VERSION "FL_PT_CANFD"

NS_ :

BS_:

BU_: EMS_ICE EMS_PHEV FLZCU FMCU PDCS1 PDCS2 RMCU RXCU TCU_PHEV TCUR TESTER

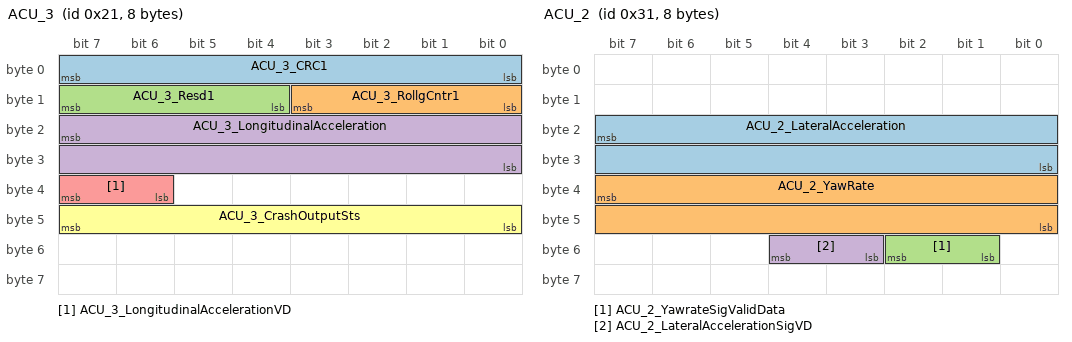
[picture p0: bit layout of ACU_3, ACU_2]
BO_ 33 ACU_3: 8 FLZCU
 SG_ ACU_3_CRC1 : 7|8@0+ (1,0) [0|255] "" RXCU
 SG_ ACU_3_RollgCntr1 : 11|4@0+ (1,0) [0|14] "" RXCU
 SG_ ACU_3_Resd1 : 15|4@0+ (1,0) [0|15] "" RXCU
 SG_ ACU_3_LongitudinalAcceleration : 23|16@0+ (0.001,-2) [-2|2] "g" RXCU
 SG_ ACU_3_LongitudinalAccelerationVD : 39|2@0+ (1,0) [0|3] "" RXCU
 SG_ ACU_3_CrashOutputSts : 47|8@0+ (1,0) [0|255] "" RXCU

BO_ 49 ACU_2: 8 FLZCU
 SG_ ACU_2_LateralAcceleration : 23|16@0+ (0.001,-2) [-2|2] "g" RXCU
 SG_ ACU_2_YawRate : 39|16@0+ (0.01,-180) [-180|180] "deg/sec" RXCU
 SG_ ACU_2_YawrateSigValidData : 50|2@0+ (1,0) [0|3] "" RXCU
 SG_ ACU_2_LateralAccelerationSigVD : 52|2@0+ (1,0) [0|3] "" RXCU

BO_ 152 ONEBOX_1: 24 FLZCU
 SG_ ABS_ESP_1_ABSFailSts : 24|1@0+ (1,0) [0|1] "" RXCU
 SG_ ABS_ESP_1_ABSActive : 41|1@0+ (1,0) [0|1] "" RXCU
 SG_ ABS_ESP_1_VDCFailSts : 42|1@0+ (1,0) [0|1] "" RXCU
 SG_ ABS_ESP_1_VDCActive : 43|1@0+ (1,0) [0|1] "" RXCU
 SG_ ABS_ESP_1_TCSFailSts : 44|1@0+ (1,0) [0|1] "" RXCU
 SG_ ABS_ESP_1_TCSActive : 45|1@0+ (1,0) [0|1] "" RXCU
 SG_ ABS_ESP_1_ESPSwitchStatus : 55|1@0+ (1,0) [0|1] "" RXCU

BO_ 168 ONEBOX_2: 24 FLZCU
 SG_ ONEBOX_2_CRC2 : 71|8@0+ (1,0) [0|255] "" RXCU
 SG_ ONEBOX_2_RollgCntr2 : 75|4@0+ (1,0) [0|14] "" RXCU
 SG_ ONEBOX_2_Resd2 : 79|4@0+ (1,0) [0|15] "" RXCU
 SG_ LHFWheelSpeedRPM : 103|16@0+ (0.0625,0) [0|4095.875] "rpm" RXCU
 SG_ RHFWheelSpeedRPM : 119|16@0+ (0.0625,0) [0|4095.875] "rpm" RXCU
 SG_ ONEBOX_2_CRC3 : 135|8@0+ (1,0) [0|255] "" RXCU
 SG_ ONEBOX_2_RollgCntr3 : 139|4@0+ (1,0) [0|14] "" RXCU
 SG_ ONEBOX_2_Resd3 : 143|4@0+ (1,0) [0|15] "" RXCU
 SG_ LHRWheelSpeedRPM_0A8h : 151|16@0+ (0.0625,0) [0|4095.875] "rpm" RXCU
 SG_ RHRWheelSpeedRPM_0A8h : 167|16@0+ (0.0625,0) [0|4095.875] "rpm" RXCU
 SG_ RHFWheelSpeedRPMValidData : 176|1@0+ (1,0) [0|1] "" RXCU
 SG_ LHFWheelSpeedRPMValidData : 177|1@0+ (1,0) [0|1] "" RXCU
 SG_ RHFWheelDriveDirection_0A8h : 180|3@0+ (1,0) [0|7] "" RXCU
 SG_ LHFWheelDriveDirection_0A8h : 183|3@0+ (1,0) [0|7] "" RXCU
 SG_ RHRWheelSpeedRPMValidData : 184|1@0+ (1,0) [0|1] "" RXCU
 SG_ LHRWheelSpeedRPMValidData : 185|1@0+ (1,0) [0|1] "" RXCU
 SG_ RHRWheelDriveDirection_0A8h : 188|3@0+ (1,0) [0|7] "" RXCU
 SG_ LHRWheelDriveDirection_0A8h : 191|3@0+ (1,0) [0|7] "" RXCU

BO_ 277 HCU_28: 48 RXCU
 SG_ HCU_28_CRC1 : 7|8@0+ (1,0) [0|255] "" FMCU
 SG_ HCU_28_RollgCntr1 : 11|4@0+ (1,0) [0|14] "" FMCU
 SG_ HCU_28_Resd1 : 15|4@0+ (1,0) [0|15] "" FMCU
 SG_ HCU_28_FMCUDesiredTorque : 23|12@0+ (0.25,-500) [-500|500] "Nm" FMCU,TCU_PHEV
 SG_ HCU_28_FMCUMaxTorqueLimit : 27|12@0+ (0.25,-500) [-500|500] "Nm" FMCU,TCU_PHEV
 SG_ HCU_28_FMCUMaxTorqueGradient : 47|14@0+ (32,0) [0|524192] "Nm/s" FMCU,TCU_PHEV
 SG_ HCU_28_EngineTorqAct : 49|10@0+ (0.5,-150) [-150|350] "Nm" FMCU
 SG_ HCU_28_CRC2 : 71|8@0+ (1,0) [0|255] "" FMCU
 SG_ HCU_28_RollgCntr2 : 75|4@0+ (1,0) [0|14] "" FMCU
 SG_ HCU_28_Resd2 : 79|4@0+ (1,0) [0|15] "" FMCU
 SG_ HCU_28_FMCUMinTorqueLimit : 87|12@0+ (0.25,-500) [-500|500] "Nm" FMCU,TCU_PHEV
 SG_ HCU_28_FMCUMaxPwrLimit : 91|12@0+ (0.1,0) [0|400] "kw" FMCU
 SG_ HCU_28_FMCUSpdSet : 111|16@0+ (1,-32767) [-32767|32766] "rpm" FMCU,TCU_PHEV
 SG_ HCU_28_FMCUMaxTorqDampgCtl : 127|8@0+ (1,0) [0|253] "Nm" FMCU,TCU_PHEV
 SG_ HCU_28_CRC3 : 135|8@0+ (1,0) [0|255] "" FMCU
 SG_ HCU_28_RollgCntr3 : 139|4@0+ (1,0) [0|14] "" FMCU
 SG_ HCU_28_Resd3 : 143|4@0+ (1,0) [0|15] "" FMCU
 SG_ HCU_28_FMCUMinPwrLimit : 151|12@0+ (0.1,-400) [-400|0] "kw" FMCU
 SG_ HCU_28_FMCURequestedState : 155|4@0+ (1,0) [0|15] "" FMCU,TCU_PHEV
 SG_ HCU_28_FMCUVehMotstRoadSurf : 167|8@0+ (1,0) [0|15] "" FMCU
 SG_ HCU_28_ISGF_ModeReq : 171|4@0+ (1,0) [0|15] "" FMCU,TCU_PHEV
 SG_ HCU_28_PowertrainModeAct : 175|4@0+ (1,0) [0|15] "" FLZCU,FMCU
 SG_ HCU_28_ISGF_TorqSet : 178|11@0+ (0.25,-255) [-255|255] "Nm" FMCU,TCU_PHEV
 SG_ HCU_28_FMCUDampReq : 179|1@0+ (1,0) [0|1] "" FMCU,TCU_PHEV
 SG_ HCU_28_Mode : 183|4@0+ (1,0) [0|15] "" Vector__XXX
 SG_ HCU_28_CRC4 : 199|8@0+ (1,0) [0|255] "" FMCU
 SG_ HCU_28_RollgCntr4 : 203|4@0+ (1,0) [0|14] "" FMCU
 SG_ HCU_28_Resd4 : 207|4@0+ (1,0) [0|15] "" FMCU
 SG_ HCU_28_ISGF_TorqMax : 215|10@0+ (0.25,0) [0|255] "Nm" FMCU,TCU_PHEV
 SG_ HCU_28_ISGF_TorqMin : 217|10@0+ (0.25,-255) [-255|0] "Nm" FMCU,TCU_PHEV
 SG_ HCU_28_EngineSts : 218|1@0+ (1,0) [0|1] "" FMCU
 SG_ HCU_28_SleepAllow : 219|1@0+ (1,0) [0|1] "" FMCU
 SG_ HCU_28_ISGF_DampReq : 220|1@0+ (1,0) [0|1] "" FMCU,TCU_PHEV
 SG_ HCU_28_bEnaEmReq : 221|1@0+ (1,0) [0|1] "" FMCU
 SG_ HCU_28_ISGF_SpdSet : 239|16@0+ (1,-32767) [-32767|32766] "rpm" FMCU,TCU_PHEV
 SG_ HCU_28_ISGF_MaxTorqDampgCtl : 255|8@0+ (1,0) [0|253] "Nm" FMCU,TCU_PHEV
 SG_ HCU_28_CRC5 : 263|8@0+ (1,0) [0|255] "" FMCU
 SG_ HCU_28_RollgCntr5 : 267|4@0+ (1,0) [0|14] "" FMCU
 SG_ HCU_28_Resd5 : 271|4@0+ (1,0) [0|15] "" FMCU
 SG_ HCU_28_NGenrMaxInTqMode : 279|16@0+ (1,-32767) [-32767|32766] "rpm" FMCU
 SG_ HCU_28_ISGF_MaxTorqGradient : 295|14@0+ (32,0) [0|524192] "" FMCU,TCU_PHEV
 SG_ HCU_28_ISGF_Uset : 297|10@0+ (1,0) [0|1021] "V" FMCU
 SG_ HCU_28_ISGF_LimpPwrReq : 319|8@0+ (0.1,0) [0|20] "KW" FMCU
 SG_ HCU_28_CRC6 : 327|8@0+ (1,0) [0|255] "" FMCU
 SG_ HCU_28_RollgCntr6 : 331|4@0+ (1,0) [0|14] "" FMCU
 SG_ HCU_28_Resd6 : 335|4@0+ (1,0) [0|15] "" FMCU
 SG_ HCU_28_ISGF_Iset : 343|11@0+ (1,-1023) [-1023|1021] "A" FMCU
 SG_ HCU_28_MaxDisCurrent_ISGF : 348|15@0+ (0.05,0) [0|1023] "A" FMCU
 SG_ HCU_28_MaxCharCurrent_ISGF : 365|15@0+ (0.05,-1023) [-1023|0] "A" FMCU
 SG_ HCU_FMCUBoostReq : 378|2@0+ (1,0) [0|3] "" FMCU
 SG_ HCU_P3_TorqueAllowed : 379|1@0+ (1,0) [0|1] "" FMCU
 SG_ HCU_P1_TorqueAllowed : 380|1@0+ (1,0) [0|1] "" FMCU
 SG_ HCU_28_NeutralGearSlide : 381|1@0+ (1,0) [0|1] "" FMCU
 SG_ HCU_28_FMCU_LimpReq : 382|1@0+ (1,0) [0|1] "" FMCU

BO_ 279 HCU_29: 64 RXCU
 SG_ HCU_29_CRC1 : 7|8@0+ (1,0) [0|255] "" RMCU,TCUR
 SG_ HCU_29_RollgCntr1 : 11|4@0+ (1,0) [0|14] "" RMCU,TCUR
 SG_ HCU_29_Resd1 : 15|4@0+ (1,0) [0|15] "" RMCU,TCUR
 SG_ HCU_29_RMCUDesiredTorque : 23|12@0+ (0.25,-500) [-500|500] "Nm" RMCU,TCUR
 SG_ HCU_29_RMCUMaxTorqueLimit : 27|12@0+ (0.25,-500) [-500|500] "Nm" RMCU
 SG_ HCU_29_RMCUMaxTorqueGradient : 47|14@0+ (32,0) [0|524192] "Nm/s" Vector__XXX
 SG_ HCU_29_LowPwrReq : 48|1@0+ (1,0) [0|1] "" RMCU
 SG_ HCU_29_RMCUDrvHeatReq : 49|1@0+ (1,0) [0|1] "" RMCU
 SG_ HCU_29_RMCUVehMotstRoadSurf : 63|8@0+ (1,0) [0|15] "" Vector__XXX
 SG_ HCU_29_CRC2 : 71|8@0+ (1,0) [0|255] "" RMCU,TCUR
 SG_ HCU_29_RollgCntr2 : 75|4@0+ (1,0) [0|14] "" RMCU,TCUR
 SG_ HCU_29_Resd2 : 79|4@0+ (1,0) [0|15] "" RMCU,TCUR
 SG_ HCU_29_RMCUMinTorqueLimit : 87|12@0+ (0.25,-500) [-500|500] "Nm" RMCU
 SG_ HCU_29_RMCUMaxPwrLimit : 91|12@0+ (0.1,0) [0|400] "kw" Vector__XXX
 SG_ HCU_RMCU_ActiveHeatHvDcFreqReq : 111|11@0+ (1,0) [0|1500] "Hz" RMCU
 SG_ HCU_29_RearEDLReq : 115|3@0+ (1,0) [0|7] "" RMCU
 SG_ HCU_P4_TorqueAllowed : 116|1@0+ (1,0) [0|1] "" RMCU
 SG_ HCU_29_RMCUMaxTorqueDampgCtl_Res : 127|8@0+ (1,0) [0|253] "Nm" RMCU
 SG_ HCU_29_CRC3 : 135|8@0+ (1,0) [0|255] "" RMCU,TCUR
 SG_ HCU_29_RollgCntr3 : 139|4@0+ (1,0) [0|14] "" RMCU,TCUR
 SG_ HCU_29_Resd3 : 143|4@0+ (1,0) [0|15] "" RMCU,TCUR
 SG_ HCU_29_RMCUSpdSet : 151|16@0+ (1,-32767) [-32767|32766] "rpm" RMCU
 SG_ HCU_29_RMCUMinPwrLimit : 167|12@0+ (0.1,-400) [-400|0] "kw" Vector__XXX
 SG_ HCU_29_RMCURequestedState : 171|4@0+ (1,0) [0|15] "" RMCU
 SG_ HCU_29_RMCUBoostPwrReq : 183|11@0+ (0.1,0) [0|200] "kw" RMCU
 SG_ HCU_RMCU_LimpReq : 184|1@0+ (1,0) [0|1] "" RMCU
 SG_ HCU_29_RMCUDampReq : 185|1@0+ (1,0) [0|1] "" RMCU
 SG_ HCU_29_RMCUBoostStateReq : 188|3@0+ (1,0) [0|7] "" RMCU
 SG_ HCU_29_CRC4 : 199|8@0+ (1,0) [0|255] "" RMCU,TCUR
 SG_ HCU_29_RollgCntr4 : 203|4@0+ (1,0) [0|14] "" RMCU,TCUR
 SG_ HCU_29_Resd4 : 207|4@0+ (1,0) [0|15] "" RMCU,TCUR
 SG_ HCU_29_RMCU_RequestGear : 209|2@0+ (1,0) [0|3] "" RMCU,TCUR
 SG_ HCU_29_RMCUHeatPwrLimit : 215|6@0+ (0.1,0) [0|5] "Kw" RMCU
 SG_ HCU_RMCU_ActiveHeatHvDcAmpReq : 222|11@0+ (0.25,0) [0|300] "A" RMCU
 SG_ HCU_29_RMCU_ShiftingRequest : 223|1@0+ (1,0) [0|1] "" RMCU,TCUR
 SG_ HCU_RMCU_ActiveHeatHvDcAmpHiLim : 227|11@0+ (0.25,0) [0|300] "A" RMCU
 SG_ HCU_RMCU_ActiveHeatHvDcAmpLoLim : 232|11@0+ (0.25,0) [0|300] "A" RMCU
 SG_ HCU_29_CRC5 : 263|8@0+ (1,0) [0|255] "" Vector__XXX
 SG_ HCU_29_RollgCntr5 : 267|4@0+ (1,0) [0|14] "" Vector__XXX
 SG_ HCU_29_Resd5 : 271|4@0+ (1,0) [0|15] "" Vector__XXX
 SG_ HCU_RMCU_ActiveHeatHvDFreqHiLim : 276|11@0+ (1,0) [0|1500] "Hz" RMCU
 SG_ HCU_29_ADSRMCUTqUnloadEna : 278|2@0+ (1,0) [0|3] "" RMCU,TCUR
 SG_ HCU_RMCU_ActiveHeatHvDcFreqLoLim : 281|11@0+ (1,0) [0|1500] "Hz" RMCU
 SG_ HCU_BMSVehDcChrgnIDmd : 302|14@0+ (0.1,-1024) [-1024|0] "ampere (A)" RMCU
 SG_ HCU_29_NeutralGearSlide : 304|1@0+ (1,0) [0|1] "" RMCU
 SG_ HCU_29_CRC6 : 327|8@0+ (1,0) [0|255] "" Vector__XXX
 SG_ HCU_29_RollgCntr6 : 331|4@0+ (1,0) [0|14] "" Vector__XXX
 SG_ HCU_29_Resd6 : 335|4@0+ (1,0) [0|15] "" Vector__XXX
 SG_ HCU_BMSVehDcChrgnUDmd : 343|14@0+ (0.1,0) [0|1024] "volt (V)" RMCU
 SG_ HCU_DCB_InputVolt : 345|16@0+ (0.05,0) [0|1000] "V" RMCU
 SG_ HCU_DCB_BoostNegRelaySts : 361|3@0+ (1,0) [0|7] "" RMCU
 SG_ HCU_DCB_BoostPosRelaySts : 371|3@0+ (1,0) [0|7] "" RMCU
 SG_ HCU_DCB_C2RelaySts : 374|3@0+ (1,0) [0|7] "" RMCU
 SG_ HCU_29_CRC7 : 391|8@0+ (1,0) [0|255] "" FMCU,RMCU
 SG_ HCU_29_RollgCntr7 : 395|4@0+ (1,0) [0|14] "" FMCU,RMCU
 SG_ HCU_29_Resd7 : 399|4@0+ (1,0) [0|15] "" FMCU,RMCU
 SG_ HCU_29_RMCUDesiredFFTorque : 421|12@0+ (0.25,-500) [-500|500] "Nm" RMCU
 SG_ HCU_29_FMCUDesiredFFTorque : 425|12@0+ (0.25,-500) [-500|500] "Nm" FMCU

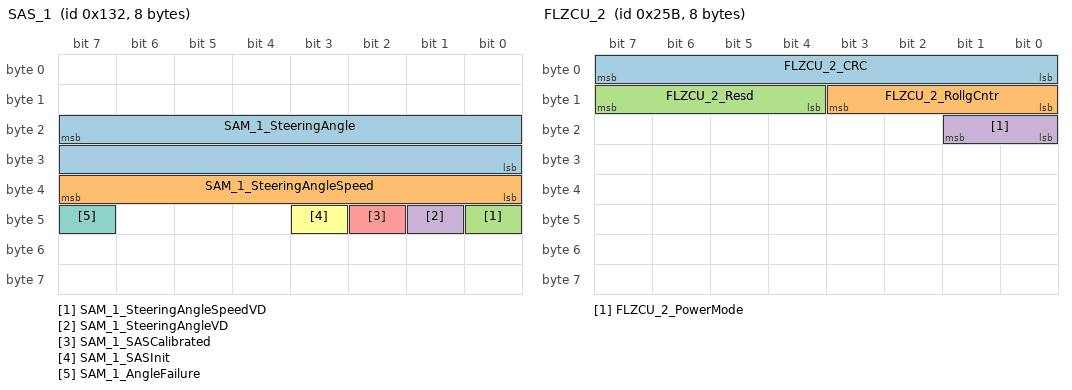
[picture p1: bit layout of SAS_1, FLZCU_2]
BO_ 306 SAS_1: 8 FLZCU
 SG_ SAM_1_SteeringAngle : 23|16@0+ (0.0625,-2048) [-2048|2047.875] "deg" RXCU
 SG_ SAM_1_SteeringAngleSpeed : 39|8@0+ (4,0) [0|1016] "deg/Sec" RXCU
 SG_ SAM_1_SteeringAngleSpeedVD : 40|1@0+ (1,0) [0|1] "" RXCU
 SG_ SAM_1_SteeringAngleVD : 41|1@0+ (1,0) [0|1] "" RXCU
 SG_ SAM_1_SASCalibrated : 42|1@0+ (1,0) [0|1] "" RXCU
 SG_ SAM_1_SASInit : 43|1@0+ (1,0) [0|1] "" RXCU
 SG_ SAM_1_AngleFailure : 47|1@0+ (1,0) [0|1] "" RXCU

BO_ 322 RMCU_7: 16 RXCU
 SG_ RMCU_TCUR_ShiftGearOperSt : 3|4@0+ (1,0) [0|15] "" Vector__XXX
 SG_ TCUR_GearSt : 7|4@0+ (1,0) [0|15] "" Vector__XXX
 SG_ RMCU_TCUR_ShiftGearReq : 10|3@0+ (1,0) [0|7] "" Vector__XXX
 SG_ RMCU_TCUR_RdToSleep : 11|1@0+ (1,0) [0|1] "" Vector__XXX
 SG_ RMCU_GbxStMac : 15|4@0+ (1,0) [0|15] "" Vector__XXX
 SG_ TCUR_GearPosnMeasRaw : 23|8@0+ (1,0) [0|100] "" Vector__XXX
 SG_ TCUR_SleepComfirm : 25|1@0+ (1,0) [0|1] "" Vector__XXX
 SG_ RMCU_MCUGearShiftAllwFlg : 26|1@0+ (1,0) [0|1] "" Vector__XXX
 SG_ TCUR_ActrOperSt : 31|5@0+ (1,0) [0|31] "" Vector__XXX

BO_ 419 HCU_26: 48 RXCU
 SG_ HCU_26_CRC1 : 7|8@0+ (1,0) [0|255] "" EMS_PHEV,TCU_PHEV
 SG_ HCU_26_RollgCntr1 : 11|4@0+ (1,0) [0|14] "" EMS_PHEV,TCU_PHEV
 SG_ HCU_ENG_TorqueAllowed : 12|1@0+ (1,0) [0|1] "" EMS_PHEV
 SG_ HCU_26_TargetGearTransInp : 18|3@0+ (1,0) [0|7] "" TCU_PHEV
 SG_ HCU_26_OptMode : 21|3@0+ (1,0) [0|7] "" TCU_PHEV
 SG_ HCU_26_TargetGearEM2 : 23|2@0+ (1,0) [0|3] "" TCU_PHEV
 SG_ PowertrainModeDes : 27|4@0+ (1,0) [0|15] "" EMS_PHEV,TCU_PHEV
 SG_ HCU_26_FrntEDLReq : 30|3@0+ (1,0) [0|7] "" FMCU,TCU_PHEV
 SG_ HCU_26_InputClutchIntervention : 31|1@0+ (1,0) [0|1] "" TCU_PHEV
 SG_ GasPedalPosition : 39|8@0+ (0.392,0) [0|99.568] "" EMS_PHEV,FMCU,RMCU,TCU_PHEV,TCUR
 SG_ BrakePedalStsValidDataForTCU : 40|1@0+ (1,0) [0|1] "" EMS_PHEV,FMCU,RMCU,TCU_PHEV,TCUR
 SG_ BrakePedalStsForTCU : 41|1@0+ (1,0) [0|1] "" EMS_PHEV,FMCU,RMCU,TCU_PHEV,TCUR
 SG_ GasPedalPositionInvalidData : 42|1@0+ (1,0) [0|1] "" EMS_PHEV,FMCU,RMCU,TCU_PHEV,TCUR
 SG_ TargetGearTransInp : 45|3@0+ (1,0) [0|7] "" TCU_PHEV
 SG_ HCU_26_ADSFMCUTqUnloadEna : 47|2@0+ (1,0) [0|3] "" FMCU
 SG_ HCU_TMCU_EmsTqReqSlow : 55|11@0+ (0.5,-510) [-510|513] "Nm" TCU_PHEV
 SG_ HCU_26_EMS_FuelcutReq : 56|1@0+ (1,0) [0|1] "" TCU_PHEV
 SG_ HCU_TMCU_CntrAllowMode : 60|4@0+ (1,0) [0|15] "" TCU_PHEV
 SG_ HCU_26_CRC2 : 71|8@0+ (1,0) [0|255] "" Vector__XXX
 SG_ HCU_26_RollgCntr2 : 75|4@0+ (1,0) [0|14] "" Vector__XXX
 SG_ HCU_26_Resd2 : 79|4@0+ (1,0) [0|15] "" Vector__XXX
 SG_ HCU_26_IndicatedDriverReqWhlTqFA : 87|16@0+ (1,-32768) [-32768|32767] "Nm" TCU_PHEV
 SG_ HCU_26_ActWheelTorqueFA : 103|16@0+ (1,-32768) [-32768|32767] "Nm" TCU_PHEV
 SG_ HCU_26_ActWheelTorqueRA : 119|16@0+ (1,-32768) [-32768|32767] "NM" TCU_PHEV
 SG_ HCU_26_CRC3 : 135|8@0+ (1,0) [0|255] "" Vector__XXX
 SG_ HCU_26_RollgCntr3 : 139|4@0+ (1,0) [0|14] "" Vector__XXX
 SG_ HCU_26_Resd3 : 143|4@0+ (1,0) [0|15] "" Vector__XXX
 SG_ HCU_AccessoriesCosumePower : 151|14@0+ (0.01,0) [0|100] "KW" Vector__XXX
 SG_ HCU_26_PRNDGearTargetValidData : 152|1@0+ (1,0) [0|1] "" FMCU,TCU_PHEV
 SG_ HCU_26_PRNDGearActValidData : 153|1@0+ (1,0) [0|1] "" FMCU
 SG_ HCU_26_TransInpTarSpd : 167|16@0+ (1,-32767) [-32767|32767] "" TCU_PHEV
 SG_ HCU_26_ADSFMCUTqUnloadRate : 183|9@0+ (50,-12750) [-12750|12800] "Nm/s" FMCU
 SG_ HCU_RearEDDReq_1A3h : 190|2@0+ (1,0) [0|3] "" RMCU
 SG_ HCU_26_TransInpActSpd : 215|16@0+ (1,-32767) [-32767|32767] "" TCU_PHEV
 SG_ HCU_26_TransEM1TrqTar : 231|12@0+ (0.5,-848) [-848|1199] "" TCU_PHEV
 SG_ HCU_26_C1CapacityTarget : 235|12@0+ (0.5,-848) [-848|1199] "" TCU_PHEV
 SG_ HCU_26_PRNDGearTarget : 250|3@0+ (1,0) [0|7] "" TCU_PHEV
 SG_ HCU_26_PRNDGearAct : 253|3@0+ (1,0) [0|7] "" TCU_PHEV
 SG_ HCU_26_ShiftUrgency : 255|2@0+ (1,0) [0|3] "" TCU_PHEV
 SG_ HCU_26_TransInpTrqAct : 279|12@0+ (0.5,-848) [-848|1199] "" TCU_PHEV
 SG_ HCU_26_TransInpTrqTar : 283|12@0+ (0.5,-848) [-848|1199] "" TCU_PHEV
 SG_ HCU_26_TransInpTrqMin : 303|12@0+ (0.5,-848) [-848|1199] "" TCU_PHEV
 SG_ HCU_26_EM2TrqTar : 307|12@0+ (0.5,-848) [-848|1199] "" TCU_PHEV
 SG_ HCU_26_ADSFMCUMotTqRateLimMin : 343|9@0+ (50,-12750) [-12750|12800] "Nm/s" FMCU
 SG_ HCU_26_ADSFMCUMotTqRateLimMax : 350|9@0+ (50,-12750) [-12750|12800] "Nm/s" FMCU
 SG_ HCU_26_Activeheat : 357|1@0+ (1,0) [0|1] "" FMCU
 SG_ HCU_26_ECGPOvrd : 360|1@0+ (1,0) [0|1] "" TCU_PHEV
 SG_ HCU_26_ErrorMotorSpeedRA : 361|1@0+ (1,0) [0|1] "" TCU_PHEV
 SG_ HCU_26_EpsOnReq : 362|1@0+ (1,0) [0|1] "" TCU_PHEV
 SG_ HCU_26_C1CapacityState : 364|2@0+ (1,0) [0|3] "" TCU_PHEV
 SG_ HCU_26_EngineStartType : 367|3@0+ (1,0) [0|7] "" TCU_PHEV
 SG_ HCU_26_FMCUMaxActiveheatPwr : 374|7@0+ (0.1,0) [0|11.1] "KW" FMCU
 SG_ HCU_26_ECGPOvrdInvalidData : 375|1@0+ (1,0) [0|1] "" TCU_PHEV

BO_ 474 FMCU_8: 64 FMCU
 SG_ FMCU_8_CRC1 : 7|8@0+ (1,0) [0|255] "" RXCU
 SG_ FMCU_8_RollgCntr1 : 11|4@0+ (1,0) [0|14] "" RXCU
 SG_ FMCU_8_Resd1 : 15|4@0+ (1,0) [0|15] "" RXCU
 SG_ FMCU_8_TorqMax : 23|12@0+ (0.25,0) [0|400] "Nm" RXCU
 SG_ FMCU_8_TorqMin : 27|12@0+ (0.25,-400) [-400|0] "Nm" RXCU
 SG_ FMCU_8_TorqAct : 47|12@0+ (0.25,-400) [-400|400] "Nm" RXCU
 SG_ FMCU_8ModeSt : 51|4@0+ (1,0) [0|15] "" RXCU
 SG_ FMCU_8_FMCUDeratSts : 59|4@0+ (1,0) [0|15] "" RXCU
 SG_ FMCU_8_ErrLvl : 62|3@0+ (1,0) [0|7] "" RXCU
 SG_ FMCU_8_DampActive : 63|1@0+ (1,0) [0|1] "" RXCU
 SG_ FMCU_8_CRC2 : 71|8@0+ (1,0) [0|255] "" RXCU
 SG_ FMCU_8_RollgCntr2 : 75|4@0+ (1,0) [0|14] "" RXCU
 SG_ FMCU_8_Resd2 : 79|4@0+ (1,0) [0|15] "" RXCU
 SG_ FMCU_8_SpdAct : 87|16@0+ (1,-32767) [-32767|32766] "rpm" RXCU
 SG_ FMCU_8_TrqActDampingReq : 103|12@0+ (0.25,-350) [-350|350] "Nm" RXCU
 SG_ FMCU_8_UdcAct : 107|10@0+ (1,0) [0|1021] "V" RXCU
 SG_ FMCU_8_ISGF_DampActive : 112|1@0+ (1,0) [0|1] "" RXCU
 SG_ FMCU_8_InterlockStatus : 113|1@0+ (1,0) [0|1] "" RXCU
 SG_ FMCU_8_ISGF_ErrLvl : 123|4@0+ (1,0) [0|15] "" RXCU
 SG_ FMCU_8_ISGF_ModeSt : 127|4@0+ (1,0) [0|15] "" RXCU
 SG_ FMCU_8_CRC3 : 135|8@0+ (1,0) [0|255] "" RXCU
 SG_ FMCU_8_RollgCntr3 : 139|4@0+ (1,0) [0|14] "" RXCU
 SG_ FMCU_8_Resd3 : 143|4@0+ (1,0) [0|15] "" RXCU
 SG_ FMCU_8_IdcAct : 151|11@0+ (1,-1023) [-1023|1021] "A" RXCU
 SG_ FMCU_8_ISGF_SpdAct : 156|16@0+ (1,-32767) [-32767|32766] "rpm" RXCU
 SG_ FMCU_8_ISGF_TorqMax : 172|10@0+ (0.25,0) [0|255] "Nm" RXCU
 SG_ FMCU_8_ISGF_TorqAct : 178|11@0+ (0.25,-255) [-255|255] "Nm" RXCU
 SG_ FMCU_8_CRC4 : 199|8@0+ (1,0) [0|255] "" RXCU
 SG_ FMCU_8_RollgCntr4 : 203|4@0+ (1,0) [0|14] "" RXCU
 SG_ FMCU_8_Resd4 : 207|4@0+ (1,0) [0|15] "" RXCU
 SG_ FMCU_8_ISGF_TorqMin : 215|10@0+ (0.25,-255) [-255|0] "Nm" RXCU
 SG_ FMCU_8_ISGF_IdcAct : 221|11@0+ (1,-1023) [-1023|1021] "A" RXCU
 SG_ FMCU_8_ISGF_UdcAct : 236|10@0+ (1,0) [0|1021] "V" RXCU
 SG_ FMCU_8_ActiveheatReq : 240|1@0+ (1,0) [0|1] "" RXCU
 SG_ FMCU_8_ISGF_DischargeState : 242|2@0+ (1,0) [0|3] "" RXCU
 SG_ FMCU_8_CRC5 : 263|8@0+ (1,0) [0|255] "" RXCU
 SG_ FMCU_8_RollgCntr5 : 267|4@0+ (1,0) [0|14] "" RXCU
 SG_ FMCU_8_Resd5 : 271|4@0+ (1,0) [0|15] "" RXCU
 SG_ FMCU_8_ISGF_TrqActDampingReq : 279|11@0+ (0.25,-255) [-255|255] "Nm" RXCU
 SG_ FMCU_8_ISGF_GateDrvSt : 284|2@0+ (1,0) [0|3] "" RXCU
 SG_ FMCU_8_LimpAllow : 312|1@0+ (1,0) [0|1] "" RXCU
 SG_ FMCU_8_Limp : 313|1@0+ (1,0) [0|1] "" RXCU
 SG_ FMCU_8_CRC6 : 327|8@0+ (1,0) [0|255] "" RXCU
 SG_ FMCU_8_RollgCntr6 : 331|4@0+ (1,0) [0|14] "" RXCU
 SG_ FMCU_8_Resd6 : 335|4@0+ (1,0) [0|15] "" RXCU
 SG_ FMCU_8_InvTemp : 343|8@0+ (1,-40) [-40|213] "oC" RXCU
 SG_ FMCU_8_ISGF_InvTemp : 351|8@0+ (1,-40) [-40|213] "oC" RXCU
 SG_ FMCU_8_MCUActRUnfilteredRodSpd : 359|16@0+ (1,-30000) [-30000|35535] "RPM" RXCU
 SG_ FMCU_8_MCUReqTq : 375|13@0+ (0.25,-800) [-800|800] "Nm" RXCU
 SG_ FMCU_8_MCUModActvSt : 377|2@0+ (1,0) [0|3] "" RXCU
 SG_ FMCU_8_SpdSvModAvl : 378|1@0+ (1,0) [0|1] "" RXCU
 SG_ FMCU_E_ClutchStus : 397|2@0+ (1,0) [0|3] "" RXCU
 SG_ FMCU_E_ClutchEngMilLampReq : 399|2@0+ (1,0) [0|3] "" RXCU
 SG_ FMCU_8_MCUSpdSVModFlt : 402|3@0+ (1,0) [0|7] "" RXCU
 SG_ FMCU_8_MCUVehSldSt : 403|1@0+ (1,0) [0|1] "" RXCU
 SG_ FMCU_8_MCUStandstill : 404|1@0+ (1,0) [0|1] "" RXCU
 SG_ FMCU_8_MCUBlkSt : 407|3@0+ (1,0) [0|7] "" RXCU
 SG_ FMCU_8_ISGActRUnfilteredRodSpd : 415|16@0+ (1,-30000) [-30000|35535] "RPM" RXCU
 SG_ FMCU_8_ISGReqTq : 431|13@0+ (0.25,-800) [-800|800] "Nm" RXCU
 SG_ FMCU_8_ISGModActvSt : 433|2@0+ (1,0) [0|3] "" RXCU
 SG_ FMCU_8_ISGSpdSvModAvl : 434|1@0+ (1,0) [0|1] "" RXCU
 SG_ FMCU_8_ISGSpdSVModFlt : 442|3@0+ (1,0) [0|7] "" RXCU
 SG_ FMCU_8_ISGVehSldSt : 443|1@0+ (1,0) [0|1] "" RXCU
 SG_ FMCU_8_ISGStandstill : 444|1@0+ (1,0) [0|1] "" RXCU
 SG_ FMCU_8_ISGBlkSt : 447|3@0+ (1,0) [0|7] "" RXCU
 SG_ FMCU_E_ClutchErrLvl : 462|3@0+ (1,0) [0|7] "" RXCU
 SG_ FMCU_8_MCU_SpdActValidData : 464|1@0+ (1,0) [0|1] "" RXCU
 SG_ FMCU_8_ActiveheatPwrAct : 471|7@0+ (0.1,0) [0|11.1] "KW" RXCU
 SG_ FMCU_E_ClutchCurr : 472|10@0+ (0.01,0) [0|10] "" RXCU
 SG_ FMCU_E_ClutchActMod : 475|3@0+ (1,0) [0|7] "" RXCU
 SG_ FMCU_8_ISGF_PositionCtrSts : 478|3@0+ (1,0) [0|7] "" RXCU
 SG_ FMCU_8_ISGF_SpdAcValidData : 479|1@0+ (1,0) [0|1] "" RXCU
 SG_ ECluAvlTq : 494|10@0+ (0.5,0) [0|511] "Nm" RXCU

BO_ 485 RMCU_1: 48 RXCU
 SG_ RMCU_1_CRC1 : 7|8@0+ (1,0) [0|255] "" FLZCU,PDCS1,PDCS2
 SG_ RMCU_1_RollgCntr1 : 11|4@0+ (1,0) [0|14] "" FLZCU,PDCS1,PDCS2
 SG_ RMCU_1_Resd1 : 15|4@0+ (1,0) [0|15] "" FLZCU,PDCS1,PDCS2
 SG_ RMCU_MaxTorque : 23|12@0+ (0.25,0) [0|500] "Nm" FLZCU,PDCS1,PDCS2
 SG_ RMCU_MinTorque : 27|12@0+ (0.25,-500) [-500|0] "Nm" FLZCU,PDCS1,PDCS2
 SG_ RMCU_1_OutputTorque : 47|12@0+ (0.25,-500) [-500|500] "Nm" FLZCU,PDCS1,PDCS2
 SG_ RMCU_State : 51|4@0+ (1,0) [0|15] "" FLZCU,PDCS1,PDCS2
 SG_ RMCU_1_InverterTemperature : 63|8@0+ (1,-40) [-40|213] "oC" FLZCU,PDCS1,PDCS2
 SG_ RMCU_1_CRC2 : 71|8@0+ (1,0) [0|255] "" FLZCU,PDCS1,PDCS2
 SG_ RMCU_1_RollgCntr2 : 75|4@0+ (1,0) [0|14] "" FLZCU,PDCS1,PDCS2
 SG_ RMCU_1_Resd2 : 79|4@0+ (1,0) [0|15] "" FLZCU,PDCS1,PDCS2
 SG_ RMCU_TrqActDampingReq : 87|12@0+ (0.25,-500) [-500|500] "Nm" FLZCU,PDCS1,PDCS2
 SG_ RMCU_RMCUDeratSts : 91|4@0+ (1,0) [0|15] "" FLZCU,PDCS1,PDCS2
 SG_ RMCU_1_VoltageHV : 103|10@0+ (1,0) [0|1021] "V" FLZCU,PDCS1,PDCS2
 SG_ RMCU_ElockWorkStatusAct : 107|4@0+ (1,0) [0|15] "" FLZCU,PDCS1,PDCS2
 SG_ RMCU_1_MCU_SpdActValidData : 109|1@0+ (1,0) [0|1] "" FLZCU,PDCS1,PDCS2
 SG_ RMCU_1_Speed : 119|16@0+ (1,-32767) [-32767|32766] "rpm" FLZCU,PDCS1,PDCS2
 SG_ RMCU_1_CRC3 : 135|8@0+ (1,0) [0|255] "" FLZCU,PDCS1,PDCS2
 SG_ RMCU_1_RollgCntr3 : 139|4@0+ (1,0) [0|14] "" FLZCU,PDCS1,PDCS2
 SG_ RMCU_1_Resd3 : 143|4@0+ (1,0) [0|15] "" FLZCU,PDCS1,PDCS2
 SG_ RMCU_1_MAXBoostPwr : 151|10@0+ (0.25,0) [0|130] "KW" FLZCU,PDCS1,PDCS2
 SG_ RMCU_ErrLvl : 154|3@0+ (1,0) [0|7] "" FLZCU,PDCS1,PDCS2
 SG_ RMCU_1_BoostSts : 157|3@0+ (1,0) [0|7] "" FLZCU,PDCS1,PDCS2
 SG_ RMCU_1_CurrentHV : 167|11@0+ (1,-1023) [-1023|1021] "A" FLZCU,PDCS1,PDCS2
 SG_ RMCU_HeatPwrAct : 172|9@0+ (0.1,0) [0|5] "Kw" FLZCU,PDCS1,PDCS2
 SG_ RMCU_MAXHeatPwr : 179|9@0+ (0.1,0) [0|5] "Kw" FLZCU,PDCS1,PDCS2
 SG_ RMCU_DampActive : 184|1@0+ (1,0) [0|1] "" FLZCU,PDCS1,PDCS2
 SG_ RMCU_InterlockStatus : 185|1@0+ (1,0) [0|1] "" FLZCU,PDCS1,PDCS2
 SG_ RMCU_1_SpdSvModAvl : 186|1@0+ (1,0) [0|1] "" FLZCU,PDCS1,PDCS2
 SG_ RMCU_1_CRC4 : 199|8@0+ (1,0) [0|255] "" FLZCU,PDCS1,PDCS2
 SG_ RMCU_1_RollgCntr4 : 203|4@0+ (1,0) [0|14] "" FLZCU,PDCS1,PDCS2
 SG_ RMCU_1_Resd4 : 207|4@0+ (1,0) [0|15] "" FLZCU,PDCS1,PDCS2
 SG_ RMCU_1_MCUModActvSt : 209|2@0+ (1,0) [0|3] "" FLZCU,PDCS1,PDCS2
 SG_ RMCU_1_BSTNRelayReqAct : 212|3@0+ (1,0) [0|7] "" FLZCU,PDCS1,PDCS2
 SG_ RMCU_1_BSTPRelayReqAct : 215|3@0+ (1,0) [0|7] "" FLZCU,PDCS1,PDCS2
 SG_ RMCU_1_MCUStandstill : 216|1@0+ (1,0) [0|1] "" FLZCU,PDCS1,PDCS2
 SG_ RMCU_1_MCUVehSldSt : 217|1@0+ (1,0) [0|1] "" FLZCU,PDCS1,PDCS2
 SG_ RMCU_1_BoostErrLvl : 220|3@0+ (1,0) [0|7] "" FLZCU,PDCS1,PDCS2
 SG_ RMCU_1_BSTPrechargeRelayAct : 223|3@0+ (1,0) [0|7] "" FLZCU,PDCS1,PDCS2
 SG_ RMCU_1_NeutralGearUnavailable : 224|1@0+ (1,0) [0|1] "" FLZCU,PDCS1,PDCS2
 SG_ RMCU_1_GearShiftProgFlag : 226|2@0+ (1,0) [0|3] "" FLZCU,PDCS1,PDCS2
 SG_ RMCU_1_GearShiftAllw : 227|1@0+ (1,0) [0|1] "" FLZCU,PDCS1,PDCS2
 SG_ RMCU_1_CurrGear : 231|4@0+ (1,0) [0|15] "" FLZCU,PDCS1,PDCS2
 SG_ RMCU_1_GearSelfStudySts : 234|3@0+ (1,0) [0|7] "" FLZCU,PDCS1,PDCS2
 SG_ RMCU_1_TCURErrLvlDis : 237|3@0+ (1,0) [0|7] "" FLZCU,PDCS1,PDCS2
 SG_ RMCU_1_2ndGearUnavailable : 238|1@0+ (1,0) [0|1] "" FLZCU,PDCS1,PDCS2
 SG_ RMCU_1_1stGearUnavailable : 239|1@0+ (1,0) [0|1] "" FLZCU,PDCS1,PDCS2
 SG_ RMCU_1_MCUActRUnfilteredRodSpd : 247|16@0+ (1,-30000) [-30000|35535] "RPM" FLZCU,PDCS1,PDCS2
 SG_ RMCU_1_CRC5 : 263|8@0+ (1,0) [0|255] "" Vector__XXX
 SG_ RMCU_1_RollgCntr5 : 267|4@0+ (1,0) [0|14] "" Vector__XXX
 SG_ RMCU_1_ActiveHeatHvDcAmpAct : 277|11@0+ (0.25,0) [0|300] "A" FLZCU,PDCS1,PDCS2
 SG_ RMCU_1_LimpAllow : 278|1@0+ (1,0) [0|1] "" FLZCU,PDCS1,PDCS2
 SG_ RMCU_1_ShiftReqProtd : 279|1@0+ (1,0) [0|1] "" FLZCU,PDCS1,PDCS2
 SG_ RMCU_1_ActiveHeatHvDcFreqAct : 282|11@0+ (1,0) [0|1500] "Hz" FLZCU,PDCS1,PDCS2
 SG_ RMCU_1_MCUReqTq : 303|13@0+ (0.25,-800) [-800|800] "Nm" FLZCU,PDCS1,PDCS2
 SG_ RMCU_1_MCUBlkSt : 306|3@0+ (1,0) [0|7] "" FLZCU,PDCS1,PDCS2
 SG_ RMCU_GBFaultstatus : 313|2@0+ (1,0) [0|3] "" FLZCU
 SG_ RMCU_1_RotorPosition : 315|2@0+ (1,0) [0|3] "" FLZCU,PDCS1,PDCS2
 SG_ RMCU_1_MCUSpdSVModFlt : 318|3@0+ (1,0) [0|7] "" FLZCU,PDCS1,PDCS2
 SG_ RMCU_1_CRC6 : 327|8@0+ (1,0) [0|255] "" Vector__XXX
 SG_ RMCU_1_RollgCntr6 : 331|4@0+ (1,0) [0|14] "" Vector__XXX
 SG_ RMCU_EDD_RearEDDStMac : 336|4@0+ (1,0) [0|15] "" Vector__XXX
 SG_ RMCU_EDD_RearEDDOperSt : 340|4@0+ (1,0) [0|15] "" Vector__XXX
 SG_ RMCU_EDD_RearEDDSts : 343|3@0+ (1,0) [0|7] "" PDCS1,PDCS2
 SG_ RMCU_EDD_RearEDDFaultCode : 348|6@0+ (1,0) [0|63] "" Vector__XXX
 SG_ RMCU_EDD_RearEDDCnctDisAllwReas : 353|3@0+ (1,0) [0|7] "" Vector__XXX
 SG_ RMCU_EDD_RearEDDConnectAllwFlg : 355|2@0+ (1,0) [0|3] "" PDCS1,PDCS2
 SG_ RMCU_EDD_RearEDDErrLvlDis : 358|3@0+ (1,0) [0|7] "" Vector__XXX
 SG_ RMCU_EDD_RearEDDPosnMeasRaw : 366|8@0+ (1,0) [0|100] "" Vector__XXX

BO_ 501 FMCU_9_JT: 8 FMCU
 SG_ FMCU_NegTrqAvailMin_2s : 23|13@0+ (0.25,-350) [-350|0] "" RXCU
 SG_ FMCU_PosTrqAvailMax_2s : 26|13@0+ (0.25,0) [0|350] "" RXCU

BO_ 504 HCU_4: 24 RXCU
 SG_ HCU_4_CRC1 : 7|8@0+ (1,0) [0|255] "" EMS_PHEV,TCU_PHEV
 SG_ HCU_4_RollgCntr1 : 11|4@0+ (1,0) [0|14] "" EMS_PHEV,TCU_PHEV
 SG_ HCU_4_Resd1 : 15|4@0+ (1,0) [0|15] "" EMS_PHEV,TCU_PHEV
 SG_ HCU_EMS_EngineIdleSpeedMin : 23|8@0+ (10,0) [0|2540] "rpm" EMS_PHEV
 SG_ HCU_EMS_EngIdleTorqueCtrl : 31|8@0+ (0.5,0) [0|127] "Nm" EMS_PHEV
 SG_ HCU_EMS_TqReqFast : 39|10@0+ (0.5,-150) [-150|350] "Nm" EMS_PHEV,TCU_PHEV
 SG_ HCU_EMS_TqReqSlow : 45|10@0+ (0.5,-150) [-150|350] "Nm" EMS_PHEV,TCU_PHEV
 SG_ HCU_EMS_StopReq : 48|1@0+ (1,0) [0|1] "" EMS_PHEV
 SG_ HCU_EMS_ImmoSts : 49|1@0+ (1,0) [0|1] "" EMS_PHEV
 SG_ FuelCutOffInhibit : 50|1@0+ (1,0) [0|1] "" Vector__XXX
 SG_ FuelCutOffEnable : 51|1@0+ (1,0) [0|1] "" EMS_PHEV
 SG_ AntiJerkActive : 56|1@0+ (1,0) [0|1] "" Vector__XXX
 SG_ DriveSystemActive : 57|1@0+ (1,0) [0|1] "" Vector__XXX
 SG_ HCU_EMS_FuelcutReq : 58|1@0+ (1,0) [0|1] "" EMS_PHEV
 SG_ HCU_EMS_EpsOnReq : 59|1@0+ (1,0) [0|1] "" Vector__XXX
 SG_ HCU_EMS_bPepsEngRun : 60|1@0+ (1,0) [0|1] "" EMS_PHEV
 SG_ EngineFastTorqReqStatus : 61|1@0+ (1,0) [0|1] "" EMS_PHEV,TCU_PHEV
 SG_ HCU_EMS_MILReq : 62|1@0+ (1,0) [0|1] "" Vector__XXX
 SG_ CrankStartReleaseState : 63|1@0+ (1,0) [0|1] "" EMS_PHEV
 SG_ HCU_4_CRC2 : 71|8@0+ (1,0) [0|255] "" EMS_PHEV
 SG_ HCU_4_RollgCntr2 : 75|4@0+ (1,0) [0|14] "" EMS_PHEV
 SG_ HCU_4_Resd2 : 79|4@0+ (1,0) [0|15] "" EMS_PHEV
 SG_ HCU_EMS_SpdSet : 87|16@0+ (0.25,0) [0|16383] "rpm" EMS_PHEV
 SG_ EM1ActSpd : 103|16@0+ (1,-32767) [-32767|32765] "RPM" EMS_PHEV
 SG_ TransEM1TrqAct : 119|12@0+ (0.5,-848) [-848|1199] "Nm" EMS_PHEV
 SG_ HCU_EMS_SpdCtrl : 120|1@0+ (1,0) [0|1] "" EMS_PHEV
 SG_ EngineStartType : 123|3@0+ (1,0) [0|7] "" EMS_PHEV
 SG_ HCU_4_CRC3 : 135|8@0+ (1,0) [0|255] "" EMS_PHEV
 SG_ HCU_4_RollgCntr3 : 139|4@0+ (1,0) [0|14] "" EMS_PHEV
 SG_ HCU_4_Resd3 : 143|4@0+ (1,0) [0|15] "" EMS_PHEV
 SG_ EM1TrqMax : 151|12@0+ (0.5,-848) [-848|1199] "Nm" Vector__XXX
 SG_ PowertrainModeAct : 155|4@0+ (1,0) [0|15] "" EMS_PHEV,TCU_PHEV
 SG_ MotorReadyFA : 164|1@0+ (1,0) [0|1] "" Vector__XXX
 SG_ ICEReady : 165|1@0+ (1,0) [0|1] "" Vector__XXX
 SG_ EngineSlowTorqReqStatus : 166|1@0+ (1,0) [0|1] "" EMS_PHEV
 SG_ HCU_14_DashPotActive : 167|1@0+ (1,0) [0|1] "" EMS_PHEV
 SG_ HCU_EMS_WaterPumpDutyReq : 175|7@0+ (1,0) [0|100] "%" EMS_PHEV

BO_ 520 BMS_2: 48 FLZCU
 SG_ BMS_2_CRC1 : 7|8@0+ (1,0) [0|255] "" RXCU
 SG_ BMS_2_RollgCntr1 : 11|4@0+ (1,0) [0|14] "" RXCU
 SG_ BMS_2_Resd1 : 15|4@0+ (1,0) [0|15] "" RXCU
 SG_ BMS_C2Target_Chg_Voltage : 23|16@0+ (0.1,0) [0|1000] "V" RXCU
 SG_ BMS_NV_relay_Sts : 84|3@0+ (1,0) [0|7] "" RXCU
 SG_ BMS_PV_relay_Sts : 87|3@0+ (1,0) [0|7] "" RXCU
 SG_ BMS_QCP_relay_Sts : 90|3@0+ (1,0) [0|7] "" RXCU
 SG_ BMS_Prechage_relay_Sts : 98|3@0+ (1,0) [0|7] "" RXCU
 SG_ BMS_OutPosU : 223|14@0+ (0.1,0) [0|1023.0] "volt(V)" RXCU
 SG_ BMS_outQCPosU : 279|14@0+ (0.1,0) [0|1023.0] "volt(V)" RXCU

BO_ 522 EMS_7: 32 EMS_PHEV
 SG_ EMS_7_EngTqLimReqTq : 23|9@0+ (1,-50) [-50|400] "Nm" RXCU
 SG_ EMS_7_EngStartInh : 25|2@0+ (1,0) [0|3] "" RXCU
 SG_ EMS_7_VentValve : 27|2@0+ (1,0) [0|3] "" RXCU
 SG_ EMS_7_AirIntakeValve : 29|2@0+ (1,0) [0|3] "" RXCU
 SG_ EMS_7_DiagcTqLimActvnFlg : 30|1@0+ (1,0) [0|1] "" RXCU
 SG_ EMS_7_CrkShftPosition : 47|7@0+ (1,0) [0|120] "" RXCU

BO_ 523 BMS_3: 48 FLZCU
 SG_ BMS_HvBattPMaxReChrgLim : 39|14@0+ (0.1,0) [0|1024] "kW" RXCU
 SG_ BMS_HvBattPMaxDchaLim : 119|14@0+ (0.1,0) [0|1024] "kW" RXCU
 SG_ BMSH_MaxChgPwrPeak : 343|12@0+ (0.1,0) [0|320] "KW" RXCU
 SG_ BMSH_MaxDchgPwrPeak : 347|12@0+ (0.1,0) [0|320] "KW" RXCU

BO_ 603 FLZCU_2: 8 FLZCU
 SG_ FLZCU_2_CRC : 7|8@0+ (1,0) [0|255] "" RXCU
 SG_ FLZCU_2_RollgCntr : 11|4@0+ (1,0) [0|14] "" RXCU
 SG_ FLZCU_2_Resd : 15|4@0+ (1,0) [0|15] "" RXCU
 SG_ FLZCU_2_PowerMode : 17|2@0+ (1,0) [0|3] "" RXCU

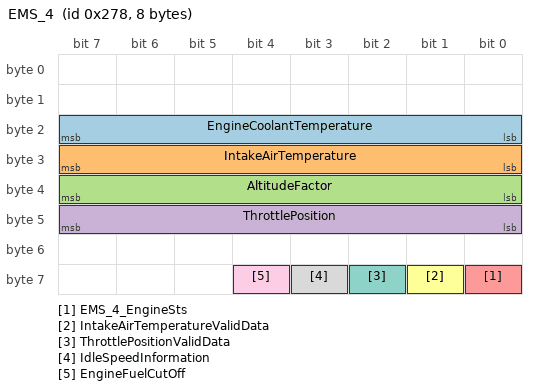
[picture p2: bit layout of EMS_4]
BO_ 632 EMS_4: 8 EMS_PHEV
 SG_ EngineCoolantTemperature : 23|8@0+ (0.75,-48) [-48|142.5] "°C" RXCU
 SG_ IntakeAirTemperature : 31|8@0+ (1,-50) [-50|204] "°C" RXCU
 SG_ AltitudeFactor : 39|8@0+ (0.015626,0) [0|3.98463] "" RXCU
 SG_ ThrottlePosition : 47|8@0+ (0.3921568,0) [0|99.999984] "%" RXCU
 SG_ EMS_4_EngineSts : 56|1@0+ (1,0) [0|1] "" RXCU
 SG_ IntakeAirTemperatureValidData : 57|1@0+ (1,0) [0|1] "" RXCU
 SG_ ThrottlePositionValidData : 58|1@0+ (1,0) [0|1] "" RXCU
 SG_ IdleSpeedInformation : 59|1@0+ (1,0) [0|1] "" RXCU
 SG_ EngineFuelCutOff : 60|1@0+ (1,0) [0|1] "" RXCU

BO_ 753 RXCU_Test_2F1h: 48 TESTER
 SG_ Test_RMCUDesiredTorque_2F1h : 3|12@0+ (0.25,-500) [-500|500] "Nm" RXCU
 SG_ Test_RMCURequestedState_2F1h : 7|4@0+ (1,0) [0|15] "" RXCU
 SG_ Test_RMCUMaxTorqueGradient_2F1h : 23|14@0+ (32,0) [0|524192] "Nm/s" RXCU
 SG_ Test_RMCUMaxTorqueLimit_2F1h : 25|12@0+ (0.25,-500) [-500|500] "Nm" RXCU
 SG_ Test_RMCUMinTorqueLimit_2F1h : 45|12@0+ (0.25,-500) [-500|500] "Nm" RXCU
 SG_ Test_RMCUSpdSet_2F1h : 49|16@0+ (1,-32767) [-32767|32766] "rpm" RXCU
 SG_ Test_SrcSelect_2F1h : 65|2@0+ (1,0) [0|3] "" RXCU

BO_TX_BU_ 522 : EMS_PHEV,PDCS1,PDCS2;
BO_TX_BU_ 632 : EMS_PHEV,PDCS1,PDCS2;

CM_ BO_ 322 "该报文正常情况RMCU不进行转发，通过XCP UDS协议配置后RMCU转发TCUR相关报文";
CM_ BO_ 753 "仅台架测试使用，量产不使用。";
CM_ SG_ 33 ACU_3_CRC1 "Profile1A:E2E CRC (SAE J1850 CRC-8) for 8 Bytes
DataID:0x0002";
CM_ SG_ 33 ACU_3_RollgCntr1 "Profile1A:E2E Rolling message counter(the maximum value of Alive counter is 14)";
CM_ SG_ 33 ACU_3_Resd1 "Profile1A:E2E Reserved";
CM_ SG_ 33 ACU_3_LongitudinalAcceleration "纵向加速度
Longitudinal acceleration signal
Sensor accuracy：0.0027680342857143 g";
CM_ SG_ 33 ACU_3_LongitudinalAccelerationVD "纵向加速度有效位
If hasn’t been calibrated, after initialization, this signal ‘s value is always10(invalid)";
CM_ SG_ 33 ACU_3_CrashOutputSts "碰撞状态信号
Crash signal indicates the status according to bit:
If multiple directions collide at the same time, each collision flag bit representing each direction will be set to 1.For example, if left crash is superimposed with right crash, the output signal is 00001100
此信号发到ECU停止工作为止";
CM_ SG_ 49 ACU_2_LateralAcceleration "横向加速度
Lateral acceleration signal
Sensor accuracy：0.0027680342857143g";
CM_ SG_ 49 ACU_2_YawRate "偏航角速度
Yaw rate signal
Sensor accuracy：0.122189236 deg/s";
CM_ SG_ 49 ACU_2_YawrateSigValidData "偏航角速度有效性
Signal state for yawrate";
CM_ SG_ 49 ACU_2_LateralAccelerationSigVD "横向加速度有效性
If hasn’t been calibrated, after initialization, this signal ‘s value is always 10(invalid).";
CM_ SG_ 152 ABS_ESP_1_ABSFailSts "ABS Fail Status";
CM_ SG_ 152 ABS_ESP_1_ABSActive "ABS Active";
CM_ SG_ 152 ABS_ESP_1_VDCFailSts "VDC Fail Status";
CM_ SG_ 152 ABS_ESP_1_VDCActive "ESP lamp on ICM should blinking ;VDC Intervention";
CM_ SG_ 152 ABS_ESP_1_TCSFailSts "TCS Fail Status";
CM_ SG_ 152 ABS_ESP_1_TCSActive "ESP lamp on ICM should blinking; TCS Intervention";
CM_ SG_ 152 ABS_ESP_1_ESPSwitchStatus "“1” means VDC and Engine Traction Control System (PTC) Function and Brake Traction Control System (BTC) Function disabled and Ignit ESP lamp.";
CM_ SG_ 168 ONEBOX_2_CRC2 "Profile1A:E2E CRC (SAE J1850 CRC-8) for 8 Bytes
DataID:0x004C";
CM_ SG_ 168 ONEBOX_2_RollgCntr2 "Profile1A:E2E Rolling message counter(the maximum value of Alive counter is 14)";
CM_ SG_ 168 ONEBOX_2_Resd2 "Profile1A:E2E Reserved";
CM_ SG_ 168 LHFWheelSpeedRPM "left front Wheel Speed(the unit is RPM)";
CM_ SG_ 168 RHFWheelSpeedRPM "right front  Wheel Speed(the unit is RPM)";
CM_ SG_ 168 ONEBOX_2_CRC3 "Profile1A:E2E CRC (SAE J1850 CRC-8) for 8 Bytes
DataID:0x00A1";
CM_ SG_ 168 ONEBOX_2_RollgCntr3 "Profile1A:E2E Rolling message counter(the maximum value of Alive counter is 14)";
CM_ SG_ 168 ONEBOX_2_Resd3 "Profile1A:E2E Reserved";
CM_ SG_ 168 LHRWheelSpeedRPM_0A8h "Left Rear Wheel Speed(the unit is RPM)";
CM_ SG_ 168 RHRWheelSpeedRPM_0A8h "right Rear  Wheel Speed(the unit is RPM)";
CM_ SG_ 168 RHFWheelSpeedRPMValidData "Valid check bit of the signal RHFWheelSpeedRPM";
CM_ SG_ 168 LHFWheelSpeedRPMValidData "Valid check bit of the signal LHFWheelSpeedRPM";
CM_ SG_ 168 RHFWheelDriveDirection_0A8h "right front Wheel Speed Drive Direction";
CM_ SG_ 168 LHFWheelDriveDirection_0A8h "left front Wheel Speed Drive Direction";
CM_ SG_ 168 RHRWheelSpeedRPMValidData "Valid check bit of the signal RHRWheelSpeedRPM";
CM_ SG_ 168 LHRWheelSpeedRPMValidData "Valid check bit of the signal LHRWheelSpeedRPM";
CM_ SG_ 168 RHRWheelDriveDirection_0A8h "right rear Wheel Speed Drive Direction";
CM_ SG_ 168 LHRWheelDriveDirection_0A8h "left rear Wheel Speed Drive Direction";
CM_ SG_ 277 HCU_28_CRC1 "Profile1A:E2E CRC (SAE J1850 CRC-8) for 8 Bytes
DataID:0x00E8";
CM_ SG_ 277 HCU_28_RollgCntr1 "Profile1A:E2E Rolling message counter(the maximum value of Alive counter is 14)";
CM_ SG_ 277 HCU_28_Resd1 "Profile1A:E2E Reserved";
CM_ SG_ 277 HCU_28_FMCUDesiredTorque "前电机需求扭矩
Desired torque electric machine";
CM_ SG_ 277 HCU_28_FMCUMaxTorqueLimit "前电机最大限制扭矩
Upper limit output torque of electric machine";
CM_ SG_ 277 HCU_28_FMCUMaxTorqueGradient "前电机最大扭矩梯度（股份信号，捷途不使用）
Maximum change rate of the torque request";
CM_ SG_ 277 HCU_28_EngineTorqAct "Actual engine Torque(current conditions incl. intervention)
发动机实际扭矩";
CM_ SG_ 277 HCU_28_CRC2 "Profile1A:E2E CRC (SAE J1850 CRC-8) for 8 Bytes
DataID:0x00E9";
CM_ SG_ 277 HCU_28_RollgCntr2 "Profile1A:E2E Rolling message counter(the maximum value of Alive counter is 14)";
CM_ SG_ 277 HCU_28_Resd2 "Profile1A:E2E Reserved";
CM_ SG_ 277 HCU_28_FMCUMinTorqueLimit "前电机最小限制扭矩
Lower limit output torque of electric machine";
CM_ SG_ 277 HCU_28_FMCUMaxPwrLimit "Maximum Power limit for safety（股份信号，捷途D01不使用）";
CM_ SG_ 277 HCU_28_FMCUSpdSet "speed command";
CM_ SG_ 277 HCU_28_FMCUMaxTorqDampgCtl "Maximum limit for damping torque（股份信号，捷途D01不使用）";
CM_ SG_ 277 HCU_28_CRC3 "Profile1A:E2E CRC (SAE J1850 CRC-8) for 8 Bytes
DataID:0x00EA";
CM_ SG_ 277 HCU_28_RollgCntr3 "Profile1A:E2E Rolling message counter(the maximum value of Alive counter is 14)";
CM_ SG_ 277 HCU_28_Resd3 "Profile1A:E2E Reserved";
CM_ SG_ 277 HCU_28_FMCUMinPwrLimit "Minimum Power limit for safety";
CM_ SG_ 277 HCU_28_FMCUVehMotstRoadSurf "（股份信号，捷途D01不使用）";
CM_ SG_ 277 HCU_28_ISGF_ModeReq "state/mode request of ISG motor";
CM_ SG_ 277 HCU_28_PowertrainModeAct "Actual powertrain mode";
CM_ SG_ 277 HCU_28_ISGF_TorqSet "torque command";
CM_ SG_ 277 HCU_28_Mode "系统模式HCU模式";
CM_ SG_ 277 HCU_28_CRC4 "Profile1A:E2E CRC (SAE J1850 CRC-8) for 8 Bytes
DataID:0x00EB";
CM_ SG_ 277 HCU_28_RollgCntr4 "Profile1A:E2E Rolling message counter(the maximum value of Alive counter is 14)";
CM_ SG_ 277 HCU_28_Resd4 "Profile1A:E2E Reserved";
CM_ SG_ 277 HCU_28_ISGF_TorqMax "max limit of positive torque for drive";
CM_ SG_ 277 HCU_28_ISGF_TorqMin "max limit of negative torque for drive";
CM_ SG_ 277 HCU_28_EngineSts "actual engine status";
CM_ SG_ 277 HCU_28_SleepAllow "sleep allow command";
CM_ SG_ 277 HCU_28_ISGF_DampReq "damp request";
CM_ SG_ 277 HCU_28_bEnaEmReq "ISG enable request";
CM_ SG_ 277 HCU_28_ISGF_SpdSet "speed command";
CM_ SG_ 277 HCU_28_ISGF_MaxTorqDampgCtl "Maximum limit for damping torque";
CM_ SG_ 277 HCU_28_CRC5 "Profile1A:E2E CRC (SAE J1850 CRC-8) for 8 Bytes
DataID:0x00EC";
CM_ SG_ 277 HCU_28_RollgCntr5 "Profile1A:E2E Rolling message counter(the maximum value of Alive counter is 14)";
CM_ SG_ 277 HCU_28_Resd5 "Profile1A:E2E Reserved";
CM_ SG_ 277 HCU_28_NGenrMaxInTqMode "speed limit request in torque mode（股份信号，捷途D01不使用）";
CM_ SG_ 277 HCU_28_ISGF_MaxTorqGradient "Maximum change rate of the torque request（股份信号，捷途D01不使用）";
CM_ SG_ 277 HCU_28_ISGF_Uset "Voltage Set（股份信号，捷途D01不使用）";
CM_ SG_ 277 HCU_28_ISGF_LimpPwrReq "Limp power request（股份信号，捷途D01不使用）";
CM_ SG_ 277 HCU_28_CRC6 "Profile1A:E2E CRC (SAE J1850 CRC-8) for 8 Bytes
DataID:0x00ED";
CM_ SG_ 277 HCU_28_RollgCntr6 "Profile1A:E2E Rolling message counter(the maximum value of Alive counter is 14)";
CM_ SG_ 277 HCU_28_Resd6 "Profile1A:E2E Reserved";
CM_ SG_ 277 HCU_28_ISGF_Iset "Current Set（股份信号，捷途D01不使用）";
CM_ SG_ 277 HCU_28_MaxDisCurrent_ISGF "启动电机放电电流限制（股份信号，捷途D01不使用）";
CM_ SG_ 277 HCU_28_MaxCharCurrent_ISGF "启动电机充电电流限制（股份信号，捷途D01不使用）";
CM_ SG_ 277 HCU_FMCUBoostReq "FMCU Boost request 
FMCU Boost升压功能使能信号";
CM_ SG_ 277 HCU_P3_TorqueAllowed "P3电机扭矩可用";
CM_ SG_ 277 HCU_P1_TorqueAllowed "P1电机扭矩可用";
CM_ SG_ 277 HCU_28_NeutralGearSlide "空挡滑行激活";
CM_ SG_ 277 HCU_28_FMCU_LimpReq "P3电机跛行请求";
CM_ SG_ 279 HCU_29_CRC1 "Profile1A:E2E CRC (SAE J1850 CRC-8) for 8 Bytes
DataID:0x00F5";
CM_ SG_ 279 HCU_29_RollgCntr1 "Profile1A:E2E Rolling message counter(the maximum value of Alive counter is 14)";
CM_ SG_ 279 HCU_29_Resd1 "Profile1A:E2E Reserved";
CM_ SG_ 279 HCU_29_RMCUDesiredTorque "Desired torque electric machine
HCU请求RMCU的扭矩";
CM_ SG_ 279 HCU_29_RMCUMaxTorqueLimit "Upper limit output torque of electric machine";
CM_ SG_ 279 HCU_29_RMCUMaxTorqueGradient "Maximum change rate of the torque request";
CM_ SG_ 279 HCU_29_RMCUDrvHeatReq "VCU enable  rear MCU heatpower or not";
CM_ SG_ 279 HCU_29_CRC2 "Profile1A:E2E CRC (SAE J1850 CRC-8) for 8 Bytes
DataID:0x00F6";
CM_ SG_ 279 HCU_29_RollgCntr2 "Profile1A:E2E Rolling message counter(the maximum value of Alive counter is 14)";
CM_ SG_ 279 HCU_29_Resd2 "Profile1A:E2E Reserved";
CM_ SG_ 279 HCU_29_RMCUMinTorqueLimit "Lower limit output torque of electric machine";
CM_ SG_ 279 HCU_29_RMCUMaxPwrLimit "Maximum Power limit for safety";
CM_ SG_ 279 HCU_RMCU_ActiveHeatHvDcFreqReq "HCU新增-HCU发送给RMCU电池脉冲加热频率请求信号";
CM_ SG_ 279 HCU_29_RearEDLReq "后差速锁动作指令";
CM_ SG_ 279 HCU_P4_TorqueAllowed "P4电机扭矩可用";
CM_ SG_ 279 HCU_29_RMCUMaxTorqueDampgCtl_Res "Maximum limit for damping torque (Reserved)";
CM_ SG_ 279 HCU_29_CRC3 "Profile1A:E2E CRC (SAE J1850 CRC-8) for 8 Bytes
DataID:0x00F7";
CM_ SG_ 279 HCU_29_RollgCntr3 "Profile1A:E2E Rolling message counter(the maximum value of Alive counter is 14)";
CM_ SG_ 279 HCU_29_Resd3 "Profile1A:E2E Reserved";
CM_ SG_ 279 HCU_29_RMCUSpdSet "speed command";
CM_ SG_ 279 HCU_29_RMCUMinPwrLimit "Minimum Power limit for safety";
CM_ SG_ 279 HCU_29_RMCUBoostPwrReq "request boost power";
CM_ SG_ 279 HCU_RMCU_LimpReq "P4电机跛行请求";
CM_ SG_ 279 HCU_29_RMCUBoostStateReq "Boost State Request";
CM_ SG_ 279 HCU_29_CRC4 "Profile1A:E2E CRC (SAE J1850 CRC-8) for 8 Bytes
DataID:0x00F8";
CM_ SG_ 279 HCU_29_RollgCntr4 "Profile1A:E2E Rolling message counter(the maximum value of Alive counter is 14)";
CM_ SG_ 279 HCU_29_Resd4 "Profile1A:E2E Reserved";
CM_ SG_ 279 HCU_29_RMCU_RequestGear "捷途专用，HCU控制器RSCU换挡功能
The gear that  HCU requests the rear gearbox shifting to (this is valid when HCU_RMCUShiftingRequest equals 1).
HCU对TCUR换挡请求";
CM_ SG_ 279 HCU_29_RMCUHeatPwrLimit "捷途专用，HCU控制器RSCU换挡功能";
CM_ SG_ 279 HCU_RMCU_ActiveHeatHvDcAmpReq "电池脉冲加热幅值请求";
CM_ SG_ 279 HCU_29_RMCU_ShiftingRequest "HCU requests the rear gearbox shifting flag.
后变速箱换挡标志位";
CM_ SG_ 279 HCU_RMCU_ActiveHeatHvDcAmpHiLim "电池脉冲加热幅值上限";
CM_ SG_ 279 HCU_RMCU_ActiveHeatHvDcAmpLoLim "电池脉冲加热幅值下限";
CM_ SG_ 279 HCU_29_CRC5 "Profile1A:E2E CRC (SAE J1850 CRC-8) for 8 Bytes
DataID:Reserved";
CM_ SG_ 279 HCU_29_RollgCntr5 "Profile1A:E2E Rolling message counter(the maximum value of Alive counter is 14)";
CM_ SG_ 279 HCU_29_Resd5 "Profile1A:E2E Reserved";
CM_ SG_ 279 HCU_RMCU_ActiveHeatHvDFreqHiLim "HCU新增-HCU发送给RMCU电池脉冲加热频率请求上限信号";
CM_ SG_ 279 HCU_29_ADSRMCUTqUnloadEna "请求卸扭使能";
CM_ SG_ 279 HCU_RMCU_ActiveHeatHvDcFreqLoLim "HCU新增-HCU发送给RMCU电池脉冲加热频率请求下限信号";
CM_ SG_ 279 HCU_BMSVehDcChrgnIDmd "Fast chagring current request（battery power limitation and accessary comsumption）";
CM_ SG_ 279 HCU_29_NeutralGearSlide "空挡滑行激活";
CM_ SG_ 279 HCU_29_CRC6 "Profile1A:E2E CRC (SAE J1850 CRC-8) for 8 Bytes
DataID:Reserved";
CM_ SG_ 279 HCU_29_RollgCntr6 "Profile1A:E2E Rolling message counter(the maximum value of Alive counter is 14)";
CM_ SG_ 279 HCU_29_Resd6 "Profile1A:E2E Reserved";
CM_ SG_ 279 HCU_BMSVehDcChrgnUDmd "Fast chagring voltage request（battery power limitation and accessary comsumption）";
CM_ SG_ 279 HCU_DCB_InputVolt "DCB输入母线电压";
CM_ SG_ 279 HCU_DCB_BoostNegRelaySts "升压负极接触器状态";
CM_ SG_ 279 HCU_DCB_BoostPosRelaySts "升压正极接触器状态";
CM_ SG_ 279 HCU_DCB_C2RelaySts "C2电容接触器器状态";
CM_ SG_ 279 HCU_29_CRC7 "Profile1A:E2E CRC (SAE J1850 CRC-8) for 8 Bytes
DataID:0x0111";
CM_ SG_ 279 HCU_29_RollgCntr7 "Profile1A:E2E Rolling message counter(the maximum value of Alive counter is 14)";
CM_ SG_ 279 HCU_29_RMCUDesiredFFTorque "后电机需求前馈扭矩
Desired feedforward torque electric machine";
CM_ SG_ 279 HCU_29_FMCUDesiredFFTorque "前电机需求前馈扭矩
Desired feedforward torque electric machine";
CM_ SG_ 306 SAM_1_SteeringAngle "方向盘转角角度值";
CM_ SG_ 306 SAM_1_SteeringAngleSpeed "方向盘转角角速度";
CM_ SG_ 306 SAM_1_SteeringAngleSpeedVD "角速度有效性";
CM_ SG_ 306 SAM_1_SteeringAngleVD "角度有效性";
CM_ SG_ 306 SAM_1_SASCalibrated "角度传感器标定状态";
CM_ SG_ 322 RMCU_TCUR_ShiftGearOperSt "RMCU换挡控制状态机状态";
CM_ SG_ 322 TCUR_GearSt "TCUR执行器挡位";
CM_ SG_ 322 RMCU_TCUR_ShiftGearReq "RMCU换挡控制挡位请求";
CM_ SG_ 322 RMCU_TCUR_RdToSleep "RMCU允许TCUR下电标志位
0x0：不允许TCUR下电
0x1：允许TCUR下电";
CM_ SG_ 322 RMCU_GbxStMac "RMCU换挡控制主状态机";
CM_ SG_ 322 TCUR_GearPosnMeasRaw "TCUR挡位位置传感器采集值";
CM_ SG_ 322 TCUR_SleepComfirm "TCUR下电确认标志位
0x0：TCUR未收到下电允许标志
0x1：TCUR确认下电";
CM_ SG_ 322 RMCU_MCUGearShiftAllwFlg "RMCU允许换挡标志位
0x0：RMCU不允许换挡
0x1：RMCU允许换挡";
CM_ SG_ 322 TCUR_ActrOperSt "TCUR执行器状态机状态";
CM_ SG_ 419 HCU_26_CRC1 "Profile1A:E2E CRC (SAE J1850 CRC-8) for 8 Bytes
DataID:0x00F2";
CM_ SG_ 419 HCU_26_RollgCntr1 "Profile1A:E2E Rolling message counter(the maximum value of Alive counter is 14)";
CM_ SG_ 419 HCU_ENG_TorqueAllowed "ENG扭矩可用";
CM_ SG_ 419 HCU_26_TargetGearTransInp "变速箱目标档位";
CM_ SG_ 419 HCU_26_OptMode "0x0:串联模式
0x1:并联固定档位模式
0x2:并联换挡模式
0x3:串联切并联
0x4:并联切串联";
CM_ SG_ 419 HCU_26_TargetGearEM2 "Target gear for EM2";
CM_ SG_ 419 PowertrainModeDes "动力总成模式
Desired_Powertrain_Mode";
CM_ SG_ 419 HCU_26_FrntEDLReq "前差速锁动作指令";
CM_ SG_ 419 HCU_26_InputClutchIntervention "Intervention enabler for C1 clutch";
CM_ SG_ 419 GasPedalPosition "油门踏板位置
Driver/Cruise_control
This_signal_including_compositive_informations_which_are_actual_gas_pedal_position_and_dummy_Cruise_control_gas_pedal_position";
CM_ SG_ 419 BrakePedalStsValidDataForTCU "制动踏板有效位Valid_check_bit_of_the_signal_BrakePedalStsForTCU";
CM_ SG_ 419 BrakePedalStsForTCU "制动踏板状态
Brake_Pedal_Status_For_TCU";
CM_ SG_ 419 GasPedalPositionInvalidData "油门踏板位置有效位Valid_check_bit_of_the_EMS_1_GasPedalPosition";
CM_ SG_ 419 TargetGearTransInp "HCU给TCU发的目标档位";
CM_ SG_ 419 HCU_26_ADSFMCUTqUnloadEna "请求卸扭使能";
CM_ SG_ 419 HCU_TMCU_EmsTqReqSlow "HCU给TMCU的不受TMCU干预的发动机目标扭矩Engine torque demand：";
CM_ SG_ 419 HCU_TMCU_CntrAllowMode "HCU允许TMCU控制扭矩模式状态
0x0：HCU不允许TMCU控制P1/P3/ICE扭矩
0x1：HCU允许TMCU控制P1扭矩
0x2：HCU允许TMCU控制P3扭矩
0x3：HCU允许TMCU控制P1+P3扭矩
0x4: HCU允许TMCU控制ICE扭矩
0x5：HCU允许TMCU控制P1+ICE扭矩
0x6：HCU允许TMCU控制P3+ICE扭矩
0x7：HCU允许TMCU以速率限制控制P1+P3+ICE扭矩
0x8：HCU允许TMCU在P3换挡期间以速率限制控制P3扭矩（新增）
0x9：HCU允许TMCU在P3换挡期间无速率限制地控制P3扭矩（新增）
0xA：HCU不允许TMCU控制P3扭矩（新增）
0xF:HCU允许TMCU控制P1+P3+ICE扭矩，无速率限制";
CM_ SG_ 419 HCU_26_CRC2 "Profile1A:E2E CRC (SAE J1850 CRC-8) for 8 Bytes
DataID:0x00F4";
CM_ SG_ 419 HCU_26_RollgCntr2 "Profile1A:E2E Rolling message counter(the maximum value of Alive counter is 14)";
CM_ SG_ 419 HCU_26_Resd2 "Profile1A:E2E Reserved";
CM_ SG_ 419 HCU_26_IndicatedDriverReqWhlTqFA "Driver request wheel torque at FA
1、D01该信号为HCU发给TCU,经过TCS调整过之后的轮端扭矩
2、T1JFL2智驾版为HCU发出的目标扭矩";
CM_ SG_ 419 HCU_26_ActWheelTorqueFA "实际前轮端扭矩Actual wheel torque at FA";
CM_ SG_ 419 HCU_26_ActWheelTorqueRA "实际后轮端扭矩Actual wheel torque at RA";
CM_ SG_ 419 HCU_26_CRC3 "Profile1A:E2E CRC (SAE J1850 CRC-8) for 8 Bytes
DataID:No ASIL requirements.Not configure
CRC Reserved.";
CM_ SG_ 419 HCU_26_RollgCntr3 "Profile1A:E2E Rolling message counter(the maximum value of Alive counter is 14)";
CM_ SG_ 419 HCU_26_Resd3 "Profile1A:E2E Reserved";
CM_ SG_ 419 HCU_AccessoriesCosumePower "捷途新增信号HCU附件功率";
CM_ SG_ 419 HCU_26_PRNDGearTargetValidData "valid Target gear";
CM_ SG_ 419 HCU_26_PRNDGearActValidData "valid actual gear";
CM_ SG_ 419 HCU_26_TransInpTarSpd "HCU target speed for transmission input (EM1 / ICE); This is on the input side of C2 / C3 and can be used by TCU to evaluate when to close C2/C3 clutch to connect Transmission input to the wheels.";
CM_ SG_ 419 HCU_26_ADSFMCUTqUnloadRate "轮端卸扭斜率";
CM_ SG_ 419 HCU_RearEDDReq_1A3h "HCU请求后驱EDD状态";
CM_ SG_ 419 HCU_26_TransInpActSpd "Actual Speed of transmission input";
CM_ SG_ 419 HCU_26_TransEM1TrqTar "EM1 torque target (w/o TCU Interventions)";
CM_ SG_ 419 HCU_26_C1CapacityTarget "Target clutch capacity  to be applied between ICE and TransInput (Can be C1)
0 Nm (during state open)
calculated value (during state controlled)
FFF (during state closed)";
CM_ SG_ 419 HCU_26_PRNDGearTarget "Target PRND gear as evaluated by HCU.";
CM_ SG_ 419 HCU_26_PRNDGearAct "Actual PRND gear as evaluated by HCU.";
CM_ SG_ 419 HCU_26_ShiftUrgency "Index of desired shifting speed, if necessary, HCU can demand a quick shift in exchange for e.g. comfort";
CM_ SG_ 419 HCU_26_TransInpTrqAct "Transmission input torque with interventions";
CM_ SG_ 419 HCU_26_TransInpTrqTar "Transmission input torque target (w/o TCU Interventions)";
CM_ SG_ 419 HCU_26_TransInpTrqMin "Minimum available P2 torque";
CM_ SG_ 419 HCU_26_EM2TrqTar "TCU未干预的HCU给前驱动电机的目标扭矩";
CM_ SG_ 419 HCU_26_ADSFMCUMotTqRateLimMin "轮端扭矩变化率上限";
CM_ SG_ 419 HCU_26_ADSFMCUMotTqRateLimMax "轮端扭矩变化率上限";
CM_ SG_ 419 HCU_26_Activeheat "前电机加热允许状态位";
CM_ SG_ 419 HCU_26_ECGPOvrd "标识驾驶员扭矩高于ACC请求扭矩";
CM_ SG_ 419 HCU_26_ErrorMotorSpeedRA "Quality/fault information to Current engine speed.";
CM_ SG_ 419 HCU_26_EpsOnReq "HCU requesst to EMS for enabling EPS (Through EngineSts)";
CM_ SG_ 419 HCU_26_C1CapacityState "C1 target state:
open
controlled
closed";
CM_ SG_ 419 HCU_26_EngineStartType "Engine start type";
CM_ SG_ 419 HCU_26_FMCUMaxActiveheatPwr "允许前发电机/前驱动电机主动发热功率";
CM_ SG_ 474 FMCU_8_CRC1 "Profile1A:E2E CRC (SAE J1850 CRC-8) for 8 Bytes
DataID:0x00E2";
CM_ SG_ 474 FMCU_8_RollgCntr1 "Profile1A:E2E Rolling message counter(the maximum value of Alive counter is 14)";
CM_ SG_ 474 FMCU_8_Resd1 "Profile1A:E2E Reserved";
CM_ SG_ 474 FMCU_8_TorqMax "前驱动电机最大扭矩";
CM_ SG_ 474 FMCU_8_TorqMin "前驱动电机最小扭矩";
CM_ SG_ 474 FMCU_8_TorqAct "前驱动电机实际扭矩（EM2扭矩）
拆帧转发至GL CAN 0xD1(bit20)";
CM_ SG_ 474 FMCU_8ModeSt "前驱动电机状态信号
actual state of FMCU motor
FMCU状态信号
拆帧转发至GL 网段
ID 0x397（FLZCU_16）Bit116-119";
CM_ SG_ 474 FMCU_8_FMCUDeratSts "前驱动电机降额状态
FMCU derating status";
CM_ SG_ 474 FMCU_8_ErrLvl "前驱动电机故障等级
Error Level";
CM_ SG_ 474 FMCU_8_DampActive "前驱动电机主动阻尼状态
Damping state of FMCU motor";
CM_ SG_ 474 FMCU_8_CRC2 "Profile1A:E2E CRC (SAE J1850 CRC-8) for 8 Bytes
DataID:0x00E3";
CM_ SG_ 474 FMCU_8_RollgCntr2 "Profile1A:E2E Rolling message counter(the maximum value of Alive counter is 14)";
CM_ SG_ 474 FMCU_8_Resd2 "Profile1A:E2E Reserved";
CM_ SG_ 474 FMCU_8_SpdAct "FMCU motor actual speed
前驱动电机实际转速（EM2转速）";
CM_ SG_ 474 FMCU_8_TrqActDampingReq "前驱动电机主动阻尼扭矩
Active damping requirement";
CM_ SG_ 474 FMCU_8_UdcAct "前驱动电机母线电压
actual bus voltage";
CM_ SG_ 474 FMCU_8_ISGF_DampActive "前发电机主动阻尼开启
Damping state of ISG motor";
CM_ SG_ 474 FMCU_8_InterlockStatus "前驱动电机高压互锁状态
Interlock Status";
CM_ SG_ 474 FMCU_8_ISGF_ErrLvl "前发电机故障等级(捷途新增故障等级5，6)
Error Level";
CM_ SG_ 474 FMCU_8_ISGF_ModeSt "前发电机模式状态
actual state of ISG motor";
CM_ SG_ 474 FMCU_8_CRC3 "Profile1A:E2E CRC (SAE J1850 CRC-8) for 8 Bytes
DataID:0x00E4";
CM_ SG_ 474 FMCU_8_RollgCntr3 "Profile1A:E2E Rolling message counter(the maximum value of Alive counter is 14)";
CM_ SG_ 474 FMCU_8_Resd3 "Profile1A:E2E Reserved";
CM_ SG_ 474 FMCU_8_IdcAct "前驱动电机母线电流
actual HV current at generator";
CM_ SG_ 474 FMCU_8_ISGF_SpdAct "前发电机实际转速
ISG motor actual speed
拆帧至IC CAN0x3FC(bit72)";
CM_ SG_ 474 FMCU_8_ISGF_TorqMax "前发电机最大扭矩
avaialbe/allowed maximum drive torque";
CM_ SG_ 474 FMCU_8_ISGF_TorqAct "前发电机实际扭矩
ISG motor actual torque";
CM_ SG_ 474 FMCU_8_CRC4 "Profile1A:E2E CRC (SAE J1850 CRC-8) for 8 Bytes
DataID:0x00E5";
CM_ SG_ 474 FMCU_8_RollgCntr4 "Profile1A:E2E Rolling message counter(the maximum value of Alive counter is 14)";
CM_ SG_ 474 FMCU_8_Resd4 "Profile1A:E2E Reserved";
CM_ SG_ 474 FMCU_8_ISGF_TorqMin "前发电机最小扭矩
avaialbe/allowed minimum regenrative torque";
CM_ SG_ 474 FMCU_8_ISGF_IdcAct "前发电机实际电流actual HV current at generator";
CM_ SG_ 474 FMCU_8_ISGF_UdcAct "actual bus voltage";
CM_ SG_ 474 FMCU_8_ActiveheatReq "前发电机主动加热请求";
CM_ SG_ 474 FMCU_8_ISGF_DischargeState "前发电机实际电压
Active discharge state of ISG 放电状态（横置增程）";
CM_ SG_ 474 FMCU_8_CRC5 "Profile1A:E2E CRC (SAE J1850 CRC-8) for 8 Bytes
DataID:0x00E6";
CM_ SG_ 474 FMCU_8_RollgCntr5 "Profile1A:E2E Rolling message counter(the maximum value of Alive counter is 14)";
CM_ SG_ 474 FMCU_8_Resd5 "Profile1A:E2E Reserved";
CM_ SG_ 474 FMCU_8_ISGF_TrqActDampingReq "前发电机主动阻尼扭矩
Active damping requirement";
CM_ SG_ 474 FMCU_8_ISGF_GateDrvSt "前发电机驱动状态
state of gate driver";
CM_ SG_ 474 FMCU_8_LimpAllow "捷途新增前电机跛行允许";
CM_ SG_ 474 FMCU_8_Limp "捷途新增前电机跛行状态";
CM_ SG_ 474 FMCU_8_CRC6 "Profile1A:E2E CRC (SAE J1850 CRC-8) for 8 Bytes
DataID:0x00E7";
CM_ SG_ 474 FMCU_8_RollgCntr6 "Profile1A:E2E Rolling message counter(the maximum value of Alive counter is 14)";
CM_ SG_ 474 FMCU_8_Resd6 "Profile1A:E2E Reserved";
CM_ SG_ 474 FMCU_8_InvTemp "前驱动电机控制器结温温度Inverter temperature
拆帧转发至GL CAN 0xD1（bit24）";
CM_ SG_ 474 FMCU_8_ISGF_InvTemp "前发电机控制器结温温度Inverter temperature
拆帧转发至GL CAN 0xD1（bit32）";
CM_ SG_ 474 FMCU_8_MCUActRUnfilteredRodSpd "MCU滤波前实际转速（T1J FL2华为智驾新增，D01华为智驾同步使用）";
CM_ SG_ 474 FMCU_8_MCUReqTq "MCU需求扭矩（T1J FL2华为智驾新增，D01华为智驾同步使用）";
CM_ SG_ 474 FMCU_8_MCUModActvSt "MCU模式激活状态（T1J FL2华为智驾新增，D01华为智驾同步使用）
0x0: 扭矩模式
0x1: 转速模式
0x2: SV模式";
CM_ SG_ 474 FMCU_8_SpdSvModAvl "转速模式可用状态（T1J FL2华为智驾新增，D01华为智驾同步使用）";
CM_ SG_ 474 FMCU_E_ClutchStus "电磁离合器状态（一档）";
CM_ SG_ 474 FMCU_E_ClutchEngMilLampReq "电磁离合器请求点亮MIL故障灯";
CM_ SG_ 474 FMCU_8_MCUSpdSVModFlt "MCU转速模式故障原因（T1J FL2华为智驾新增，D01华为智驾同步使用）
0x0: 无故障
0x1: 输出扭矩绝对值过大故障";
CM_ SG_ 474 FMCU_8_MCUVehSldSt "驱动电机判断车辆是否溜车（T1J FL2华为智驾新增，D01华为智驾同步使用）";
CM_ SG_ 474 FMCU_8_MCUStandstill "MCU standstill状态（T1J FL2华为智驾新增，D01华为智驾同步使用）";
CM_ SG_ 474 FMCU_8_MCUBlkSt "MCU卡停状态（T1J FL2华为智驾新增，D01华为智驾同步使用）";
CM_ SG_ 474 FMCU_8_ISGActRUnfilteredRodSpd "发电机滤波前实际转速（T1J FL2华为智驾新增，D01华为智驾同步使用）";
CM_ SG_ 474 FMCU_8_ISGReqTq "发电机需求扭矩（T1J FL2华为智驾新增，D01华为智驾同步使用）";
CM_ SG_ 474 FMCU_8_ISGModActvSt "发电机模式激活状态（T1J FL2华为智驾新增，D01华为智驾同步使用）
0x0: 扭矩模式
0x1: 转速模式
0x2: SV模式";
CM_ SG_ 474 FMCU_8_ISGSpdSvModAvl "发电机转速模式可用状态（T1J FL2华为智驾新增，D01华为智驾同步使用）";
CM_ SG_ 474 FMCU_8_ISGSpdSVModFlt "发电机转速模式故障原因（T1J FL2华为智驾新增，D01华为智驾同步使用）
0x0: 无故障
0x1: 输出扭矩绝对值过大故障";
CM_ SG_ 474 FMCU_8_ISGVehSldSt "发电机判断车辆是否溜车（T1J FL2华为智驾新增，D01华为智驾同步使用）";
CM_ SG_ 474 FMCU_8_ISGStandstill "发电机 standstill状态（T1J FL2华为智驾新增，D01华为智驾同步使用）";
CM_ SG_ 474 FMCU_8_ISGBlkSt "发电机卡停状态（T1J FL2华为智驾新增，D01华为智驾同步使用）";
CM_ SG_ 474 FMCU_E_ClutchErrLvl "电磁离合器故障等级";
CM_ SG_ 474 FMCU_8_MCU_SpdActValidData "前驱动电机实际转速有效位（T1J FL2华为智驾新增，D01华为智驾同步使用）";
CM_ SG_ 474 FMCU_8_ActiveheatPwrAct "前发电机实际加热功率";
CM_ SG_ 474 FMCU_E_ClutchCurr "电磁离合器线圈电流（一档）";
CM_ SG_ 474 FMCU_E_ClutchActMod "0x0: open mode(离合器断开)
0x1: peak mode(离合器吸合)
0x2: hold mode(离合器保持吸合)
0x3: peak timeout
（MCU收到peak mode指令后5s时间内没有收到hold mode指令，MCU进入该状态并断开电磁离合器线圈）
0x4：Fault mode";
CM_ SG_ 474 FMCU_8_ISGF_PositionCtrSts "前发电机位置控状态";
CM_ SG_ 474 FMCU_8_ISGF_SpdAcValidData "前发电机实际转速有效位（T1J FL2华为智驾新增，D01华为智驾同步使用）";
CM_ SG_ 474 ECluAvlTq "electromagnetic clutch can actually transmit torque
电磁离合器实际可传递扭矩";
CM_ SG_ 485 RMCU_1_CRC1 "Profile1A:E2E CRC (SAE J1850 CRC-8) for 8 Bytes
DataID:0x0058";
CM_ SG_ 485 RMCU_1_RollgCntr1 "Profile1A:E2E Rolling message counter(the maximum value of Alive counter is 14)";
CM_ SG_ 485 RMCU_1_Resd1 "Profile1A:E2E Reserved";
CM_ SG_ 485 RMCU_MaxTorque "后驱动电机最大扭矩Electric machine maximum available torque";
CM_ SG_ 485 RMCU_MinTorque "后驱动电机最小扭矩Electric machine minimum available torque";
CM_ SG_ 485 RMCU_1_OutputTorque "后驱动电机输出扭矩Output torque which is currently provided by the electric machine";
CM_ SG_ 485 RMCU_State "后驱动电机状态
actual state of RMCU motor
拆帧至GL网段
ID 0x397(FLZCU_16)Bit112-115";
CM_ SG_ 485 RMCU_1_InverterTemperature "后驱动电机逆变器结温温度Current temperature of inverter
拆帧至GL CAN 0xD1(bit0)";
CM_ SG_ 485 RMCU_1_CRC2 "Profile1A:E2E CRC (SAE J1850 CRC-8) for 8 Bytes
DataID:0x0059";
CM_ SG_ 485 RMCU_1_RollgCntr2 "Profile1A:E2E Rolling message counter(the maximum value of Alive counter is 14)";
CM_ SG_ 485 RMCU_1_Resd2 "Profile1A:E2E Reserved";
CM_ SG_ 485 RMCU_TrqActDampingReq "后驱动电机主动阻尼扭矩Active damping requirement";
CM_ SG_ 485 RMCU_RMCUDeratSts "后驱动电机降额状态RMCU derating status";
CM_ SG_ 485 RMCU_1_VoltageHV "后驱动电机控制器母线电压HV voltage at the DC/AC converter";
CM_ SG_ 485 RMCU_ElockWorkStatusAct "后锁实际执行状态
0x0:No Lock
0x1:UNLock (not display)
0x2:Lock (Green)
0x3:Warning (Green Flash)
0x4:UNAvailable(Yellow Flash)
0x5:Stuck Open(Yellow)
0x6:Stuck Close(Yellow)";
CM_ SG_ 485 RMCU_1_MCU_SpdActValidData "后驱动电机实际转速有效位（T1J FL2华为智驾新增，D01华为智驾同步使用）";
CM_ SG_ 485 RMCU_1_Speed "后驱动电机转速RMCU motor actual speed
拆针至IC CAN 0x3FC (bit88)";
CM_ SG_ 485 RMCU_1_CRC3 "Profile1A:E2E CRC (SAE J1850 CRC-8) for 8 Bytes
DataID:0x005A";
CM_ SG_ 485 RMCU_1_RollgCntr3 "Profile1A:E2E Rolling message counter(the maximum value of Alive counter is 14)";
CM_ SG_ 485 RMCU_1_Resd3 "Profile1A:E2E Reserved";
CM_ SG_ 485 RMCU_ErrLvl "后驱动电机故障等级Error Level";
CM_ SG_ 485 RMCU_1_BoostSts "FL_CANFD_PT RMCU/RXCU 0x1E5 LSB155拆帧至0x2FF LSB21";
CM_ SG_ 485 RMCU_1_CurrentHV "后驱动电机母线电流HV current at the DC/AC converter";
CM_ SG_ 485 RMCU_HeatPwrAct "Actual auxiliary heat power of motor
拆帧至GL CAN
ID 0x397(FLZCU_16)Bit159-151";
CM_ SG_ 485 RMCU_MAXHeatPwr "Maximum auxiliary heat power of motor
拆帧至GL CAN
ID 0x397(FLZCU_16)Bit166-158";
CM_ SG_ 485 RMCU_DampActive "后MCU主动阻尼Damping state of RMCU motor";
CM_ SG_ 485 RMCU_InterlockStatus "后MCU高压互锁状态Interlock Status";
CM_ SG_ 485 RMCU_1_SpdSvModAvl "转速模式可用状态（T1J FL2华为智驾新增,D01华为智驾驶同步使用）";
CM_ SG_ 485 RMCU_1_CRC4 "Profile1A:E2E CRC (SAE J1850 CRC-8) for 8 Bytes
DataID:0x01EE";
CM_ SG_ 485 RMCU_1_RollgCntr4 "Profile1A:E2E Rolling message counter(the maximum value of Alive counter is 14)";
CM_ SG_ 485 RMCU_1_Resd4 "Profile1A:E2E Reserved";
CM_ SG_ 485 RMCU_1_MCUModActvSt "MCU模式激活状态（T1J FL2华为智驾新增,D01华为智驾驶同步使用）
0x0: 扭矩模式
0x1: 转速模式
0x2: SV模式";
CM_ SG_ 485 RMCU_1_BSTNRelayReqAct "Quick Charge Negtive Relay Active";
CM_ SG_ 485 RMCU_1_BSTPRelayReqAct "Quick Charge Positive Relay Active";
CM_ SG_ 485 RMCU_1_MCUStandstill "MCU standstill状态（T1J FL2华为智驾新增,D01华为智驾驶同步使用）";
CM_ SG_ 485 RMCU_1_MCUVehSldSt "驱动电机判断车辆是否溜车（T1J FL2华为智驾新增,D01华为智驾驶同步使用）";
CM_ SG_ 485 RMCU_1_BoostErrLvl "Error Level";
CM_ SG_ 485 RMCU_1_BSTPrechargeRelayAct "Quick Charge Negtive Relay Active";
CM_ SG_ 485 RMCU_1_NeutralGearUnavailable "捷途新增TCUR相关换挡信号Neutral gear unavailable flag";
CM_ SG_ 485 RMCU_1_GearShiftProgFlag "捷途新增TCUR相关换挡信号The shifting status of rear gearbox";
CM_ SG_ 485 RMCU_1_GearShiftAllw "捷途新增TCUR相关换挡信号The allow shifting flag of rear gearbox";
CM_ SG_ 485 RMCU_1_CurrGear "捷途新增TCUR相关换挡信号The actual engaged gear of rear gearbox";
CM_ SG_ 485 RMCU_1_GearSelfStudySts "Signal state for gear study of rear gearbox";
CM_ SG_ 485 RMCU_1_TCURErrLvlDis "TCUR故障等级
拆帧转发至IC CAN 0x3FC(bit125)";
CM_ SG_ 485 RMCU_1_2ndGearUnavailable "捷途新增TCUR相关换挡信号2nd gear unavailable flag";
CM_ SG_ 485 RMCU_1_1stGearUnavailable "捷途新增TCUR相关换挡信号1st gear unavailable flag";
CM_ SG_ 485 RMCU_1_MCUActRUnfilteredRodSpd "MCU滤波前实际转速（T1J FL2华为智驾新增,D01华为智驾驶同步使用）";
CM_ SG_ 485 RMCU_1_CRC5 "Profile1A:E2E CRC (SAE J1850 CRC-8) for 8 Bytes
DataID:No ASIL requirements.Not configure
CRC Reserved.";
CM_ SG_ 485 RMCU_1_RollgCntr5 "Profile1A:E2E Rolling message counter(the maximum value of Alive counter is 14)";
CM_ SG_ 485 RMCU_1_ActiveHeatHvDcAmpAct "捷途新增电池脉冲加热生效的直流母线电流幅值";
CM_ SG_ 485 RMCU_1_LimpAllow "捷途新增后驱动电机跛行允许";
CM_ SG_ 485 RMCU_1_ActiveHeatHvDcFreqAct "捷途新增电池脉冲加热生效的直流母线电流频率";
CM_ SG_ 485 RMCU_1_MCUReqTq "MCU需求扭矩（T1J FL2华为智驾新增,D01华为智驾驶同步使用）";
CM_ SG_ 485 RMCU_1_MCUBlkSt "MCU卡停状态（T1J FL2华为智驾新增,D01华为智驾驶同步使用）";
CM_ SG_ 485 RMCU_GBFaultstatus "TCUR变速箱故障灯";
CM_ SG_ 485 RMCU_1_RotorPosition "捷途新增后驱动电机跛行状态
0x0：位置无效
0x1：有位置运行
0x2：无位置运行";
CM_ SG_ 485 RMCU_1_MCUSpdSVModFlt "MCU转速模式故障原因（T1J FL2华为智驾新增,D01华为智驾驶同步使用）
0x0: 无故障
0x1: 输出扭矩绝对值过大故障";
CM_ SG_ 485 RMCU_1_CRC6 "Profile1A:E2E CRC (SAE J1850 CRC-8) for 8 Bytes
DataID:No ASIL requirements.Not configure
CRC Reserved.";
CM_ SG_ 485 RMCU_1_RollgCntr6 "Profile1A:E2E Rolling message counter(the maximum value of Alive counter is 14)";
CM_ SG_ 485 RMCU_EDD_RearEDDStMac "EDD主状态机状态";
CM_ SG_ 485 RMCU_EDD_RearEDDOperSt "EDD控制状态机状态";
CM_ SG_ 485 RMCU_EDD_RearEDDSts "后驱EDD状态
0x0：初始化
0x1：EDD结合
0x2：EDD断开
0x3：EDD结合失败
0x4：EDD断开失败
0x5：EDD移动中
0x6：预留
0x7：EDD状态未知";
CM_ SG_ 485 RMCU_EDD_RearEDDFaultCode "后驱EDD故障码";
CM_ SG_ 485 RMCU_EDD_RearEDDCnctDisAllwReas "EDD不执行结合的原因";
CM_ SG_ 485 RMCU_EDD_RearEDDConnectAllwFlg "EDD是否允许结合
0x0:EDD 不允许结合
0x1:EDD 允许结合";
CM_ SG_ 485 RMCU_EDD_RearEDDErrLvlDis "后驱EDD故障等级";
CM_ SG_ 485 RMCU_EDD_RearEDDPosnMeasRaw "EDD位置传感器采集值";
CM_ SG_ 501 FMCU_NegTrqAvailMin_2s "2s结束的信号是为了保护电机做的扭矩预测，只是根据电机温度做的保护
T1N JS FL2 坤泰/D01&T1L麦格纳FMCU不需要发ID";
CM_ SG_ 501 FMCU_PosTrqAvailMax_2s "2s结束的信号是为了保护电机做的扭矩预测，只是根据电机温度做的保护
T1N JS FL2 坤泰/D01&T1L麦格纳FMCU不需要发ID";
CM_ SG_ 504 HCU_4_CRC1 "Profile1A:E2E CRC (SAE J1850 CRC-8) for 8 Bytes
DataID:0x0092";
CM_ SG_ 504 HCU_4_RollgCntr1 "Profile1A:E2E Rolling message counter(the maximum value of Alive counter is 14)";
CM_ SG_ 504 HCU_4_Resd1 "Profile1A:E2E Reserved";
CM_ SG_ 504 HCU_EMS_EngineIdleSpeedMin "最小发动机怠速转速Minimum Engine idle speed";
CM_ SG_ 504 HCU_EMS_EngIdleTorqueCtrl "发动机怠速预控扭矩
Engine idle contoller precontrol torque";
CM_ SG_ 504 HCU_EMS_TqReqFast "发动机快扭请求Fast Effective Torque request (Ignition)
在EngineFastTorqReqStatus置位时，通过点火角响应该扭矩。同时，该扭矩不能大于慢扭";
CM_ SG_ 504 HCU_EMS_TqReqSlow "发动机慢扭请求Slow EffectiveTorque request (Airpath)
通过调整进气量响应该扭矩。响应较慢。如果需要快速降扭，需要EngineFastTorqReqStatus置位后通过HCU_EMS_TqReqFast响应。";
CM_ SG_ 504 HCU_EMS_StopReq "发动机停机请求Engine stop request
置位，发动机不喷油。启动过程中允许喷油的时刻由该信号控制。";
CM_ SG_ 504 HCU_EMS_ImmoSts "IMMO防盗状态
为0时，EMS不喷油。为1时，EMS才允许喷油。";
CM_ SG_ 504 FuelCutOffInhibit "断油禁止Inhibit engine fuel cut off";
CM_ SG_ 504 FuelCutOffEnable "断油使能Enable (force) engine fuel cut off
该标志位置位，同时HCU请求快、慢扭矩到倒拖扭矩时，EMS进入断油工况。";
CM_ SG_ 504 AntiJerkActive "Antijerk:加速时，防止转速振荡，使扭矩输出平顺（股份信号，D01不使用）";
CM_ SG_ 504 DriveSystemActive "驱动系统激活标志位（股份信号，D01不使用）";
CM_ SG_ 504 HCU_EMS_FuelcutReq "断油请求（股份信号，D01不使用）";
CM_ SG_ 504 HCU_EMS_EpsOnReq "转向助力请求HCU requesst to EMS for enabling EPS (Through EngineSts)";
CM_ SG_ 504 HCU_EMS_bPepsEngRun "signal to get back to a 'drive ready' status.（股份信号，D01不使用）";
CM_ SG_ 504 EngineFastTorqReqStatus "发动机快扭请求状态
该标志位置位后通过点火角响应快扭请求。";
CM_ SG_ 504 HCU_EMS_MILReq "MIL Request by HCU（股份信号，D01不使用）";
CM_ SG_ 504 CrankStartReleaseState "允许点火状态（股份信号，D01不使用）";
CM_ SG_ 504 HCU_4_CRC2 "Profile1A:E2E CRC (SAE J1850 CRC-8) for 8 Bytes
DataID:0x0093";
CM_ SG_ 504 HCU_4_RollgCntr2 "Profile1A:E2E Rolling message counter(the maximum value of Alive counter is 14)";
CM_ SG_ 504 HCU_4_Resd2 "Profile1A:E2E Reserved";
CM_ SG_ 504 HCU_EMS_SpdSet "EMS目标转速Speed set（股份信号，D01不使用）";
CM_ SG_ 504 EM1ActSpd "EM1实际转速Actual Speed of EM1";
CM_ SG_ 504 TransEM1TrqAct "EM1实际扭矩Actual torque of EM1.";
CM_ SG_ 504 HCU_EMS_SpdCtrl "转速控制标志位Speed contro（股份信号，D01不使用）";
CM_ SG_ 504 EngineStartType "发动机启动类型Engine start type
启动拖动前需要发送启动类型。启动完成后该信号复位。";
CM_ SG_ 504 HCU_4_CRC3 "Profile1A:E2E CRC (SAE J1850 CRC-8) for 8 Bytes
DataID:0x0094";
CM_ SG_ 504 HCU_4_RollgCntr3 "Profile1A:E2E Rolling message counter(the maximum value of Alive counter is 14)";
CM_ SG_ 504 HCU_4_Resd3 "Profile1A:E2E Reserved";
CM_ SG_ 504 EM1TrqMax "EM1最大扭矩Maximum EM1 torque";
CM_ SG_ 504 PowertrainModeAct "实际动力总成模式Actual powertrain mode";
CM_ SG_ 504 ICEReady "发动机READY";
CM_ SG_ 504 EngineSlowTorqReqStatus "发动机慢扭请求状态Flywheel torque request active（股份平台信号，D01不使用）";
CM_ SG_ 504 HCU_14_DashPotActive "DashPotActive（股份平台信号，D01不使用）";
CM_ SG_ 504 HCU_EMS_WaterPumpDutyReq "EMS Water Pump Duty Request from TMS（股份平台信号，D01不使用）";
CM_ SG_ 520 BMS_2_CRC1 "Profile1A:E2E CRC (SAE J1850 CRC-8) for 8 Bytes
DataID:0x007E";
CM_ SG_ 520 BMS_2_RollgCntr1 "Profile1A:E2E Rolling message counter(the maximum value of Alive counter is 14)";
CM_ SG_ 520 BMS_2_Resd1 "Profile1A:E2E Reserved";
CM_ SG_ 520 BMS_C2Target_Chg_Voltage "BMS_C2Target_Chg_Voltage";
CM_ SG_ 520 BMS_NV_relay_Sts "上报主负继电器状态
Main NEG Rely State";
CM_ SG_ 520 BMS_PV_relay_Sts "上报主正继电器状态
Main POS Rely State";
CM_ SG_ 520 BMS_QCP_relay_Sts "上报充正继电器状态
DC-CHG POS Rely State";
CM_ SG_ 520 BMS_Prechage_relay_Sts "上报预充继电器状态
Pre-Charge Rely State";
CM_ SG_ 520 BMS_OutPosU "主正继电器外侧电压对主负继电器内侧电压
POS Mian-rely outside voltage";
CM_ SG_ 520 BMS_outQCPosU "快充正继电器外侧电压对主负继电器内侧电压
POS DC rely outside voltage";
CM_ SG_ 522 EMS_7_EngTqLimReqTq "EMS向HCU发送诊断工况限制的请求扭矩";
CM_ SG_ 522 EMS_7_EngStartInh "EMS发送禁止启动请求（T1J FL2华为版新增，D01,D01P.D01华为，T1J华为使用）";
CM_ SG_ 522 EMS_7_VentValve "EMS控制排气阀门状态";
CM_ SG_ 522 EMS_7_AirIntakeValve "EMS控制进气阀门状态";
CM_ SG_ 522 EMS_7_DiagcTqLimActvnFlg "EMS向HCU发送诊断限扭的激活标志
正常发送。
EMS在催化器加热（EMS_6 EMS_CatalystHeatActv）或者其它诊断工况（EMS_7_DiagcTqLimActvnFlg），会请求HCU降低发动机扭矩。HCU结合整车工况判断，如果认为合适，则响应该扭矩请求。
催化器加热降扭请求影响排放，如无特殊原因，必须响应。诊断请求在排循环结束前需要响应以辅助EMS完成法规诊断要求。";
CM_ SG_ 522 EMS_7_CrkShftPosition "EMS 曲轴位置（T1J FL2华为版新增，D01,D01P.D01华为，T1J华为使用）";
CM_ SG_ 523 BMS_HvBattPMaxReChrgLim "BMS max recharge power (10s)";
CM_ SG_ 523 BMS_HvBattPMaxDchaLim "BMS max discharge power (10s)";
CM_ SG_ 523 BMSH_MaxChgPwrPeak "Maximum Charge Power Peak
拆帧至IC CAN 0x3FC（bit52）";
CM_ SG_ 523 BMSH_MaxDchgPwrPeak "Maximum Discharge Power Peak
拆帧至IC CAN 0x3FC（bit56）";
CM_ SG_ 603 FLZCU_2_CRC "Profile1A:E2E CRC (SAE J1850 CRC-8) for 8 Bytes
DataID:0x00A0";
CM_ SG_ 603 FLZCU_2_RollgCntr "Profile1A:E2E Rolling message counter(the maximum value of Alive counter is 14)";
CM_ SG_ 603 FLZCU_2_Resd "Profile1A:E2E Reserved";
CM_ SG_ 603 FLZCU_2_PowerMode "低压电源状态";
CM_ SG_ 632 EngineCoolantTemperature "Engine coolant temperture
发动机水温";
CM_ SG_ 632 IntakeAirTemperature "Intake Air Temperature
节气门后
进气温度";
CM_ SG_ 632 AltitudeFactor "高原系数
Ambient pressure/ standard pressure
当前大气压除以标准大气压，这个值在0-1之间。";
CM_ SG_ 632 ThrottlePosition "节气门位置Throttle Position";
CM_ SG_ 632 EMS_4_EngineSts "发动机状态（模拟）Engine Status
If this value is 1, indicate that  the engine is started successfully.
在PHEV上，此信号发送模拟的发动机状态；
(PTReady和PrePTReady取或。)";
CM_ SG_ 632 IntakeAirTemperatureValidData "进气温度有效位Intake Air Temperature Valid Data";
CM_ SG_ 632 ThrottlePositionValidData "节气门位置有效位Throttle Position Valid Data";
CM_ SG_ 632 IdleSpeedInformation "怠速状态Idle Speed Information";
CM_ SG_ 632 EngineFuelCutOff "发动机断油标志位Fuel cut off state(engine is actually in FCO)";
CM_ SG_ 753 Test_RMCUDesiredTorque_2F1h "台架请求转矩指令";
CM_ SG_ 753 Test_RMCURequestedState_2F1h "台架测试模式请求";
CM_ SG_ 753 Test_RMCUMaxTorqueGradient_2F1h "台架请求转矩斜率";
CM_ SG_ 753 Test_RMCUMaxTorqueLimit_2F1h "台架请求转矩最大值";
CM_ SG_ 753 Test_RMCUMinTorqueLimit_2F1h "台架请求转矩最小值";
CM_ SG_ 753 Test_RMCUSpdSet_2F1h "台架请求转速指令";
CM_ SG_ 753 Test_SrcSelect_2F1h "台架测试激活请求";

BA_DEF_ BU_ "ILused" ENUM "No","Yes";
BA_DEF_ BU_ "NodeLayerModules" STRING ;
BA_DEF_ "Baudrate" INT 0 1000000;
BA_DEF_ "BaudrateCANFD" INT 1000000 10000000;
BA_DEF_ "BusType" STRING ;
BA_DEF_ "DBName" STRING ;
BA_DEF_ "NmBaseAddress" HEX 1536 1663;
BA_DEF_ "NmMessageCount" INT 0 255;
BA_DEF_ "ProtocolType" STRING ;
BA_DEF_ SG_ "ASIL" ENUM "QM","A","B","C","D";
BA_DEF_ SG_ "E2EDataLength" INT 0 65535;
BA_DEF_ SG_ "GenSigInactiveValue" HEX 0 80000000;
BA_DEF_ SG_ "GenSigInvalidValue" HEX 0 281474976710655;
BA_DEF_ SG_ "GenSigStartValue" HEX 0 80000000;
BA_DEF_ SG_ "GenSigSendType" ENUM "Cyclic","OnWrite","OnWriteWithRepetition","OnChange","OnChangeWithRepetition","IfActive","IfActiveWithRepetition","NoSigSendType";
BA_DEF_ BO_ "CANFD_BRS" ENUM "0","1";
BA_DEF_ BO_ "DiagMessage" ENUM "No","Yes";
BA_DEF_ BO_ "DiagRequest" ENUM "No","Yes";
BA_DEF_ BO_ "DiagResponse" ENUM "No","Yes";
BA_DEF_ BO_ "DiagState" ENUM "No","Yes";
BA_DEF_ BO_ "DiagUudtResponse" ENUM "True","False";
BA_DEF_ BO_ "GenMsgCycleTime" INT 0 65535;
BA_DEF_ BO_ "GenMsgCycleTimeFast" INT 0 65535;
BA_DEF_ BO_ "GenMsgDelayTime" INT 0 65535;
BA_DEF_ BO_ "GenMsgILSupport" ENUM "No","Yes";
BA_DEF_ BO_ "GenMsgNrOfRepetition" INT 0 255;
BA_DEF_ BO_ "GenMsgSendType" ENUM "Cyclic","Event","IfActive","CE","CA","NoMsgSendType";
BA_DEF_ BO_ "MsgType" ENUM "IL","NM","DIAG","APPL";
BA_DEF_ BO_ "Msg_ASIL" ENUM "vector_leerstring","QM","A","B","C","D";
BA_DEF_ BO_ "NmAsrMessage" ENUM "No","Yes";
BA_DEF_ BO_ "NmMessage" ENUM "No","Yes";
BA_DEF_ BO_ "SCP_AuthInfoTxLength" INT 9 512;
BA_DEF_ BO_ "SCP_FreshnessValueLength" INT 0 512;
BA_DEF_ BO_ "SCP_FreshnessValueTxLength" INT 0 512;
BA_DEF_ BO_ "VFrameFormat" ENUM "StandardCAN","ExtendedCAN","reserved","J1939PG","reserved","reserved","reserved","reserved","reserved","reserved","reserved","reserved","reserved","reserved","StandardCAN_FD","ExtendedCAN_FD";
BA_DEF_DEF_ "ILused" "Yes";
BA_DEF_DEF_ "NodeLayerModules" "CANoeILNLSPA.dll";
BA_DEF_DEF_ "Baudrate" 500000;
BA_DEF_DEF_ "BaudrateCANFD" 2000000;
BA_DEF_DEF_ "BusType" "CAN";
BA_DEF_DEF_ "DBName" "CAN";
BA_DEF_DEF_ "NmBaseAddress" 1536;
BA_DEF_DEF_ "NmMessageCount" 128;
BA_DEF_DEF_ "ProtocolType" "CAN";
BA_DEF_DEF_ "ASIL" "QM";
BA_DEF_DEF_ "E2EDataLength" 64;
BA_DEF_DEF_ "GenSigInactiveValue" 0;
BA_DEF_DEF_ "GenSigInvalidValue" 0;
BA_DEF_DEF_ "GenSigStartValue" 0;
BA_DEF_DEF_ "GenSigSendType" "NoSigSendType";
BA_DEF_DEF_ "CANFD_BRS" "1";
BA_DEF_DEF_ "DiagMessage" "No";
BA_DEF_DEF_ "DiagRequest" "No";
BA_DEF_DEF_ "DiagResponse" "No";
BA_DEF_DEF_ "DiagState" "No";
BA_DEF_DEF_ "DiagUudtResponse" "True";
BA_DEF_DEF_ "GenMsgCycleTime" 0;
BA_DEF_DEF_ "GenMsgCycleTimeFast" 0;
BA_DEF_DEF_ "GenMsgDelayTime" 0;
BA_DEF_DEF_ "GenMsgILSupport" "Yes";
BA_DEF_DEF_ "GenMsgNrOfRepetition" 0;
BA_DEF_DEF_ "GenMsgSendType" "Cyclic";
BA_DEF_DEF_ "MsgType" "IL";
BA_DEF_DEF_ "Msg_ASIL" "vector_leerstring";
BA_DEF_DEF_ "NmAsrMessage" "No";
BA_DEF_DEF_ "NmMessage" "No";
BA_DEF_DEF_ "SCP_AuthInfoTxLength" 28;
BA_DEF_DEF_ "SCP_FreshnessValueLength" 48;
BA_DEF_DEF_ "SCP_FreshnessValueTxLength" 4;
BA_DEF_DEF_ "VFrameFormat" "J1939PG";
BA_ "BusType" "CAN FD";
BA_ "DBName" "FL_PT_CANFD";
BA_ "ILused" BU_ EMS_ICE 0;
BA_ "ILused" BU_ EMS_PHEV 0;
BA_ "ILused" BU_ FLZCU 0;
BA_ "ILused" BU_ FMCU 0;
BA_ "ILused" BU_ PDCS1 0;
BA_ "ILused" BU_ PDCS2 0;
BA_ "ILused" BU_ RMCU 0;
BA_ "ILused" BU_ RXCU 0;
BA_ "ILused" BU_ TCU_PHEV 0;
BA_ "ILused" BU_ TCUR 0;
BA_ "ILused" BU_ TESTER 0;
BA_ "GenMsgCycleTime" BO_ 33 10;
BA_ "VFrameFormat" BO_ 33 14;
BA_ "GenMsgCycleTime" BO_ 49 10;
BA_ "VFrameFormat" BO_ 49 14;
BA_ "GenMsgCycleTime" BO_ 152 10;
BA_ "VFrameFormat" BO_ 152 14;
BA_ "GenMsgCycleTime" BO_ 168 10;
BA_ "VFrameFormat" BO_ 168 14;
BA_ "GenMsgCycleTime" BO_ 277 10;
BA_ "VFrameFormat" BO_ 277 14;
BA_ "GenMsgCycleTime" BO_ 279 10;
BA_ "VFrameFormat" BO_ 279 14;
BA_ "GenMsgCycleTime" BO_ 306 10;
BA_ "VFrameFormat" BO_ 306 14;
BA_ "GenMsgCycleTime" BO_ 322 10;
BA_ "VFrameFormat" BO_ 322 14;
BA_ "GenMsgCycleTime" BO_ 419 10;
BA_ "VFrameFormat" BO_ 419 14;
BA_ "GenMsgCycleTime" BO_ 474 10;
BA_ "VFrameFormat" BO_ 474 14;
BA_ "GenMsgCycleTime" BO_ 485 10;
BA_ "VFrameFormat" BO_ 485 14;
BA_ "GenMsgCycleTime" BO_ 501 10;
BA_ "VFrameFormat" BO_ 501 14;
BA_ "GenMsgCycleTime" BO_ 504 10;
BA_ "VFrameFormat" BO_ 504 14;
BA_ "GenMsgCycleTime" BO_ 520 20;
BA_ "VFrameFormat" BO_ 520 14;
BA_ "GenMsgCycleTime" BO_ 522 10;
BA_ "VFrameFormat" BO_ 522 14;
BA_ "GenMsgCycleTime" BO_ 523 20;
BA_ "VFrameFormat" BO_ 523 14;
BA_ "GenMsgCycleTime" BO_ 603 20;
BA_ "VFrameFormat" BO_ 603 14;
BA_ "GenMsgCycleTime" BO_ 632 50;
BA_ "VFrameFormat" BO_ 632 14;
BA_ "GenMsgCycleTime" BO_ 753 20;
BA_ "VFrameFormat" BO_ 753 14;
BA_ "GenSigSendType" SG_ 33 ACU_3_CRC1 0;
BA_ "GenSigSendType" SG_ 33 ACU_3_RollgCntr1 0;
BA_ "GenSigSendType" SG_ 33 ACU_3_Resd1 0;
BA_ "GenSigInvalidValue" SG_ 33 ACU_3_LongitudinalAcceleration 65535;
BA_ "GenSigStartValue" SG_ 33 ACU_3_LongitudinalAcceleration 2000;
BA_ "ASIL" SG_ 33 ACU_3_LongitudinalAcceleration 2;
BA_ "GenSigSendType" SG_ 33 ACU_3_LongitudinalAcceleration 0;
BA_ "GenSigStartValue" SG_ 33 ACU_3_LongitudinalAccelerationVD 3;
BA_ "ASIL" SG_ 33 ACU_3_LongitudinalAccelerationVD 2;
BA_ "GenSigSendType" SG_ 33 ACU_3_LongitudinalAccelerationVD 0;
BA_ "ASIL" SG_ 33 ACU_3_CrashOutputSts 2;
BA_ "GenSigSendType" SG_ 33 ACU_3_CrashOutputSts 0;
BA_ "GenSigInvalidValue" SG_ 49 ACU_2_LateralAcceleration 65535;
BA_ "GenSigStartValue" SG_ 49 ACU_2_LateralAcceleration 2000;
BA_ "ASIL" SG_ 49 ACU_2_LateralAcceleration 2;
BA_ "GenSigSendType" SG_ 49 ACU_2_LateralAcceleration 0;
BA_ "GenSigInvalidValue" SG_ 49 ACU_2_YawRate 65535;
BA_ "GenSigStartValue" SG_ 49 ACU_2_YawRate 18000;
BA_ "ASIL" SG_ 49 ACU_2_YawRate 2;
BA_ "GenSigSendType" SG_ 49 ACU_2_YawRate 0;
BA_ "GenSigStartValue" SG_ 49 ACU_2_YawrateSigValidData 3;
BA_ "ASIL" SG_ 49 ACU_2_YawrateSigValidData 2;
BA_ "GenSigSendType" SG_ 49 ACU_2_YawrateSigValidData 0;
BA_ "GenSigStartValue" SG_ 49 ACU_2_LateralAccelerationSigVD 3;
BA_ "ASIL" SG_ 49 ACU_2_LateralAccelerationSigVD 2;
BA_ "GenSigSendType" SG_ 49 ACU_2_LateralAccelerationSigVD 0;
BA_ "ASIL" SG_ 152 ABS_ESP_1_ABSFailSts 4;
BA_ "GenSigSendType" SG_ 152 ABS_ESP_1_ABSFailSts 0;
BA_ "ASIL" SG_ 152 ABS_ESP_1_ABSActive 4;
BA_ "GenSigSendType" SG_ 152 ABS_ESP_1_ABSActive 0;
BA_ "ASIL" SG_ 152 ABS_ESP_1_VDCFailSts 4;
BA_ "GenSigSendType" SG_ 152 ABS_ESP_1_VDCFailSts 0;
BA_ "ASIL" SG_ 152 ABS_ESP_1_VDCActive 4;
BA_ "GenSigSendType" SG_ 152 ABS_ESP_1_VDCActive 0;
BA_ "ASIL" SG_ 152 ABS_ESP_1_TCSFailSts 4;
BA_ "GenSigSendType" SG_ 152 ABS_ESP_1_TCSFailSts 0;
BA_ "ASIL" SG_ 152 ABS_ESP_1_TCSActive 4;
BA_ "GenSigSendType" SG_ 152 ABS_ESP_1_TCSActive 0;
BA_ "ASIL" SG_ 152 ABS_ESP_1_ESPSwitchStatus 2;
BA_ "GenSigSendType" SG_ 152 ABS_ESP_1_ESPSwitchStatus 0;
BA_ "GenSigSendType" SG_ 168 ONEBOX_2_CRC2 0;
BA_ "GenSigSendType" SG_ 168 ONEBOX_2_RollgCntr2 0;
BA_ "GenSigSendType" SG_ 168 ONEBOX_2_Resd2 0;
BA_ "GenSigInvalidValue" SG_ 168 LHFWheelSpeedRPM 65535;
BA_ "ASIL" SG_ 168 LHFWheelSpeedRPM 4;
BA_ "GenSigSendType" SG_ 168 LHFWheelSpeedRPM 0;
BA_ "GenSigInvalidValue" SG_ 168 RHFWheelSpeedRPM 65535;
BA_ "ASIL" SG_ 168 RHFWheelSpeedRPM 4;
BA_ "GenSigSendType" SG_ 168 RHFWheelSpeedRPM 0;
BA_ "GenSigSendType" SG_ 168 ONEBOX_2_CRC3 0;
BA_ "GenSigSendType" SG_ 168 ONEBOX_2_RollgCntr3 0;
BA_ "GenSigSendType" SG_ 168 ONEBOX_2_Resd3 0;
BA_ "GenSigInvalidValue" SG_ 168 LHRWheelSpeedRPM_0A8h 65535;
BA_ "ASIL" SG_ 168 LHRWheelSpeedRPM_0A8h 2;
BA_ "GenSigSendType" SG_ 168 LHRWheelSpeedRPM_0A8h 0;
BA_ "GenSigInvalidValue" SG_ 168 RHRWheelSpeedRPM_0A8h 65535;
BA_ "ASIL" SG_ 168 RHRWheelSpeedRPM_0A8h 2;
BA_ "GenSigSendType" SG_ 168 RHRWheelSpeedRPM_0A8h 0;
BA_ "GenSigStartValue" SG_ 168 RHFWheelSpeedRPMValidData 1;
BA_ "ASIL" SG_ 168 RHFWheelSpeedRPMValidData 2;
BA_ "GenSigSendType" SG_ 168 RHFWheelSpeedRPMValidData 0;
BA_ "GenSigStartValue" SG_ 168 LHFWheelSpeedRPMValidData 1;
BA_ "ASIL" SG_ 168 LHFWheelSpeedRPMValidData 2;
BA_ "GenSigSendType" SG_ 168 LHFWheelSpeedRPMValidData 0;
BA_ "GenSigInvalidValue" SG_ 168 RHFWheelDriveDirection_0A8h 4;
BA_ "ASIL" SG_ 168 RHFWheelDriveDirection_0A8h 2;
BA_ "GenSigSendType" SG_ 168 RHFWheelDriveDirection_0A8h 0;
BA_ "GenSigInvalidValue" SG_ 168 LHFWheelDriveDirection_0A8h 4;
BA_ "ASIL" SG_ 168 LHFWheelDriveDirection_0A8h 2;
BA_ "GenSigSendType" SG_ 168 LHFWheelDriveDirection_0A8h 0;
BA_ "GenSigStartValue" SG_ 168 RHRWheelSpeedRPMValidData 1;
BA_ "ASIL" SG_ 168 RHRWheelSpeedRPMValidData 2;
BA_ "GenSigSendType" SG_ 168 RHRWheelSpeedRPMValidData 0;
BA_ "GenSigStartValue" SG_ 168 LHRWheelSpeedRPMValidData 1;
BA_ "ASIL" SG_ 168 LHRWheelSpeedRPMValidData 2;
BA_ "GenSigSendType" SG_ 168 LHRWheelSpeedRPMValidData 0;
BA_ "GenSigInvalidValue" SG_ 168 RHRWheelDriveDirection_0A8h 4;
BA_ "ASIL" SG_ 168 RHRWheelDriveDirection_0A8h 2;
BA_ "GenSigSendType" SG_ 168 RHRWheelDriveDirection_0A8h 0;
BA_ "GenSigInvalidValue" SG_ 168 LHRWheelDriveDirection_0A8h 4;
BA_ "ASIL" SG_ 168 LHRWheelDriveDirection_0A8h 2;
BA_ "GenSigSendType" SG_ 168 LHRWheelDriveDirection_0A8h 0;
BA_ "GenSigSendType" SG_ 277 HCU_28_CRC1 0;
BA_ "GenSigSendType" SG_ 277 HCU_28_RollgCntr1 0;
BA_ "GenSigSendType" SG_ 277 HCU_28_Resd1 0;
BA_ "GenSigStartValue" SG_ 277 HCU_28_FMCUDesiredTorque 2000;
BA_ "ASIL" SG_ 277 HCU_28_FMCUDesiredTorque 3;
BA_ "GenSigSendType" SG_ 277 HCU_28_FMCUDesiredTorque 0;
BA_ "GenSigStartValue" SG_ 277 HCU_28_FMCUMaxTorqueLimit 2000;
BA_ "ASIL" SG_ 277 HCU_28_FMCUMaxTorqueLimit 3;
BA_ "GenSigSendType" SG_ 277 HCU_28_FMCUMaxTorqueLimit 0;
BA_ "GenSigInvalidValue" SG_ 277 HCU_28_FMCUMaxTorqueGradient 16383;
BA_ "ASIL" SG_ 277 HCU_28_FMCUMaxTorqueGradient 3;
BA_ "GenSigSendType" SG_ 277 HCU_28_FMCUMaxTorqueGradient 0;
BA_ "GenSigInvalidValue" SG_ 277 HCU_28_EngineTorqAct 1023;
BA_ "GenSigStartValue" SG_ 277 HCU_28_EngineTorqAct 300;
BA_ "ASIL" SG_ 277 HCU_28_EngineTorqAct 1;
BA_ "GenSigSendType" SG_ 277 HCU_28_EngineTorqAct 0;
BA_ "GenSigSendType" SG_ 277 HCU_28_CRC2 0;
BA_ "GenSigSendType" SG_ 277 HCU_28_RollgCntr2 0;
BA_ "GenSigSendType" SG_ 277 HCU_28_Resd2 0;
BA_ "GenSigStartValue" SG_ 277 HCU_28_FMCUMinTorqueLimit 2000;
BA_ "ASIL" SG_ 277 HCU_28_FMCUMinTorqueLimit 3;
BA_ "GenSigSendType" SG_ 277 HCU_28_FMCUMinTorqueLimit 0;
BA_ "GenSigSendType" SG_ 277 HCU_28_FMCUMaxPwrLimit 0;
BA_ "GenSigInvalidValue" SG_ 277 HCU_28_FMCUSpdSet 65535;
BA_ "GenSigStartValue" SG_ 277 HCU_28_FMCUSpdSet 32767;
BA_ "ASIL" SG_ 277 HCU_28_FMCUSpdSet 3;
BA_ "GenSigSendType" SG_ 277 HCU_28_FMCUSpdSet 0;
BA_ "GenSigInvalidValue" SG_ 277 HCU_28_FMCUMaxTorqDampgCtl 255;
BA_ "GenSigSendType" SG_ 277 HCU_28_FMCUMaxTorqDampgCtl 0;
BA_ "GenSigSendType" SG_ 277 HCU_28_CRC3 0;
BA_ "GenSigSendType" SG_ 277 HCU_28_RollgCntr3 0;
BA_ "GenSigSendType" SG_ 277 HCU_28_Resd3 0;
BA_ "GenSigStartValue" SG_ 277 HCU_28_FMCUMinPwrLimit 4000;
BA_ "GenSigSendType" SG_ 277 HCU_28_FMCUMinPwrLimit 0;
BA_ "ASIL" SG_ 277 HCU_28_FMCURequestedState 3;
BA_ "GenSigSendType" SG_ 277 HCU_28_FMCURequestedState 0;
BA_ "GenSigInvalidValue" SG_ 277 HCU_28_FMCUVehMotstRoadSurf 30;
BA_ "GenSigStartValue" SG_ 277 HCU_28_FMCUVehMotstRoadSurf 5;
BA_ "GenSigSendType" SG_ 277 HCU_28_FMCUVehMotstRoadSurf 0;
BA_ "ASIL" SG_ 277 HCU_28_ISGF_ModeReq 1;
BA_ "GenSigSendType" SG_ 277 HCU_28_ISGF_ModeReq 0;
BA_ "GenSigSendType" SG_ 277 HCU_28_PowertrainModeAct 0;
BA_ "GenSigInvalidValue" SG_ 277 HCU_28_ISGF_TorqSet 2047;
BA_ "GenSigStartValue" SG_ 277 HCU_28_ISGF_TorqSet 1020;
BA_ "ASIL" SG_ 277 HCU_28_ISGF_TorqSet 1;
BA_ "GenSigSendType" SG_ 277 HCU_28_ISGF_TorqSet 0;
BA_ "GenSigSendType" SG_ 277 HCU_28_FMCUDampReq 0;
BA_ "GenSigSendType" SG_ 277 HCU_28_Mode 0;
BA_ "GenSigSendType" SG_ 277 HCU_28_CRC4 0;
BA_ "GenSigSendType" SG_ 277 HCU_28_RollgCntr4 0;
BA_ "GenSigSendType" SG_ 277 HCU_28_Resd4 0;
BA_ "GenSigInvalidValue" SG_ 277 HCU_28_ISGF_TorqMax 1023;
BA_ "ASIL" SG_ 277 HCU_28_ISGF_TorqMax 1;
BA_ "GenSigSendType" SG_ 277 HCU_28_ISGF_TorqMax 0;
BA_ "GenSigInvalidValue" SG_ 277 HCU_28_ISGF_TorqMin 1023;
BA_ "GenSigStartValue" SG_ 277 HCU_28_ISGF_TorqMin 1020;
BA_ "ASIL" SG_ 277 HCU_28_ISGF_TorqMin 1;
BA_ "GenSigSendType" SG_ 277 HCU_28_ISGF_TorqMin 0;
BA_ "ASIL" SG_ 277 HCU_28_EngineSts 1;
BA_ "GenSigSendType" SG_ 277 HCU_28_EngineSts 0;
BA_ "ASIL" SG_ 277 HCU_28_SleepAllow 1;
BA_ "GenSigSendType" SG_ 277 HCU_28_SleepAllow 0;
BA_ "ASIL" SG_ 277 HCU_28_ISGF_DampReq 1;
BA_ "GenSigSendType" SG_ 277 HCU_28_ISGF_DampReq 0;
BA_ "ASIL" SG_ 277 HCU_28_bEnaEmReq 1;
BA_ "GenSigSendType" SG_ 277 HCU_28_bEnaEmReq 0;
BA_ "GenSigInvalidValue" SG_ 277 HCU_28_ISGF_SpdSet 65535;
BA_ "GenSigStartValue" SG_ 277 HCU_28_ISGF_SpdSet 32767;
BA_ "ASIL" SG_ 277 HCU_28_ISGF_SpdSet 1;
BA_ "GenSigSendType" SG_ 277 HCU_28_ISGF_SpdSet 0;
BA_ "GenSigInvalidValue" SG_ 277 HCU_28_ISGF_MaxTorqDampgCtl 255;
BA_ "ASIL" SG_ 277 HCU_28_ISGF_MaxTorqDampgCtl 1;
BA_ "GenSigSendType" SG_ 277 HCU_28_ISGF_MaxTorqDampgCtl 0;
BA_ "GenSigSendType" SG_ 277 HCU_28_CRC5 0;
BA_ "GenSigSendType" SG_ 277 HCU_28_RollgCntr5 0;
BA_ "GenSigSendType" SG_ 277 HCU_28_Resd5 0;
BA_ "GenSigInvalidValue" SG_ 277 HCU_28_NGenrMaxInTqMode 65535;
BA_ "GenSigStartValue" SG_ 277 HCU_28_NGenrMaxInTqMode 32767;
BA_ "ASIL" SG_ 277 HCU_28_NGenrMaxInTqMode 1;
BA_ "GenSigSendType" SG_ 277 HCU_28_NGenrMaxInTqMode 0;
BA_ "GenSigInvalidValue" SG_ 277 HCU_28_ISGF_MaxTorqGradient 16383;
BA_ "ASIL" SG_ 277 HCU_28_ISGF_MaxTorqGradient 1;
BA_ "GenSigSendType" SG_ 277 HCU_28_ISGF_MaxTorqGradient 0;
BA_ "GenSigInvalidValue" SG_ 277 HCU_28_ISGF_Uset 1023;
BA_ "ASIL" SG_ 277 HCU_28_ISGF_Uset 1;
BA_ "GenSigSendType" SG_ 277 HCU_28_ISGF_Uset 0;
BA_ "GenSigInvalidValue" SG_ 277 HCU_28_ISGF_LimpPwrReq 255;
BA_ "ASIL" SG_ 277 HCU_28_ISGF_LimpPwrReq 1;
BA_ "GenSigSendType" SG_ 277 HCU_28_ISGF_LimpPwrReq 0;
BA_ "GenSigSendType" SG_ 277 HCU_28_CRC6 0;
BA_ "GenSigSendType" SG_ 277 HCU_28_RollgCntr6 0;
BA_ "GenSigSendType" SG_ 277 HCU_28_Resd6 0;
BA_ "GenSigInvalidValue" SG_ 277 HCU_28_ISGF_Iset 2047;
BA_ "GenSigStartValue" SG_ 277 HCU_28_ISGF_Iset 1023;
BA_ "ASIL" SG_ 277 HCU_28_ISGF_Iset 1;
BA_ "GenSigSendType" SG_ 277 HCU_28_ISGF_Iset 0;
BA_ "GenSigInvalidValue" SG_ 277 HCU_28_MaxDisCurrent_ISGF 32767;
BA_ "ASIL" SG_ 277 HCU_28_MaxDisCurrent_ISGF 1;
BA_ "GenSigSendType" SG_ 277 HCU_28_MaxDisCurrent_ISGF 0;
BA_ "GenSigInvalidValue" SG_ 277 HCU_28_MaxCharCurrent_ISGF 32767;
BA_ "GenSigStartValue" SG_ 277 HCU_28_MaxCharCurrent_ISGF 20460;
BA_ "ASIL" SG_ 277 HCU_28_MaxCharCurrent_ISGF 1;
BA_ "GenSigSendType" SG_ 277 HCU_28_MaxCharCurrent_ISGF 0;
BA_ "GenSigSendType" SG_ 277 HCU_FMCUBoostReq 0;
BA_ "GenSigSendType" SG_ 277 HCU_P3_TorqueAllowed 0;
BA_ "GenSigSendType" SG_ 277 HCU_P1_TorqueAllowed 0;
BA_ "GenSigSendType" SG_ 277 HCU_28_NeutralGearSlide 0;
BA_ "ASIL" SG_ 277 HCU_28_FMCU_LimpReq 1;
BA_ "GenSigSendType" SG_ 277 HCU_28_FMCU_LimpReq 0;
BA_ "GenSigSendType" SG_ 279 HCU_29_CRC1 0;
BA_ "GenSigSendType" SG_ 279 HCU_29_RollgCntr1 0;
BA_ "GenSigSendType" SG_ 279 HCU_29_Resd1 0;
BA_ "GenSigInvalidValue" SG_ 279 HCU_29_RMCUDesiredTorque 4095;
BA_ "GenSigStartValue" SG_ 279 HCU_29_RMCUDesiredTorque 2000;
BA_ "ASIL" SG_ 279 HCU_29_RMCUDesiredTorque 3;
BA_ "GenSigSendType" SG_ 279 HCU_29_RMCUDesiredTorque 0;
BA_ "GenSigInvalidValue" SG_ 279 HCU_29_RMCUMaxTorqueLimit 4095;
BA_ "GenSigStartValue" SG_ 279 HCU_29_RMCUMaxTorqueLimit 2000;
BA_ "ASIL" SG_ 279 HCU_29_RMCUMaxTorqueLimit 3;
BA_ "GenSigSendType" SG_ 279 HCU_29_RMCUMaxTorqueLimit 0;
BA_ "GenSigInvalidValue" SG_ 279 HCU_29_RMCUMaxTorqueGradient 16383;
BA_ "GenSigSendType" SG_ 279 HCU_29_RMCUMaxTorqueGradient 0;
BA_ "GenSigSendType" SG_ 279 HCU_29_LowPwrReq 0;
BA_ "GenSigSendType" SG_ 279 HCU_29_RMCUDrvHeatReq 0;
BA_ "GenSigInvalidValue" SG_ 279 HCU_29_RMCUVehMotstRoadSurf 30;
BA_ "GenSigStartValue" SG_ 279 HCU_29_RMCUVehMotstRoadSurf 5;
BA_ "GenSigSendType" SG_ 279 HCU_29_RMCUVehMotstRoadSurf 0;
BA_ "GenSigSendType" SG_ 279 HCU_29_CRC2 0;
BA_ "GenSigSendType" SG_ 279 HCU_29_RollgCntr2 0;
BA_ "GenSigSendType" SG_ 279 HCU_29_Resd2 0;
BA_ "GenSigInvalidValue" SG_ 279 HCU_29_RMCUMinTorqueLimit 4095;
BA_ "GenSigStartValue" SG_ 279 HCU_29_RMCUMinTorqueLimit 2000;
BA_ "ASIL" SG_ 279 HCU_29_RMCUMinTorqueLimit 3;
BA_ "GenSigSendType" SG_ 279 HCU_29_RMCUMinTorqueLimit 0;
BA_ "GenSigSendType" SG_ 279 HCU_29_RMCUMaxPwrLimit 0;
BA_ "GenSigSendType" SG_ 279 HCU_RMCU_ActiveHeatHvDcFreqReq 0;
BA_ "GenSigSendType" SG_ 279 HCU_29_RearEDLReq 0;
BA_ "GenSigSendType" SG_ 279 HCU_P4_TorqueAllowed 0;
BA_ "GenSigInvalidValue" SG_ 279 HCU_29_RMCUMaxTorqueDampgCtl_Res 255;
BA_ "GenSigSendType" SG_ 279 HCU_29_RMCUMaxTorqueDampgCtl_Res 0;
BA_ "GenSigSendType" SG_ 279 HCU_29_CRC3 0;
BA_ "GenSigSendType" SG_ 279 HCU_29_RollgCntr3 0;
BA_ "GenSigSendType" SG_ 279 HCU_29_Resd3 0;
BA_ "GenSigInvalidValue" SG_ 279 HCU_29_RMCUSpdSet 65535;
BA_ "GenSigStartValue" SG_ 279 HCU_29_RMCUSpdSet 32767;
BA_ "GenSigSendType" SG_ 279 HCU_29_RMCUSpdSet 0;
BA_ "GenSigStartValue" SG_ 279 HCU_29_RMCUMinPwrLimit 4000;
BA_ "GenSigSendType" SG_ 279 HCU_29_RMCUMinPwrLimit 0;
BA_ "ASIL" SG_ 279 HCU_29_RMCURequestedState 3;
BA_ "GenSigSendType" SG_ 279 HCU_29_RMCURequestedState 0;
BA_ "GenSigInvalidValue" SG_ 279 HCU_29_RMCUBoostPwrReq 2047;
BA_ "GenSigSendType" SG_ 279 HCU_29_RMCUBoostPwrReq 0;
BA_ "GenSigSendType" SG_ 279 HCU_RMCU_LimpReq 0;
BA_ "GenSigSendType" SG_ 279 HCU_29_RMCUDampReq 0;
BA_ "GenSigSendType" SG_ 279 HCU_29_RMCUBoostStateReq 0;
BA_ "GenSigSendType" SG_ 279 HCU_29_CRC4 0;
BA_ "GenSigSendType" SG_ 279 HCU_29_RollgCntr4 0;
BA_ "GenSigSendType" SG_ 279 HCU_29_Resd4 0;
BA_ "GenSigStartValue" SG_ 279 HCU_29_RMCU_RequestGear 2;
BA_ "ASIL" SG_ 279 HCU_29_RMCU_RequestGear 3;
BA_ "GenSigSendType" SG_ 279 HCU_29_RMCU_RequestGear 0;
BA_ "GenSigInvalidValue" SG_ 279 HCU_29_RMCUHeatPwrLimit 63;
BA_ "GenSigSendType" SG_ 279 HCU_29_RMCUHeatPwrLimit 0;
BA_ "GenSigSendType" SG_ 279 HCU_RMCU_ActiveHeatHvDcAmpReq 0;
BA_ "ASIL" SG_ 279 HCU_29_RMCU_ShiftingRequest 3;
BA_ "GenSigSendType" SG_ 279 HCU_29_RMCU_ShiftingRequest 0;
BA_ "GenSigSendType" SG_ 279 HCU_RMCU_ActiveHeatHvDcAmpHiLim 0;
BA_ "GenSigSendType" SG_ 279 HCU_RMCU_ActiveHeatHvDcAmpLoLim 0;
BA_ "GenSigSendType" SG_ 279 HCU_29_CRC5 0;
BA_ "GenSigSendType" SG_ 279 HCU_29_RollgCntr5 0;
BA_ "GenSigSendType" SG_ 279 HCU_29_Resd5 0;
BA_ "GenSigSendType" SG_ 279 HCU_RMCU_ActiveHeatHvDFreqHiLim 0;
BA_ "GenSigSendType" SG_ 279 HCU_29_ADSRMCUTqUnloadEna 0;
BA_ "GenSigSendType" SG_ 279 HCU_RMCU_ActiveHeatHvDcFreqLoLim 0;
BA_ "GenSigInvalidValue" SG_ 279 HCU_BMSVehDcChrgnIDmd 16383;
BA_ "GenSigStartValue" SG_ 279 HCU_BMSVehDcChrgnIDmd 10240;
BA_ "GenSigSendType" SG_ 279 HCU_BMSVehDcChrgnIDmd 0;
BA_ "GenSigSendType" SG_ 279 HCU_29_NeutralGearSlide 0;
BA_ "GenSigSendType" SG_ 279 HCU_29_CRC6 0;
BA_ "GenSigSendType" SG_ 279 HCU_29_RollgCntr6 0;
BA_ "GenSigSendType" SG_ 279 HCU_29_Resd6 0;
BA_ "GenSigInvalidValue" SG_ 279 HCU_BMSVehDcChrgnUDmd 16383;
BA_ "GenSigSendType" SG_ 279 HCU_BMSVehDcChrgnUDmd 0;
BA_ "GenSigSendType" SG_ 279 HCU_DCB_InputVolt 0;
BA_ "GenSigSendType" SG_ 279 HCU_DCB_BoostNegRelaySts 0;
BA_ "GenSigSendType" SG_ 279 HCU_DCB_BoostPosRelaySts 0;
BA_ "GenSigSendType" SG_ 279 HCU_DCB_C2RelaySts 0;
BA_ "GenSigSendType" SG_ 279 HCU_29_CRC7 0;
BA_ "GenSigSendType" SG_ 279 HCU_29_RollgCntr7 0;
BA_ "GenSigSendType" SG_ 279 HCU_29_Resd7 0;
BA_ "GenSigInvalidValue" SG_ 279 HCU_29_RMCUDesiredFFTorque 4095;
BA_ "GenSigStartValue" SG_ 279 HCU_29_RMCUDesiredFFTorque 2000;
BA_ "GenSigSendType" SG_ 279 HCU_29_RMCUDesiredFFTorque 0;
BA_ "GenSigInvalidValue" SG_ 279 HCU_29_FMCUDesiredFFTorque 4095;
BA_ "GenSigStartValue" SG_ 279 HCU_29_FMCUDesiredFFTorque 2000;
BA_ "GenSigSendType" SG_ 279 HCU_29_FMCUDesiredFFTorque 0;
BA_ "GenSigInvalidValue" SG_ 306 SAM_1_SteeringAngle 65535;
BA_ "GenSigStartValue" SG_ 306 SAM_1_SteeringAngle 65535;
BA_ "GenSigSendType" SG_ 306 SAM_1_SteeringAngle 0;
BA_ "GenSigInvalidValue" SG_ 306 SAM_1_SteeringAngleSpeed 255;
BA_ "GenSigStartValue" SG_ 306 SAM_1_SteeringAngleSpeed 255;
BA_ "GenSigSendType" SG_ 306 SAM_1_SteeringAngleSpeed 0;
BA_ "GenSigStartValue" SG_ 306 SAM_1_SteeringAngleSpeedVD 1;
BA_ "GenSigSendType" SG_ 306 SAM_1_SteeringAngleSpeedVD 0;
BA_ "GenSigStartValue" SG_ 306 SAM_1_SteeringAngleVD 1;
BA_ "GenSigSendType" SG_ 306 SAM_1_SteeringAngleVD 0;
BA_ "GenSigSendType" SG_ 306 SAM_1_SASCalibrated 0;
BA_ "GenSigSendType" SG_ 306 SAM_1_SASInit 0;
BA_ "GenSigSendType" SG_ 306 SAM_1_AngleFailure 0;
BA_ "GenSigSendType" SG_ 322 RMCU_TCUR_ShiftGearOperSt 0;
BA_ "GenSigSendType" SG_ 322 TCUR_GearSt 0;
BA_ "GenSigSendType" SG_ 322 RMCU_TCUR_ShiftGearReq 0;
BA_ "GenSigSendType" SG_ 322 RMCU_TCUR_RdToSleep 0;
BA_ "GenSigSendType" SG_ 322 RMCU_GbxStMac 0;
BA_ "GenSigSendType" SG_ 322 TCUR_GearPosnMeasRaw 0;
BA_ "GenSigSendType" SG_ 322 TCUR_SleepComfirm 0;
BA_ "GenSigSendType" SG_ 322 RMCU_MCUGearShiftAllwFlg 0;
BA_ "GenSigSendType" SG_ 322 TCUR_ActrOperSt 0;
BA_ "GenSigSendType" SG_ 419 HCU_26_CRC1 0;
BA_ "GenSigSendType" SG_ 419 HCU_26_RollgCntr1 0;
BA_ "GenSigSendType" SG_ 419 HCU_ENG_TorqueAllowed 0;
BA_ "GenSigSendType" SG_ 419 HCU_26_TargetGearTransInp 0;
BA_ "GenSigSendType" SG_ 419 HCU_26_OptMode 0;
BA_ "GenSigSendType" SG_ 419 HCU_26_TargetGearEM2 0;
BA_ "GenSigSendType" SG_ 419 PowertrainModeDes 0;
BA_ "GenSigSendType" SG_ 419 HCU_26_FrntEDLReq 0;
BA_ "GenSigSendType" SG_ 419 HCU_26_InputClutchIntervention 0;
BA_ "GenSigSendType" SG_ 419 GasPedalPosition 0;
BA_ "GenSigSendType" SG_ 419 BrakePedalStsValidDataForTCU 0;
BA_ "GenSigSendType" SG_ 419 BrakePedalStsForTCU 0;
BA_ "GenSigInvalidValue" SG_ 419 GasPedalPositionInvalidData 1;
BA_ "GenSigSendType" SG_ 419 GasPedalPositionInvalidData 0;
BA_ "GenSigSendType" SG_ 419 TargetGearTransInp 0;
BA_ "GenSigSendType" SG_ 419 HCU_26_ADSFMCUTqUnloadEna 0;
BA_ "GenSigStartValue" SG_ 419 HCU_TMCU_EmsTqReqSlow 1020;
BA_ "GenSigSendType" SG_ 419 HCU_TMCU_EmsTqReqSlow 0;
BA_ "GenSigSendType" SG_ 419 HCU_26_EMS_FuelcutReq 0;
BA_ "GenSigSendType" SG_ 419 HCU_TMCU_CntrAllowMode 0;
BA_ "GenSigSendType" SG_ 419 HCU_26_CRC2 0;
BA_ "GenSigSendType" SG_ 419 HCU_26_RollgCntr2 0;
BA_ "GenSigSendType" SG_ 419 HCU_26_Resd2 0;
BA_ "GenSigStartValue" SG_ 419 HCU_26_IndicatedDriverReqWhlTqFA 32768;
BA_ "GenSigSendType" SG_ 419 HCU_26_IndicatedDriverReqWhlTqFA 0;
BA_ "GenSigStartValue" SG_ 419 HCU_26_ActWheelTorqueFA 32768;
BA_ "GenSigSendType" SG_ 419 HCU_26_ActWheelTorqueFA 0;
BA_ "GenSigStartValue" SG_ 419 HCU_26_ActWheelTorqueRA 32768;
BA_ "GenSigSendType" SG_ 419 HCU_26_ActWheelTorqueRA 0;
BA_ "GenSigSendType" SG_ 419 HCU_26_CRC3 0;
BA_ "GenSigSendType" SG_ 419 HCU_26_RollgCntr3 0;
BA_ "GenSigSendType" SG_ 419 HCU_26_Resd3 0;
BA_ "GenSigSendType" SG_ 419 HCU_AccessoriesCosumePower 0;
BA_ "GenSigSendType" SG_ 419 HCU_26_PRNDGearTargetValidData 0;
BA_ "GenSigSendType" SG_ 419 HCU_26_PRNDGearActValidData 0;
BA_ "GenSigSendType" SG_ 419 HCU_26_TransInpTarSpd 0;
BA_ "GenSigSendType" SG_ 419 HCU_26_ADSFMCUTqUnloadRate 0;
BA_ "GenSigSendType" SG_ 419 HCU_RearEDDReq_1A3h 0;
BA_ "GenSigSendType" SG_ 419 HCU_26_TransInpActSpd 0;
BA_ "GenSigSendType" SG_ 419 HCU_26_TransEM1TrqTar 0;
BA_ "GenSigSendType" SG_ 419 HCU_26_C1CapacityTarget 0;
BA_ "GenSigSendType" SG_ 419 HCU_26_PRNDGearTarget 0;
BA_ "GenSigSendType" SG_ 419 HCU_26_PRNDGearAct 0;
BA_ "GenSigSendType" SG_ 419 HCU_26_ShiftUrgency 0;
BA_ "GenSigSendType" SG_ 419 HCU_26_TransInpTrqAct 0;
BA_ "GenSigSendType" SG_ 419 HCU_26_TransInpTrqTar 0;
BA_ "GenSigSendType" SG_ 419 HCU_26_TransInpTrqMin 0;
BA_ "GenSigSendType" SG_ 419 HCU_26_EM2TrqTar 0;
BA_ "GenSigSendType" SG_ 419 HCU_26_ADSFMCUMotTqRateLimMin 0;
BA_ "GenSigSendType" SG_ 419 HCU_26_ADSFMCUMotTqRateLimMax 0;
BA_ "GenSigSendType" SG_ 419 HCU_26_Activeheat 0;
BA_ "GenSigSendType" SG_ 419 HCU_26_ECGPOvrd 0;
BA_ "GenSigStartValue" SG_ 419 HCU_26_ErrorMotorSpeedRA 1;
BA_ "GenSigSendType" SG_ 419 HCU_26_ErrorMotorSpeedRA 0;
BA_ "GenSigSendType" SG_ 419 HCU_26_EpsOnReq 0;
BA_ "GenSigSendType" SG_ 419 HCU_26_C1CapacityState 0;
BA_ "GenSigSendType" SG_ 419 HCU_26_EngineStartType 0;
BA_ "GenSigSendType" SG_ 419 HCU_26_FMCUMaxActiveheatPwr 0;
BA_ "GenSigSendType" SG_ 419 HCU_26_ECGPOvrdInvalidData 0;
BA_ "GenSigSendType" SG_ 474 FMCU_8_CRC1 0;
BA_ "GenSigSendType" SG_ 474 FMCU_8_RollgCntr1 0;
BA_ "GenSigSendType" SG_ 474 FMCU_8_Resd1 0;
BA_ "GenSigInvalidValue" SG_ 474 FMCU_8_TorqMax 4095;
BA_ "ASIL" SG_ 474 FMCU_8_TorqMax 1;
BA_ "GenSigSendType" SG_ 474 FMCU_8_TorqMax 0;
BA_ "GenSigInvalidValue" SG_ 474 FMCU_8_TorqMin 4095;
BA_ "GenSigStartValue" SG_ 474 FMCU_8_TorqMin 1600;
BA_ "ASIL" SG_ 474 FMCU_8_TorqMin 1;
BA_ "GenSigSendType" SG_ 474 FMCU_8_TorqMin 0;
BA_ "GenSigInvalidValue" SG_ 474 FMCU_8_TorqAct 4095;
BA_ "ASIL" SG_ 474 FMCU_8_TorqAct 3;
BA_ "GenSigSendType" SG_ 474 FMCU_8_TorqAct 0;
BA_ "ASIL" SG_ 474 FMCU_8ModeSt 3;
BA_ "GenSigSendType" SG_ 474 FMCU_8ModeSt 0;
BA_ "GenSigSendType" SG_ 474 FMCU_8_FMCUDeratSts 0;
BA_ "GenSigSendType" SG_ 474 FMCU_8_ErrLvl 0;
BA_ "ASIL" SG_ 474 FMCU_8_DampActive 1;
BA_ "GenSigSendType" SG_ 474 FMCU_8_DampActive 0;
BA_ "GenSigSendType" SG_ 474 FMCU_8_CRC2 0;
BA_ "GenSigSendType" SG_ 474 FMCU_8_RollgCntr2 0;
BA_ "GenSigSendType" SG_ 474 FMCU_8_Resd2 0;
BA_ "GenSigInvalidValue" SG_ 474 FMCU_8_SpdAct 65535;
BA_ "GenSigStartValue" SG_ 474 FMCU_8_SpdAct 32767;
BA_ "ASIL" SG_ 474 FMCU_8_SpdAct 3;
BA_ "GenSigSendType" SG_ 474 FMCU_8_SpdAct 0;
BA_ "GenSigInvalidValue" SG_ 474 FMCU_8_TrqActDampingReq 4095;
BA_ "GenSigStartValue" SG_ 474 FMCU_8_TrqActDampingReq 1400;
BA_ "ASIL" SG_ 474 FMCU_8_TrqActDampingReq 1;
BA_ "GenSigSendType" SG_ 474 FMCU_8_TrqActDampingReq 0;
BA_ "GenSigInvalidValue" SG_ 474 FMCU_8_UdcAct 1023;
BA_ "GenSigStartValue" SG_ 474 FMCU_8_UdcAct 1022;
BA_ "ASIL" SG_ 474 FMCU_8_UdcAct 3;
BA_ "GenSigSendType" SG_ 474 FMCU_8_UdcAct 0;
BA_ "ASIL" SG_ 474 FMCU_8_ISGF_DampActive 1;
BA_ "GenSigSendType" SG_ 474 FMCU_8_ISGF_DampActive 0;
BA_ "GenSigStartValue" SG_ 474 FMCU_8_InterlockStatus 1;
BA_ "GenSigSendType" SG_ 474 FMCU_8_InterlockStatus 0;
BA_ "GenSigSendType" SG_ 474 FMCU_8_ISGF_ErrLvl 0;
BA_ "ASIL" SG_ 474 FMCU_8_ISGF_ModeSt 1;
BA_ "GenSigSendType" SG_ 474 FMCU_8_ISGF_ModeSt 0;
BA_ "GenSigSendType" SG_ 474 FMCU_8_CRC3 0;
BA_ "GenSigSendType" SG_ 474 FMCU_8_RollgCntr3 0;
BA_ "GenSigSendType" SG_ 474 FMCU_8_Resd3 0;
BA_ "GenSigInvalidValue" SG_ 474 FMCU_8_IdcAct 2047;
BA_ "GenSigStartValue" SG_ 474 FMCU_8_IdcAct 1023;
BA_ "ASIL" SG_ 474 FMCU_8_IdcAct 3;
BA_ "GenSigSendType" SG_ 474 FMCU_8_IdcAct 0;
BA_ "GenSigInvalidValue" SG_ 474 FMCU_8_ISGF_SpdAct 65535;
BA_ "GenSigStartValue" SG_ 474 FMCU_8_ISGF_SpdAct 32767;
BA_ "ASIL" SG_ 474 FMCU_8_ISGF_SpdAct 1;
BA_ "GenSigSendType" SG_ 474 FMCU_8_ISGF_SpdAct 0;
BA_ "GenSigInvalidValue" SG_ 474 FMCU_8_ISGF_TorqMax 1023;
BA_ "ASIL" SG_ 474 FMCU_8_ISGF_TorqMax 1;
BA_ "GenSigSendType" SG_ 474 FMCU_8_ISGF_TorqMax 0;
BA_ "GenSigInvalidValue" SG_ 474 FMCU_8_ISGF_TorqAct 2047;
BA_ "GenSigStartValue" SG_ 474 FMCU_8_ISGF_TorqAct 1020;
BA_ "ASIL" SG_ 474 FMCU_8_ISGF_TorqAct 1;
BA_ "GenSigSendType" SG_ 474 FMCU_8_ISGF_TorqAct 0;
BA_ "GenSigSendType" SG_ 474 FMCU_8_CRC4 0;
BA_ "GenSigSendType" SG_ 474 FMCU_8_RollgCntr4 0;
BA_ "GenSigSendType" SG_ 474 FMCU_8_Resd4 0;
BA_ "GenSigInvalidValue" SG_ 474 FMCU_8_ISGF_TorqMin 1023;
BA_ "GenSigStartValue" SG_ 474 FMCU_8_ISGF_TorqMin 1020;
BA_ "ASIL" SG_ 474 FMCU_8_ISGF_TorqMin 1;
BA_ "GenSigSendType" SG_ 474 FMCU_8_ISGF_TorqMin 0;
BA_ "GenSigInvalidValue" SG_ 474 FMCU_8_ISGF_IdcAct 2047;
BA_ "GenSigStartValue" SG_ 474 FMCU_8_ISGF_IdcAct 1023;
BA_ "ASIL" SG_ 474 FMCU_8_ISGF_IdcAct 1;
BA_ "GenSigSendType" SG_ 474 FMCU_8_ISGF_IdcAct 0;
BA_ "GenSigInvalidValue" SG_ 474 FMCU_8_ISGF_UdcAct 1023;
BA_ "GenSigSendType" SG_ 474 FMCU_8_ISGF_UdcAct 0;
BA_ "GenSigSendType" SG_ 474 FMCU_8_ActiveheatReq 0;
BA_ "ASIL" SG_ 474 FMCU_8_ISGF_DischargeState 3;
BA_ "GenSigSendType" SG_ 474 FMCU_8_ISGF_DischargeState 0;
BA_ "GenSigSendType" SG_ 474 FMCU_8_CRC5 0;
BA_ "GenSigSendType" SG_ 474 FMCU_8_RollgCntr5 0;
BA_ "GenSigSendType" SG_ 474 FMCU_8_Resd5 0;
BA_ "GenSigInvalidValue" SG_ 474 FMCU_8_ISGF_TrqActDampingReq 2047;
BA_ "GenSigStartValue" SG_ 474 FMCU_8_ISGF_TrqActDampingReq 1020;
BA_ "ASIL" SG_ 474 FMCU_8_ISGF_TrqActDampingReq 1;
BA_ "GenSigSendType" SG_ 474 FMCU_8_ISGF_TrqActDampingReq 0;
BA_ "GenSigSendType" SG_ 474 FMCU_8_ISGF_GateDrvSt 0;
BA_ "GenSigSendType" SG_ 474 FMCU_8_LimpAllow 0;
BA_ "GenSigSendType" SG_ 474 FMCU_8_Limp 0;
BA_ "GenSigSendType" SG_ 474 FMCU_8_CRC6 0;
BA_ "GenSigSendType" SG_ 474 FMCU_8_RollgCntr6 0;
BA_ "GenSigSendType" SG_ 474 FMCU_8_Resd6 0;
BA_ "GenSigInvalidValue" SG_ 474 FMCU_8_InvTemp 255;
BA_ "GenSigStartValue" SG_ 474 FMCU_8_InvTemp 250;
BA_ "ASIL" SG_ 474 FMCU_8_InvTemp 1;
BA_ "GenSigSendType" SG_ 474 FMCU_8_InvTemp 0;
BA_ "GenSigInvalidValue" SG_ 474 FMCU_8_ISGF_InvTemp 255;
BA_ "GenSigStartValue" SG_ 474 FMCU_8_ISGF_InvTemp 40;
BA_ "ASIL" SG_ 474 FMCU_8_ISGF_InvTemp 1;
BA_ "GenSigSendType" SG_ 474 FMCU_8_ISGF_InvTemp 0;
BA_ "GenSigSendType" SG_ 474 FMCU_8_MCUActRUnfilteredRodSpd 0;
BA_ "GenSigSendType" SG_ 474 FMCU_8_MCUReqTq 0;
BA_ "GenSigSendType" SG_ 474 FMCU_8_MCUModActvSt 0;
BA_ "GenSigSendType" SG_ 474 FMCU_8_SpdSvModAvl 0;
BA_ "GenSigSendType" SG_ 474 FMCU_E_ClutchStus 0;
BA_ "GenSigSendType" SG_ 474 FMCU_E_ClutchEngMilLampReq 0;
BA_ "GenSigSendType" SG_ 474 FMCU_8_MCUSpdSVModFlt 0;
BA_ "GenSigSendType" SG_ 474 FMCU_8_MCUVehSldSt 0;
BA_ "GenSigSendType" SG_ 474 FMCU_8_MCUStandstill 0;
BA_ "GenSigSendType" SG_ 474 FMCU_8_MCUBlkSt 0;
BA_ "GenSigSendType" SG_ 474 FMCU_8_ISGActRUnfilteredRodSpd 0;
BA_ "GenSigSendType" SG_ 474 FMCU_8_ISGReqTq 0;
BA_ "GenSigSendType" SG_ 474 FMCU_8_ISGModActvSt 0;
BA_ "GenSigSendType" SG_ 474 FMCU_8_ISGSpdSvModAvl 0;
BA_ "GenSigSendType" SG_ 474 FMCU_8_ISGSpdSVModFlt 0;
BA_ "GenSigSendType" SG_ 474 FMCU_8_ISGVehSldSt 0;
BA_ "GenSigSendType" SG_ 474 FMCU_8_ISGStandstill 0;
BA_ "GenSigSendType" SG_ 474 FMCU_8_ISGBlkSt 0;
BA_ "GenSigSendType" SG_ 474 FMCU_E_ClutchErrLvl 0;
BA_ "GenSigSendType" SG_ 474 FMCU_8_MCU_SpdActValidData 0;
BA_ "GenSigSendType" SG_ 474 FMCU_8_ActiveheatPwrAct 0;
BA_ "GenSigSendType" SG_ 474 FMCU_E_ClutchCurr 0;
BA_ "GenSigSendType" SG_ 474 FMCU_E_ClutchActMod 0;
BA_ "GenSigSendType" SG_ 474 FMCU_8_ISGF_PositionCtrSts 0;
BA_ "GenSigSendType" SG_ 474 FMCU_8_ISGF_SpdAcValidData 0;
BA_ "GenSigSendType" SG_ 474 ECluAvlTq 0;
BA_ "GenSigSendType" SG_ 485 RMCU_1_CRC1 0;
BA_ "GenSigSendType" SG_ 485 RMCU_1_RollgCntr1 0;
BA_ "GenSigSendType" SG_ 485 RMCU_1_Resd1 0;
BA_ "GenSigInvalidValue" SG_ 485 RMCU_MaxTorque 4095;
BA_ "GenSigSendType" SG_ 485 RMCU_MaxTorque 0;
BA_ "GenSigInvalidValue" SG_ 485 RMCU_MinTorque 4095;
BA_ "GenSigStartValue" SG_ 485 RMCU_MinTorque 2000;
BA_ "GenSigSendType" SG_ 485 RMCU_MinTorque 0;
BA_ "GenSigInvalidValue" SG_ 485 RMCU_1_OutputTorque 4095;
BA_ "GenSigStartValue" SG_ 485 RMCU_1_OutputTorque 4004;
BA_ "ASIL" SG_ 485 RMCU_1_OutputTorque 3;
BA_ "GenSigSendType" SG_ 485 RMCU_1_OutputTorque 0;
BA_ "GenSigSendType" SG_ 485 RMCU_State 0;
BA_ "GenSigInvalidValue" SG_ 485 RMCU_1_InverterTemperature 255;
BA_ "GenSigStartValue" SG_ 485 RMCU_1_InverterTemperature 250;
BA_ "GenSigSendType" SG_ 485 RMCU_1_InverterTemperature 0;
BA_ "GenSigSendType" SG_ 485 RMCU_1_CRC2 0;
BA_ "GenSigSendType" SG_ 485 RMCU_1_RollgCntr2 0;
BA_ "GenSigSendType" SG_ 485 RMCU_1_Resd2 0;
BA_ "GenSigInvalidValue" SG_ 485 RMCU_TrqActDampingReq 4095;
BA_ "GenSigStartValue" SG_ 485 RMCU_TrqActDampingReq 2000;
BA_ "GenSigSendType" SG_ 485 RMCU_TrqActDampingReq 0;
BA_ "GenSigSendType" SG_ 485 RMCU_RMCUDeratSts 0;
BA_ "GenSigInvalidValue" SG_ 485 RMCU_1_VoltageHV 1023;
BA_ "GenSigStartValue" SG_ 485 RMCU_1_VoltageHV 1022;
BA_ "GenSigSendType" SG_ 485 RMCU_1_VoltageHV 0;
BA_ "GenSigSendType" SG_ 485 RMCU_ElockWorkStatusAct 0;
BA_ "GenSigSendType" SG_ 485 RMCU_1_MCU_SpdActValidData 0;
BA_ "GenSigInvalidValue" SG_ 485 RMCU_1_Speed 65535;
BA_ "GenSigStartValue" SG_ 485 RMCU_1_Speed 32767;
BA_ "ASIL" SG_ 485 RMCU_1_Speed 3;
BA_ "GenSigSendType" SG_ 485 RMCU_1_Speed 0;
BA_ "GenSigSendType" SG_ 485 RMCU_1_CRC3 0;
BA_ "GenSigSendType" SG_ 485 RMCU_1_RollgCntr3 0;
BA_ "GenSigSendType" SG_ 485 RMCU_1_Resd3 0;
BA_ "GenSigInvalidValue" SG_ 485 RMCU_1_MAXBoostPwr 1023;
BA_ "GenSigSendType" SG_ 485 RMCU_1_MAXBoostPwr 0;
BA_ "GenSigSendType" SG_ 485 RMCU_ErrLvl 0;
BA_ "GenSigSendType" SG_ 485 RMCU_1_BoostSts 0;
BA_ "GenSigInvalidValue" SG_ 485 RMCU_1_CurrentHV 2047;
BA_ "GenSigSendType" SG_ 485 RMCU_1_CurrentHV 0;
BA_ "GenSigInvalidValue" SG_ 485 RMCU_HeatPwrAct 511;
BA_ "GenSigSendType" SG_ 485 RMCU_HeatPwrAct 0;
BA_ "GenSigInvalidValue" SG_ 485 RMCU_MAXHeatPwr 511;
BA_ "GenSigSendType" SG_ 485 RMCU_MAXHeatPwr 0;
BA_ "GenSigSendType" SG_ 485 RMCU_DampActive 0;
BA_ "GenSigStartValue" SG_ 485 RMCU_InterlockStatus 1;
BA_ "GenSigSendType" SG_ 485 RMCU_InterlockStatus 0;
BA_ "GenSigSendType" SG_ 485 RMCU_1_SpdSvModAvl 0;
BA_ "GenSigSendType" SG_ 485 RMCU_1_CRC4 0;
BA_ "GenSigSendType" SG_ 485 RMCU_1_RollgCntr4 0;
BA_ "GenSigSendType" SG_ 485 RMCU_1_Resd4 0;
BA_ "GenSigSendType" SG_ 485 RMCU_1_MCUModActvSt 0;
BA_ "GenSigSendType" SG_ 485 RMCU_1_BSTNRelayReqAct 0;
BA_ "GenSigSendType" SG_ 485 RMCU_1_BSTPRelayReqAct 0;
BA_ "GenSigSendType" SG_ 485 RMCU_1_MCUStandstill 0;
BA_ "GenSigSendType" SG_ 485 RMCU_1_MCUVehSldSt 0;
BA_ "GenSigSendType" SG_ 485 RMCU_1_BoostErrLvl 0;
BA_ "GenSigSendType" SG_ 485 RMCU_1_BSTPrechargeRelayAct 0;
BA_ "GenSigSendType" SG_ 485 RMCU_1_NeutralGearUnavailable 0;
BA_ "GenSigSendType" SG_ 485 RMCU_1_GearShiftProgFlag 0;
BA_ "GenSigSendType" SG_ 485 RMCU_1_GearShiftAllw 0;
BA_ "GenSigStartValue" SG_ 485 RMCU_1_CurrGear 15;
BA_ "ASIL" SG_ 485 RMCU_1_CurrGear 3;
BA_ "GenSigSendType" SG_ 485 RMCU_1_CurrGear 0;
BA_ "GenSigSendType" SG_ 485 RMCU_1_GearSelfStudySts 0;
BA_ "GenSigSendType" SG_ 485 RMCU_1_TCURErrLvlDis 0;
BA_ "GenSigSendType" SG_ 485 RMCU_1_2ndGearUnavailable 0;
BA_ "GenSigSendType" SG_ 485 RMCU_1_1stGearUnavailable 0;
BA_ "GenSigSendType" SG_ 485 RMCU_1_MCUActRUnfilteredRodSpd 0;
BA_ "GenSigSendType" SG_ 485 RMCU_1_CRC5 0;
BA_ "GenSigSendType" SG_ 485 RMCU_1_RollgCntr5 0;
BA_ "GenSigSendType" SG_ 485 RMCU_1_ActiveHeatHvDcAmpAct 0;
BA_ "GenSigSendType" SG_ 485 RMCU_1_LimpAllow 0;
BA_ "GenSigSendType" SG_ 485 RMCU_1_ShiftReqProtd 0;
BA_ "GenSigSendType" SG_ 485 RMCU_1_ActiveHeatHvDcFreqAct 0;
BA_ "GenSigSendType" SG_ 485 RMCU_1_MCUReqTq 0;
BA_ "GenSigSendType" SG_ 485 RMCU_1_MCUBlkSt 0;
BA_ "GenSigSendType" SG_ 485 RMCU_GBFaultstatus 0;
BA_ "GenSigSendType" SG_ 485 RMCU_1_RotorPosition 0;
BA_ "GenSigSendType" SG_ 485 RMCU_1_MCUSpdSVModFlt 0;
BA_ "GenSigSendType" SG_ 485 RMCU_1_CRC6 0;
BA_ "GenSigSendType" SG_ 485 RMCU_1_RollgCntr6 0;
BA_ "GenSigSendType" SG_ 485 RMCU_EDD_RearEDDStMac 0;
BA_ "GenSigSendType" SG_ 485 RMCU_EDD_RearEDDOperSt 0;
BA_ "GenSigSendType" SG_ 485 RMCU_EDD_RearEDDSts 0;
BA_ "GenSigSendType" SG_ 485 RMCU_EDD_RearEDDFaultCode 0;
BA_ "GenSigSendType" SG_ 485 RMCU_EDD_RearEDDCnctDisAllwReas 0;
BA_ "GenSigSendType" SG_ 485 RMCU_EDD_RearEDDConnectAllwFlg 0;
BA_ "GenSigSendType" SG_ 485 RMCU_EDD_RearEDDErrLvlDis 0;
BA_ "GenSigSendType" SG_ 485 RMCU_EDD_RearEDDPosnMeasRaw 0;
BA_ "GenSigStartValue" SG_ 501 FMCU_NegTrqAvailMin_2s 1400;
BA_ "GenSigSendType" SG_ 501 FMCU_NegTrqAvailMin_2s 0;
BA_ "GenSigSendType" SG_ 501 FMCU_PosTrqAvailMax_2s 0;
BA_ "GenSigSendType" SG_ 504 HCU_4_CRC1 0;
BA_ "GenSigSendType" SG_ 504 HCU_4_RollgCntr1 0;
BA_ "GenSigSendType" SG_ 504 HCU_4_Resd1 0;
BA_ "GenSigInvalidValue" SG_ 504 HCU_EMS_EngineIdleSpeedMin 255;
BA_ "GenSigStartValue" SG_ 504 HCU_EMS_EngineIdleSpeedMin 60;
BA_ "GenSigSendType" SG_ 504 HCU_EMS_EngineIdleSpeedMin 0;
BA_ "GenSigInvalidValue" SG_ 504 HCU_EMS_EngIdleTorqueCtrl 255;
BA_ "GenSigSendType" SG_ 504 HCU_EMS_EngIdleTorqueCtrl 0;
BA_ "GenSigInvalidValue" SG_ 504 HCU_EMS_TqReqFast 1023;
BA_ "GenSigStartValue" SG_ 504 HCU_EMS_TqReqFast 300;
BA_ "GenSigSendType" SG_ 504 HCU_EMS_TqReqFast 0;
BA_ "GenSigInvalidValue" SG_ 504 HCU_EMS_TqReqSlow 1023;
BA_ "GenSigStartValue" SG_ 504 HCU_EMS_TqReqSlow 300;
BA_ "GenSigSendType" SG_ 504 HCU_EMS_TqReqSlow 0;
BA_ "GenSigSendType" SG_ 504 HCU_EMS_StopReq 0;
BA_ "GenSigSendType" SG_ 504 HCU_EMS_ImmoSts 0;
BA_ "GenSigSendType" SG_ 504 FuelCutOffInhibit 0;
BA_ "GenSigSendType" SG_ 504 FuelCutOffEnable 0;
BA_ "GenSigSendType" SG_ 504 AntiJerkActive 0;
BA_ "GenSigSendType" SG_ 504 DriveSystemActive 0;
BA_ "GenSigSendType" SG_ 504 HCU_EMS_FuelcutReq 0;
BA_ "GenSigSendType" SG_ 504 HCU_EMS_EpsOnReq 0;
BA_ "GenSigSendType" SG_ 504 HCU_EMS_bPepsEngRun 0;
BA_ "GenSigSendType" SG_ 504 EngineFastTorqReqStatus 0;
BA_ "GenSigSendType" SG_ 504 HCU_EMS_MILReq 0;
BA_ "GenSigSendType" SG_ 504 CrankStartReleaseState 0;
BA_ "GenSigSendType" SG_ 504 HCU_4_CRC2 0;
BA_ "GenSigSendType" SG_ 504 HCU_4_RollgCntr2 0;
BA_ "GenSigSendType" SG_ 504 HCU_4_Resd2 0;
BA_ "GenSigInvalidValue" SG_ 504 HCU_EMS_SpdSet 65535;
BA_ "GenSigSendType" SG_ 504 HCU_EMS_SpdSet 0;
BA_ "GenSigInvalidValue" SG_ 504 EM1ActSpd 65535;
BA_ "GenSigSendType" SG_ 504 EM1ActSpd 0;
BA_ "GenSigInvalidValue" SG_ 504 TransEM1TrqAct 4095;
BA_ "GenSigSendType" SG_ 504 TransEM1TrqAct 0;
BA_ "GenSigSendType" SG_ 504 HCU_EMS_SpdCtrl 0;
BA_ "GenSigSendType" SG_ 504 EngineStartType 0;
BA_ "GenSigSendType" SG_ 504 HCU_4_CRC3 0;
BA_ "GenSigSendType" SG_ 504 HCU_4_RollgCntr3 0;
BA_ "GenSigSendType" SG_ 504 HCU_4_Resd3 0;
BA_ "GenSigInvalidValue" SG_ 504 EM1TrqMax 4095;
BA_ "GenSigSendType" SG_ 504 EM1TrqMax 0;
BA_ "GenSigSendType" SG_ 504 PowertrainModeAct 0;
BA_ "GenSigSendType" SG_ 504 MotorReadyFA 0;
BA_ "GenSigSendType" SG_ 504 ICEReady 0;
BA_ "GenSigSendType" SG_ 504 EngineSlowTorqReqStatus 0;
BA_ "GenSigSendType" SG_ 504 HCU_14_DashPotActive 0;
BA_ "GenSigSendType" SG_ 504 HCU_EMS_WaterPumpDutyReq 0;
BA_ "GenSigSendType" SG_ 520 BMS_2_CRC1 0;
BA_ "GenSigSendType" SG_ 520 BMS_2_RollgCntr1 0;
BA_ "GenSigSendType" SG_ 520 BMS_2_Resd1 0;
BA_ "GenSigInvalidValue" SG_ 520 BMS_C2Target_Chg_Voltage 65535;
BA_ "GenSigSendType" SG_ 520 BMS_C2Target_Chg_Voltage 0;
BA_ "GenSigSendType" SG_ 520 BMS_NV_relay_Sts 0;
BA_ "GenSigSendType" SG_ 520 BMS_PV_relay_Sts 0;
BA_ "GenSigSendType" SG_ 520 BMS_QCP_relay_Sts 0;
BA_ "GenSigSendType" SG_ 520 BMS_Prechage_relay_Sts 0;
BA_ "GenSigInvalidValue" SG_ 520 BMS_OutPosU 16383;
BA_ "GenSigStartValue" SG_ 520 BMS_OutPosU 16382;
BA_ "GenSigSendType" SG_ 520 BMS_OutPosU 0;
BA_ "GenSigInvalidValue" SG_ 520 BMS_outQCPosU 16383;
BA_ "GenSigStartValue" SG_ 520 BMS_outQCPosU 16382;
BA_ "GenSigSendType" SG_ 520 BMS_outQCPosU 0;
BA_ "GenSigSendType" SG_ 522 EMS_7_EngTqLimReqTq 0;
BA_ "GenSigSendType" SG_ 522 EMS_7_EngStartInh 0;
BA_ "GenSigInvalidValue" SG_ 522 EMS_7_VentValve 3;
BA_ "GenSigSendType" SG_ 522 EMS_7_VentValve 0;
BA_ "GenSigInvalidValue" SG_ 522 EMS_7_AirIntakeValve 3;
BA_ "GenSigSendType" SG_ 522 EMS_7_AirIntakeValve 0;
BA_ "GenSigSendType" SG_ 522 EMS_7_DiagcTqLimActvnFlg 0;
BA_ "GenSigInvalidValue" SG_ 522 EMS_7_CrkShftPosition 127;
BA_ "GenSigSendType" SG_ 522 EMS_7_CrkShftPosition 0;
BA_ "GenSigStartValue" SG_ 523 BMS_HvBattPMaxReChrgLim 16382;
BA_ "GenSigSendType" SG_ 523 BMS_HvBattPMaxReChrgLim 0;
BA_ "GenSigStartValue" SG_ 523 BMS_HvBattPMaxDchaLim 16382;
BA_ "GenSigSendType" SG_ 523 BMS_HvBattPMaxDchaLim 0;
BA_ "GenSigInvalidValue" SG_ 523 BMSH_MaxChgPwrPeak 4095;
BA_ "GenSigSendType" SG_ 523 BMSH_MaxChgPwrPeak 0;
BA_ "GenSigInvalidValue" SG_ 523 BMSH_MaxDchgPwrPeak 4095;
BA_ "GenSigSendType" SG_ 523 BMSH_MaxDchgPwrPeak 0;
BA_ "GenSigSendType" SG_ 603 FLZCU_2_CRC 0;
BA_ "GenSigSendType" SG_ 603 FLZCU_2_RollgCntr 0;
BA_ "GenSigSendType" SG_ 603 FLZCU_2_Resd 0;
BA_ "GenSigSendType" SG_ 603 FLZCU_2_PowerMode 0;
BA_ "GenSigInvalidValue" SG_ 632 EngineCoolantTemperature 255;
BA_ "GenSigStartValue" SG_ 632 EngineCoolantTemperature 91;
BA_ "GenSigSendType" SG_ 632 EngineCoolantTemperature 0;
BA_ "GenSigInvalidValue" SG_ 632 IntakeAirTemperature 255;
BA_ "GenSigStartValue" SG_ 632 IntakeAirTemperature 50;
BA_ "GenSigSendType" SG_ 632 IntakeAirTemperature 0;
BA_ "GenSigInvalidValue" SG_ 632 AltitudeFactor 255;
BA_ "GenSigStartValue" SG_ 632 AltitudeFactor 63;
BA_ "GenSigSendType" SG_ 632 AltitudeFactor 0;
BA_ "GenSigSendType" SG_ 632 ThrottlePosition 0;
BA_ "GenSigSendType" SG_ 632 EMS_4_EngineSts 0;
BA_ "GenSigSendType" SG_ 632 IntakeAirTemperatureValidData 0;
BA_ "GenSigSendType" SG_ 632 ThrottlePositionValidData 0;
BA_ "GenSigSendType" SG_ 632 IdleSpeedInformation 0;
BA_ "GenSigSendType" SG_ 632 EngineFuelCutOff 0;
BA_ "GenSigInvalidValue" SG_ 753 Test_RMCUDesiredTorque_2F1h 4095;
BA_ "GenSigStartValue" SG_ 753 Test_RMCUDesiredTorque_2F1h 2000;
BA_ "GenSigSendType" SG_ 753 Test_RMCUDesiredTorque_2F1h 0;
BA_ "GenSigSendType" SG_ 753 Test_RMCURequestedState_2F1h 0;
BA_ "GenSigInvalidValue" SG_ 753 Test_RMCUMaxTorqueGradient_2F1h 16383;
BA_ "GenSigSendType" SG_ 753 Test_RMCUMaxTorqueGradient_2F1h 0;
BA_ "GenSigInvalidValue" SG_ 753 Test_RMCUMaxTorqueLimit_2F1h 4095;
BA_ "GenSigStartValue" SG_ 753 Test_RMCUMaxTorqueLimit_2F1h 2000;
BA_ "GenSigSendType" SG_ 753 Test_RMCUMaxTorqueLimit_2F1h 0;
BA_ "GenSigInvalidValue" SG_ 753 Test_RMCUMinTorqueLimit_2F1h 4095;
BA_ "GenSigStartValue" SG_ 753 Test_RMCUMinTorqueLimit_2F1h 2000;
BA_ "GenSigSendType" SG_ 753 Test_RMCUMinTorqueLimit_2F1h 0;
BA_ "GenSigInvalidValue" SG_ 753 Test_RMCUSpdSet_2F1h 65535;
BA_ "GenSigStartValue" SG_ 753 Test_RMCUSpdSet_2F1h 32767;
BA_ "GenSigSendType" SG_ 753 Test_RMCUSpdSet_2F1h 0;
BA_ "GenSigSendType" SG_ 753 Test_SrcSelect_2F1h 0;
VAL_ 33 ACU_3_LongitudinalAccelerationVD 0 "Valid" 1 "Reserved" 2 "Invalid" 3 "Initialize";
VAL_ 33 ACU_3_CrashOutputSts 0 "No crash" 16 "Rear Crash" 32 "Roll Crash" 1 "Belt Crash" 2 "Front Crash" 4 "Left Side Crash" 8 "Right Side Crash";
VAL_ 49 ACU_2_YawrateSigValidData 0 "Valid" 1 "Reserved" 2 "Invalid" 3 "Initialize";
VAL_ 49 ACU_2_LateralAccelerationSigVD 0 "Valid" 1 "Reserved" 2 "Invalid" 3 "Initialize";
VAL_ 152 ABS_ESP_1_ABSFailSts 0 "Not present" 1 "Fail present (lamp on)";
VAL_ 152 ABS_ESP_1_ABSActive 0 "Not active" 1 "Active";
VAL_ 152 ABS_ESP_1_VDCFailSts 0 "Not present" 1 "Fail present (lamp on)";
VAL_ 152 ABS_ESP_1_VDCActive 0 "Not active" 1 "Active";
VAL_ 152 ABS_ESP_1_TCSFailSts 0 "Not present" 1 "Fail present (lamp on)";
VAL_ 152 ABS_ESP_1_TCSActive 0 "Not active" 1 "Active";
VAL_ 152 ABS_ESP_1_ESPSwitchStatus 0 "On" 1 "Disable";
VAL_ 168 RHFWheelSpeedRPMValidData 0 "Valid" 1 "Not Valid";
VAL_ 168 LHFWheelSpeedRPMValidData 0 "Valid" 1 "Not Valid";
VAL_ 168 RHFWheelDriveDirection_0A8h 0 "Init" 1 "Forward" 2 "Backward" 3 "Stop" 4 "Invalid" 5 "reserved" 6 "reserved" 7 "reserved";
VAL_ 168 LHFWheelDriveDirection_0A8h 0 "Init" 1 "Forward" 2 "Backward" 3 "Stop" 4 "Invalid" 5 "reserved" 6 "reserved" 7 "reserved";
VAL_ 168 RHRWheelSpeedRPMValidData 0 "Valid" 1 "Not Valid";
VAL_ 168 LHRWheelSpeedRPMValidData 0 "Valid" 1 "Not Valid";
VAL_ 168 RHRWheelDriveDirection_0A8h 0 "Init" 1 "Forward" 2 "Backward" 3 "Stop" 4 "Invalid" 5 "reserved" 6 "reserved" 7 "reserved";
VAL_ 168 LHRWheelDriveDirection_0A8h 0 "Init" 1 "Forward" 2 "Backward" 3 "Stop" 4 "Invalid" 5 "reserved" 6 "reserved" 7 "reserved";
VAL_ 277 HCU_28_FMCUMaxTorqueGradient 16383 "Invalid";
VAL_ 277 HCU_28_EngineTorqAct 1023 "Invalid";
VAL_ 277 HCU_28_FMCUSpdSet 65535 "Invalid";
VAL_ 277 HCU_28_FMCUMaxTorqDampgCtl 255 "Invalid";
VAL_ 277 HCU_28_FMCURequestedState 0 "Standby" 1 "HV Ready" 2 "Tq Control" 3 "ActiveHeat" 4 "Boost（reserved）" 5 "Power Down" 6 "Emergency Power Down" 7 "Speed Control" 8 "Offset Calibration(DHT)" 9 "reserved" 10 "reserved" 11 "reserved" 12 "reserved" 13 "reserved" 14 "reserved" 15 "reserved";
VAL_ 277 HCU_28_FMCUVehMotstRoadSurf 30 "Invalid";
VAL_ 277 HCU_28_ISGF_ModeReq 0 "LV Standby" 1 "HV Standby (disable)" 2 "Tq Control" 3 "Volt Control" 4 "Spd Control" 5 "Offset Calibration" 6 "Power down (discharge)" 7 "Emergency discharge" 8 "Cur Control(Reserved)" 9 "Position Control" 10 "reserved" 11 "reserved" 12 "reserved" 13 "reserved" 14 "reserved" 15 "reserved";
VAL_ 277 HCU_28_PowertrainModeAct 0 "Init" 1 "Inactive" 2 "N/P Eng Off" 3 "N/P Eng On" 4 "E-Drive-1" 5 "E-Drive-2" 6 "Series-1" 7 "Series-2" 8 "Parallel" 9 "E-Drive-3 (New enumeration, to be added in the next interface update)" 10 "Series-3 (New enumeration, to be added in the next interface update)" 11 "Engine Start" 12 "Engine Stop" 13 "C1 Closing" 14 "C1 Opening" 15 "Service";
VAL_ 277 HCU_28_ISGF_TorqSet 2047 "Invalid";
VAL_ 277 HCU_28_FMCUDampReq 0 "Damping off" 1 "Damping on";
VAL_ 277 HCU_28_Mode 0 "Default mode" 1 "Normal mode" 2 "AC charge mode" 3 "AC discharge mode" 4 "DC charge mode" 5 "DC discharge mode" 6 "Reservation AC charge mode" 7 "12V charge Mode" 8 "Remote control mode" 9 "charge battery heat mode" 10 "Remote battery heat mode";
VAL_ 277 HCU_28_ISGF_TorqMax 1023 "Invalid";
VAL_ 277 HCU_28_ISGF_TorqMin 1023 "Invalid";
VAL_ 277 HCU_28_EngineSts 0 "Not Run" 1 "Run";
VAL_ 277 HCU_28_SleepAllow 0 "Allowed" 1 "Not  Allowed";
VAL_ 277 HCU_28_ISGF_DampReq 0 "Damping off" 1 "Damping on";
VAL_ 277 HCU_28_bEnaEmReq 0 "Disable" 1 "Enable";
VAL_ 277 HCU_28_ISGF_SpdSet 65535 "Invalid";
VAL_ 277 HCU_28_ISGF_MaxTorqDampgCtl 255 "Invalid";
VAL_ 277 HCU_28_NGenrMaxInTqMode 65535 "Invalid";
VAL_ 277 HCU_28_ISGF_MaxTorqGradient 16383 "Invalid";
VAL_ 277 HCU_28_ISGF_Uset 1023 "Invalid";
VAL_ 277 HCU_28_ISGF_LimpPwrReq 255 "Invalid";
VAL_ 277 HCU_28_ISGF_Iset 2047 "Invalid";
VAL_ 277 HCU_28_MaxDisCurrent_ISGF 32767 "Invalid";
VAL_ 277 HCU_28_MaxCharCurrent_ISGF 32767 "Invalid";
VAL_ 277 HCU_FMCUBoostReq 0 "Not Active" 1 "Boost Off" 2 "Boost On";
VAL_ 277 HCU_P3_TorqueAllowed 0 "Allowed" 1 "Not Allowed";
VAL_ 277 HCU_P1_TorqueAllowed 0 "Allowed" 1 "Not Allowed";
VAL_ 277 HCU_28_NeutralGearSlide 0 "NotActive" 1 "Active";
VAL_ 277 HCU_28_FMCU_LimpReq 0 "Not Active" 1 "Active";
VAL_ 279 HCU_29_RMCUDesiredTorque 4095 "Invalid";
VAL_ 279 HCU_29_RMCUMaxTorqueLimit 4095 "Invalid";
VAL_ 279 HCU_29_RMCUMaxTorqueGradient 16383 "Invalid";
VAL_ 279 HCU_29_LowPwrReq 0 "No Req" 1 "Req";
VAL_ 279 HCU_29_RMCUDrvHeatReq 0 "Disable" 1 "Enable";
VAL_ 279 HCU_29_RMCUVehMotstRoadSurf 30 "Invalid";
VAL_ 279 HCU_29_RMCUMinTorqueLimit 4095 "Invalid";
VAL_ 279 HCU_29_RearEDLReq 0 "No Request" 1 "UNLock req" 2 "Lock req" 3 "Researved" 4 "Researved" 5 "Researved" 6 "Researved" 7 "Researved";
VAL_ 279 HCU_P4_TorqueAllowed 0 "Allowed" 1 "Not Allowed";
VAL_ 279 HCU_29_RMCUMaxTorqueDampgCtl_Res 255 "Invalid";
VAL_ 279 HCU_29_RMCUSpdSet 65535 "Invalid";
VAL_ 279 HCU_29_RMCURequestedState 0 "Standby" 1 "HV Ready" 2 "Tq Control" 3 "ActiveHeat" 4 "Boost（reserved）" 5 "Power Down" 6 "Emergency Power Down" 7 "Speed Control" 8 "reserved" 9 "reserved" 10 "reserved" 11 "reserved" 12 "reserved" 13 "reserved" 14 "reserved" 15 "reserved";
VAL_ 279 HCU_29_RMCUBoostPwrReq 2047 "Invalid";
VAL_ 279 HCU_RMCU_LimpReq 0 "Not Active" 1 "Active";
VAL_ 279 HCU_29_RMCUDampReq 0 "Damping off" 1 "Damping on";
VAL_ 279 HCU_29_RMCUBoostStateReq 0 "No Request" 1 "C2 Precharge" 2 "Boost Ready" 3 "Boost Action" 4 "C2_ActiveDischarge" 5 "Reserved" 6 "Reserved" 7 "Reserved";
VAL_ 279 HCU_29_RMCU_RequestGear 0 "Neutral" 1 "1st gear" 2 "2nd gear" 3 "Reserved";
VAL_ 279 HCU_29_RMCUHeatPwrLimit 63 "Invalid";
VAL_ 279 HCU_29_RMCU_ShiftingRequest 0 "disable" 1 "enable";
VAL_ 279 HCU_29_ADSRMCUTqUnloadEna 0 "Disable" 1 "Enable";
VAL_ 279 HCU_BMSVehDcChrgnIDmd 16382 "Error" 16383 "Invalid";
VAL_ 279 HCU_29_NeutralGearSlide 0 "NotActive" 1 "Active";
VAL_ 279 HCU_BMSVehDcChrgnUDmd 16382 "Error" 16383 "Invalid";
VAL_ 279 HCU_DCB_BoostNegRelaySts 0 "Open" 1 "Close" 2 "Stuck Open" 3 "Stuck Close" 4 "Reserved" 5 "Reserved" 6 "Reserved" 7 "Reserved";
VAL_ 279 HCU_DCB_BoostPosRelaySts 0 "Open" 1 "Close" 2 "Stuck Open" 3 "Stuck Close" 4 "Reserved" 5 "Reserved" 6 "Reserved" 7 "Reserved";
VAL_ 279 HCU_DCB_C2RelaySts 0 "Open" 1 "Close" 2 "Stuck Open" 3 "Stuck Close" 4 "Reserved" 5 "Reserved" 6 "Reserved" 7 "Reserved";
VAL_ 306 SAM_1_SteeringAngleSpeedVD 0 "Valid" 1 "Not Valid";
VAL_ 306 SAM_1_SteeringAngleVD 0 "Valid" 1 "Not Valid";
VAL_ 306 SAM_1_SASCalibrated 0 "Not calibrated" 1 "Calibrated";
VAL_ 306 SAM_1_SASInit 0 "Not Initialized" 1 "Initialized";
VAL_ 306 SAM_1_AngleFailure 0 "No Failure" 1 "Failure";
VAL_ 322 RMCU_TCUR_RdToSleep 0 "Don't allow TCUR power-down" 1 "Allow TCUR power-down";
VAL_ 322 TCUR_SleepComfirm 0 "TCUR don't receive the power-down permission flag" 1 "TCUR confirm power-down";
VAL_ 322 RMCU_MCUGearShiftAllwFlg 0 "RMCU don't allow shift gear" 1 "RMCU allow shift gear";
VAL_ 419 HCU_ENG_TorqueAllowed 0 "Allowed" 1 "Not Allowed";
VAL_ 419 HCU_26_TargetGearTransInp 0 "P" 1 "R" 2 "N" 3 "N12" 4 "1" 5 "2";
VAL_ 419 HCU_26_OptMode 0 "Series mode" 1 "Parallel set mode" 2 "Parallel shift mode" 3 "Series to Parallel" 4 "Parallel to Series" 5 "Reserved";
VAL_ 419 HCU_26_TargetGearEM2 0 "Disengage gear" 1 "Gear 1" 2 "Gear 2" 3 "Gear 3";
VAL_ 419 PowertrainModeDes 0 "Init" 1 "Inactive" 2 "N_P_Eng_Off" 3 "N_P_Eng_On" 4 "E-Drive-1" 5 "E-Drive-2" 6 "Series-1" 7 "Series-2" 8 "Parallel" 9 "E-Drive-3_New_Enumeration_To_Be_Added_In_The_Next_Interface_Update" 10 "Series-3_New_Enumeration_To_Be_Added_In_The_Next_Interface_Update" 11 "Engine_Start" 12 "Engine_Stop" 13 "C1_Closing" 14 "C1_Opening" 15 "Service";
VAL_ 419 HCU_26_FrntEDLReq 0 "No Request" 1 "UNLock req" 2 "Lock req" 3 "Researved";
VAL_ 419 HCU_26_InputClutchIntervention 0 "No Intervention" 1 "Intervention request";
VAL_ 419 BrakePedalStsValidDataForTCU 0 "Valid" 1 "Not_Valid";
VAL_ 419 BrakePedalStsForTCU 0 "Not_applied" 1 "applied";
VAL_ 419 GasPedalPositionInvalidData 0 "Valid" 1 "Invalid";
VAL_ 419 TargetGearTransInp 0 "Disengage_Gear" 1 "Gear_1" 2 "Gear_2" 3 "Gear_3";
VAL_ 419 HCU_26_ADSFMCUTqUnloadEna 0 "Disable" 1 "Enable";
VAL_ 419 HCU_26_EMS_FuelcutReq 0 "No Fuelcut Request" 1 "Fuelcut Request";
VAL_ 419 HCU_TMCU_CntrAllowMode 0 "HCU don not allow TMCU control P1/P3/ICE torque" 1 "HCU allow TMCU control P1  torque" 2 "HCU allow TMCU control P3  torque" 3 "HCU allow TMCU control P1+P3  torque" 4 "HCU allow TMCU control ICE  torque" 5 "HCU allow TMCU control P1+ICE  torque" 6 "HCU allow TMCU control P3+ICE  torque" 7 "HCU allow TMCU control P1+P3+ICE  torque with rate limit" 8 "HCU allow TMCU control P3 torque with rate limit during P3 shifting" 9 "HCU allow TMCU control P3 torque without rate limit during P3 shifting" 10 "HCU do not allow TMCU control P3 torque" 15 "HCU allow TMCU control P1+P3+ICE  torque without rate limit";
VAL_ 419 HCU_26_PRNDGearTargetValidData 0 "Not Valid" 1 "Valid";
VAL_ 419 HCU_26_PRNDGearActValidData 0 "Not Valid" 1 "Valid";
VAL_ 419 HCU_RearEDDReq_1A3h 0 "init" 1 "Connect" 2 "Disconnect";
VAL_ 419 HCU_26_PRNDGearTarget 0 "Init" 1 "P" 2 "R" 3 "N" 4 "D" 5 "Reserved" 6 "Reserved" 7 "Reserved";
VAL_ 419 HCU_26_PRNDGearAct 0 "Init" 1 "P" 2 "R" 3 "N" 4 "D" 5 "Reserved" 6 "Reserved" 7 "Reserved";
VAL_ 419 HCU_26_ShiftUrgency 0 "0" 1 "1" 2 "2" 3 "Reserved";
VAL_ 419 HCU_26_Activeheat 0 "Disable" 1 "Enable";
VAL_ 419 HCU_26_ECGPOvrd 0 "No Override" 1 "Driver Override";
VAL_ 419 HCU_26_ErrorMotorSpeedRA 0 "No Error" 1 "Error";
VAL_ 419 HCU_26_EpsOnReq 0 "Request EPS OFF" 1 "Request EPS ON";
VAL_ 419 HCU_26_C1CapacityState 0 "open" 1 "controlled" 2 "closed" 3 "Reserved";
VAL_ 419 HCU_26_EngineStartType 0 "No Start" 1 "12v Start" 2 "Clutch Start" 3 "EM Start" 4 "Combined Start";
VAL_ 419 HCU_26_ECGPOvrdInvalidData 0 "Valid" 1 "Invalid";
VAL_ 474 FMCU_8_TorqMax 4095 "Invalid";
VAL_ 474 FMCU_8_TorqMin 4095 "Invalid";
VAL_ 474 FMCU_8ModeSt 0 "INIT (Initialization)" 1 "Standby" 2 "HV Ready" 3 "Tq Control" 4 "Activeheat_Mode" 5 "Boost_Mode(Reserved)" 6 "PowerDown" 7 "Afterrun" 8 "Fault" 9 "Volt Control(Reserved)" 10 "Spd Control(Reserved)" 11 "Offset Calibration(DHT)" 12 "reserved" 13 "reserved" 14 "reserved" 15 "reserved";
VAL_ 474 FMCU_8_FMCUDeratSts 0 "NoFault" 1 "InvOverTempDerate" 2 "DiffSpeedDerate" 3 "WaterovertempDerate" 4 "MotorOverSpdDerate" 5 "MotorOverTempDerate" 6 "UDcOverVolDerate" 7 "UDcUnderVolDerate" 8 "IacOverCurDrivDerate" 9 "IacOverCurRegenDerate" 10 "reserved" 11 "reserved" 12 "reserved" 13 "reserved" 14 "reserved" 15 "reserved";
VAL_ 474 FMCU_8_ErrLvl 0 "No Error" 1 "Err_level1" 2 "Err_level2" 3 "Err_level3" 4 "Err_level4" 5 "Err_level5" 6 "Err_level6";
VAL_ 474 FMCU_8_DampActive 0 "Not Active" 1 "Active";
VAL_ 474 FMCU_8_SpdAct 65535 "Invalid";
VAL_ 474 FMCU_8_TrqActDampingReq 4095 "Invalid";
VAL_ 474 FMCU_8_UdcAct 1023 "Invalid";
VAL_ 474 FMCU_8_ISGF_DampActive 0 "Not Active" 1 "Active";
VAL_ 474 FMCU_8_InterlockStatus 0 "Not Interlock" 1 "Interlock";
VAL_ 474 FMCU_8_ISGF_ErrLvl 0 "No Error" 1 "Err_level1" 2 "Err_level2" 3 "Err_level3" 4 "Err_level4" 5 "Err_level5" 6 "Err_level6";
VAL_ 474 FMCU_8_ISGF_ModeSt 0 "INIT (Initialization)" 1 "LV Standby (Precharge)" 2 "HV Standby (Disable)" 3 "Tq Control" 4 "Volt Control" 5 "Spd Control" 6 "Offset Calibration" 7 "Powerdown (Discharge)" 8 "Afterrun" 9 "Failure" 10 "Off" 11 "Service" 12 "Cur Control(Reserved)" 13 "Position Control" 14 "reserved" 15 "reserved";
VAL_ 474 FMCU_8_IdcAct 2047 "Invalid";
VAL_ 474 FMCU_8_ISGF_SpdAct 65535 "Invalid";
VAL_ 474 FMCU_8_ISGF_TorqMax 1023 "Invalid";
VAL_ 474 FMCU_8_ISGF_TorqAct 2047 "Invalid";
VAL_ 474 FMCU_8_ISGF_TorqMin 1023 "Invalid";
VAL_ 474 FMCU_8_ISGF_IdcAct 2047 "Invalid";
VAL_ 474 FMCU_8_ISGF_UdcAct 1023 "Invalid";
VAL_ 474 FMCU_8_ActiveheatReq 0 "No Request" 1 "Request";
VAL_ 474 FMCU_8_ISGF_DischargeState 0 "No Discharge" 1 "Discharging" 2 "Discharge Completed" 3 "Discharge Failure";
VAL_ 474 FMCU_8_ISGF_TrqActDampingReq 2047 "Invalid";
VAL_ 474 FMCU_8_ISGF_GateDrvSt 0 "FreeWheel" 1 "PWMrun" 2 "Discharge" 3 "ShortCircuit";
VAL_ 474 FMCU_8_LimpAllow 0 "Not Allow" 1 "Allow";
VAL_ 474 FMCU_8_Limp 0 "Not Active" 1 "Active";
VAL_ 474 FMCU_8_InvTemp 255 "Invalid";
VAL_ 474 FMCU_8_ISGF_InvTemp 255 "Invalid";
VAL_ 474 FMCU_8_MCUModActvSt 0 "Torque mode" 1 "Speed mode" 2 "SV mode";
VAL_ 474 FMCU_8_SpdSvModAvl 0 "Invalid" 1 "Valid";
VAL_ 474 FMCU_E_ClutchStus 0 "Normal" 1 "Fault";
VAL_ 474 FMCU_E_ClutchEngMilLampReq 0 "No Request For MIL Light" 1 "Request For MIL Light";
VAL_ 474 FMCU_8_MCUSpdSVModFlt 0 "No Error" 1 "Absolute value of output torque  too large";
VAL_ 474 FMCU_8_MCUVehSldSt 0 "No Slide" 1 "Slide";
VAL_ 474 FMCU_8_MCUStandstill 0 "No Standstill" 1 "Standstill";
VAL_ 474 FMCU_8_MCUBlkSt 0 "No Stalling" 1 "Stalling";
VAL_ 474 FMCU_8_ISGModActvSt 0 "Torque mode" 1 "Speed mode" 2 "SV mode";
VAL_ 474 FMCU_8_ISGSpdSvModAvl 0 "Invalid" 1 "Valid";
VAL_ 474 FMCU_8_ISGSpdSVModFlt 0 "No Error" 1 "Absolute value of output torque  too large";
VAL_ 474 FMCU_8_ISGVehSldSt 0 "No Slide" 1 "Slide";
VAL_ 474 FMCU_8_ISGStandstill 0 "No Standstill" 1 "Standstill";
VAL_ 474 FMCU_8_ISGBlkSt 0 "No Stalling" 1 "Stalling";
VAL_ 474 FMCU_E_ClutchErrLvl 0 "No Error" 1 "Err_Level1" 2 "Err_Level2" 3 "Err_Level3";
VAL_ 474 FMCU_8_MCU_SpdActValidData 0 "Valid" 1 "Invalid";
VAL_ 474 FMCU_E_ClutchActMod 0 "Open Mode" 1 "Peak Mode" 2 "Hold Mmode" 3 "Peak Timeout" 4 "Fault Mode";
VAL_ 474 FMCU_8_ISGF_PositionCtrSts 0 "default" 1 "Position adjustment in progress" 2 "Position adjustment OK" 3 "Position adjustment abnormal";
VAL_ 474 FMCU_8_ISGF_SpdAcValidData 0 "Valid" 1 "Invalid";
VAL_ 485 RMCU_MaxTorque 4095 "Invalid";
VAL_ 485 RMCU_MinTorque 4095 "Invalid";
VAL_ 485 RMCU_1_OutputTorque 4095 "Invalid";
VAL_ 485 RMCU_State 0 "INIT (Initialization)" 1 "Standby" 2 "HV Ready" 3 "Tq Control" 4 "Activeheat_Mode" 5 "Boost_Mode" 6 "PowerDown" 7 "Afterrun" 8 "Fault" 9 "Volt Control(Reserved)" 10 "Spd Control(Reserved)" 11 "reserved" 12 "reserved" 13 "reserved" 14 "reserved" 15 "reserved";
VAL_ 485 RMCU_TrqActDampingReq 4095 "Invalid";
VAL_ 485 RMCU_RMCUDeratSts 0 "NoFault" 1 "InvOverTempDerate" 2 "DiffSpeedDerate" 3 "WaterovertempDerate" 4 "MotorOverSpdDerate" 5 "MotorOverTempDerate" 6 "UDcOverVolDerate" 7 "UDcUnderVolDerate" 8 "IacOverCurDrivDerate" 9 "IacOverCurRegenDerate" 10 "reserved" 11 "reserved" 12 "reserved" 13 "reserved" 14 "reserved" 15 "reserved";
VAL_ 485 RMCU_1_VoltageHV 1023 "Invalid";
VAL_ 485 RMCU_ElockWorkStatusAct 0 "No Lock" 1 "UNLock" 2 "Lock" 3 "Warning" 4 "UnAvailable" 5 "Stuck Open" 6 "Stuck Close" 7 "Reserved" 8 "Reserved" 9 "Reserved" 10 "Reserved" 11 "Reserved" 12 "Reserved" 13 "Reserved" 14 "Reserved" 15 "Reserved";
VAL_ 485 RMCU_1_MCU_SpdActValidData 0 "Valid" 1 "Invalid";
VAL_ 485 RMCU_1_Speed 65535 "Invalid";
VAL_ 485 RMCU_1_MAXBoostPwr 1023 "Invalid";
VAL_ 485 RMCU_ErrLvl 0 "No Error" 1 "Err_level1" 2 "Err_level2" 3 "Err_level3" 4 "Err_level4" 5 "Err_level5" 6 "Err_level6";
VAL_ 485 RMCU_1_BoostSts 0 "initial" 1 "C2 Capacitor Precharge" 2 "Boost Ready" 3 "Boost Action" 4 "C2_ActiveDischarge" 5 "C2_ActiveDischargeOver" 6 "Boost Failure" 7 "Reserved";
VAL_ 485 RMCU_1_CurrentHV 2047 "Invalid";
VAL_ 485 RMCU_DampActive 0 "Not Active" 1 "Active";
VAL_ 485 RMCU_InterlockStatus 0 "Not Interlock" 1 "Interlock";
VAL_ 485 RMCU_1_SpdSvModAvl 0 "Invalid" 1 "Valid";
VAL_ 485 RMCU_1_MCUModActvSt 0 "Torque mode" 1 "Speed mode" 2 "SV mode";
VAL_ 485 RMCU_1_BSTNRelayReqAct 0 "open" 1 "closed" 2 "Stuck Open" 3 "Stuck Closed" 4 "SCB" 5 "SCG" 6 "OpenLoad";
VAL_ 485 RMCU_1_BSTPRelayReqAct 0 "open" 1 "closed" 2 "Stuck Open" 3 "Stuck Closed" 4 "SCB" 5 "SCG" 6 "OpenLoad";
VAL_ 485 RMCU_1_MCUStandstill 0 "No Standstill" 1 "Standstill";
VAL_ 485 RMCU_1_MCUVehSldSt 0 "No Slide" 1 "Slide";
VAL_ 485 RMCU_1_BoostErrLvl 0 "No Error" 1 "Err_level1" 2 "Err_level2" 3 "Err_level3" 4 "Err_level4" 5 "Err_level5" 6 "Err_level6" 7 "Reserved";
VAL_ 485 RMCU_1_BSTPrechargeRelayAct 0 "open" 1 "closed" 2 "Stuck Open" 3 "Stuck Closed" 4 "SCB" 5 "SCG" 6 "OpenLoad";
VAL_ 485 RMCU_1_NeutralGearUnavailable 0 "Available" 1 "Unavailable";
VAL_ 485 RMCU_1_GearShiftProgFlag 0 "No shift" 1 "Shift in processing" 2 "Shift success" 3 "Shift failed";
VAL_ 485 RMCU_1_GearShiftAllw 0 "Not allow shift" 1 "Allow shift";
VAL_ 485 RMCU_1_CurrGear 0 "Neutral" 1 "1st gear" 2 "2nd gear" 15 "Invalid Gear";
VAL_ 485 RMCU_1_GearSelfStudySts 0 "Default" 1 "Require study" 2 "Study in process" 3 "Study successful" 4 "Study fault" 5 "No need study";
VAL_ 485 RMCU_1_TCURErrLvlDis 0 "No Error" 1 "Err_Level1" 2 "Err_Level2" 3 "Err_Level3" 4 "Err_Level4";
VAL_ 485 RMCU_1_2ndGearUnavailable 0 "Available" 1 "Unavailable";
VAL_ 485 RMCU_1_1stGearUnavailable 0 "Available" 1 "Unavailable";
VAL_ 485 RMCU_1_LimpAllow 0 "Not Allow" 1 "Allow";
VAL_ 485 RMCU_1_ShiftReqProtd 0 "No request" 1 "Request upshift";
VAL_ 485 RMCU_1_MCUBlkSt 0 "No Stalling" 1 "Stalling";
VAL_ 485 RMCU_GBFaultstatus 0 "Not fault" 1 "GB fault" 2 "High oil over temerature" 3 "Clutch over temerature";
VAL_ 485 RMCU_1_RotorPosition 0 "Position not valid" 1 "Resolver sensor position runing" 2 "Sensorless positon running";
VAL_ 485 RMCU_1_MCUSpdSVModFlt 0 "No Error" 1 "Absolute value of output torque  too large";
VAL_ 485 RMCU_EDD_RearEDDSts 0 "init" 1 "Connected" 2 "Disconnected" 3 "ConnectFail" 4 "DisconnectFail" 5 "Moving" 6 "Reserved" 7 "Unknown";
VAL_ 485 RMCU_EDD_RearEDDConnectAllwFlg 0 "EDD don't allow Connect" 1 "EDD allow Connect";
VAL_ 504 HCU_EMS_EngineIdleSpeedMin 255 "Invalid";
VAL_ 504 HCU_EMS_EngIdleTorqueCtrl 255 "Invalid";
VAL_ 504 HCU_EMS_TqReqFast 1023 "Invalid";
VAL_ 504 HCU_EMS_TqReqSlow 1023 "Invalid";
VAL_ 504 HCU_EMS_StopReq 0 "No Stop Request" 1 "Stop Request";
VAL_ 504 HCU_EMS_ImmoSts 0 "IMMO Auth Not OK" 1 "IMMO Auth OK";
VAL_ 504 FuelCutOffInhibit 0 "Not Active" 1 "Active";
VAL_ 504 FuelCutOffEnable 0 "Not Active" 1 "Active";
VAL_ 504 AntiJerkActive 0 "Not Active" 1 "Active";
VAL_ 504 DriveSystemActive 0 "Not Active" 1 "Active";
VAL_ 504 HCU_EMS_FuelcutReq 0 "No Fuelcut Request" 1 "Fuelcut Request";
VAL_ 504 HCU_EMS_EpsOnReq 0 "Request EPS OFF" 1 "Request EPS ON";
VAL_ 504 HCU_EMS_bPepsEngRun 0 "EngSpeedPEPS=0rpm" 1 "EngSpeedPEPS=1500rpm";
VAL_ 504 EngineFastTorqReqStatus 0 "Not Active" 1 "Active";
VAL_ 504 HCU_EMS_MILReq 0 "No MIL Request" 1 "MIL Request";
VAL_ 504 CrankStartReleaseState 0 "Cranking not allowed" 1 "Cranking allowed";
VAL_ 504 HCU_EMS_SpdSet 65535 "Invalid";
VAL_ 504 EM1ActSpd 65535 "Invalid";
VAL_ 504 TransEM1TrqAct 4095 "Invalid";
VAL_ 504 HCU_EMS_SpdCtrl 0 "Not Active" 1 "Active";
VAL_ 504 EngineStartType 0 "No Start" 1 "12v Start" 2 "Clutch Start" 3 "EM Start" 4 "Combined Start";
VAL_ 504 EM1TrqMax 4095 "Invalid";
VAL_ 504 PowertrainModeAct 0 "Init" 1 "Inactive" 2 "N/P Eng Off" 3 "N/P Eng On" 4 "E-Drive-1" 5 "E-Drive-2" 6 "Series-1" 7 "Series-2" 8 "Parallel" 9 "E-Drive-3 (New enumeration, to be added in the next interface update)" 10 "Series-3 (New enumeration, to be added in the next interface update)" 11 "Engine Start" 12 "Engine Stop" 13 "C1 Closing" 14 "C1 Opening" 15 "Service";
VAL_ 504 MotorReadyFA 0 "Not Ready" 1 "Ready";
VAL_ 504 ICEReady 0 "Not Ready" 1 "Ready";
VAL_ 504 EngineSlowTorqReqStatus 0 "No request" 1 "Request active";
VAL_ 504 HCU_14_DashPotActive 0 "Not Active" 1 "Active";
VAL_ 520 BMS_C2Target_Chg_Voltage 65535 "Invalid";
VAL_ 520 BMS_NV_relay_Sts 0 "open" 1 "closed" 2 "Stuck Open" 3 "Stuck Closed" 4 "SCB" 5 "SCG" 6 "OpenLoad";
VAL_ 520 BMS_PV_relay_Sts 0 "open" 1 "closed" 2 "Stuck Open" 3 "Stuck Closed" 4 "SCB" 5 "SCG" 6 "OpenLoad";
VAL_ 520 BMS_QCP_relay_Sts 0 "open" 1 "closed" 2 "Stuck Open" 3 "Stuck Closed" 4 "SCB" 5 "SCG" 6 "OpenLoad";
VAL_ 520 BMS_Prechage_relay_Sts 0 "open" 1 "closed" 2 "Stuck Open" 3 "Stuck Closed" 4 "SCB" 5 "SCG" 6 "OpenLoad";
VAL_ 520 BMS_OutPosU 16382 "Abnormal" 16383 "Invalid";
VAL_ 520 BMS_outQCPosU 16382 "Abnormal" 16383 "Invalid";
VAL_ 522 EMS_7_EngStartInh 0 "Not Active" 1 "No StartInhibit" 2 "Start Inhibit" 3 "Reserved";
VAL_ 522 EMS_7_VentValve 0 "Open" 1 "Close" 2 "Fault";
VAL_ 522 EMS_7_AirIntakeValve 0 "Open" 1 "Close" 2 "Fault";
VAL_ 522 EMS_7_DiagcTqLimActvnFlg 0 "Not Active" 1 "Active";
VAL_ 523 BMS_HvBattPMaxReChrgLim 16382 "Error" 16383 "Init";
VAL_ 523 BMS_HvBattPMaxDchaLim 16382 "Error" 16383 "Init";
VAL_ 523 BMSH_MaxChgPwrPeak 4095 "Invalid";
VAL_ 523 BMSH_MaxDchgPwrPeak 4095 "Invalid";
VAL_ 603 FLZCU_2_PowerMode 0 "Off" 1 "Comfortable" 2 "ON" 3 "Reserved";
VAL_ 632 EngineCoolantTemperature 255 "Invalid";
VAL_ 632 IntakeAirTemperature 255 "Invalid";
VAL_ 632 EMS_4_EngineSts 0 "Not Run" 1 "Run";
VAL_ 632 IntakeAirTemperatureValidData 0 "Valid" 1 "Not valid";
VAL_ 632 ThrottlePositionValidData 0 "Valid" 1 "Not valid";
VAL_ 632 IdleSpeedInformation 0 "Non Idle" 1 "Idle";
VAL_ 632 EngineFuelCutOff 0 "Not Fuelcut" 1 "FuelCut";
VAL_ 753 Test_RMCUDesiredTorque_2F1h 4095 "Invalid";
VAL_ 753 Test_RMCURequestedState_2F1h 0 "Standby" 1 "HV Ready" 2 "Tq Control" 3 "ActiveHeat" 4 "Boost（reserved）" 5 "Power Down" 6 "Emergency Power Down" 7 "Speed Control" 8 "reserved" 9 "reserved" 10 "reserved" 11 "reserved" 12 "reserved" 13 "reserved" 14 "reserved" 15 "reserved";
VAL_ 753 Test_RMCUMaxTorqueGradient_2F1h 16383 "Invalid";
VAL_ 753 Test_RMCUMaxTorqueLimit_2F1h 4095 "Invalid";
VAL_ 753 Test_RMCUMinTorqueLimit_2F1h 4095 "Invalid";
VAL_ 753 Test_RMCUSpdSet_2F1h 65535 "Invalid";
VAL_ 753 Test_SrcSelect_2F1h 0 "整车模式" 1 "台架测试模式" 2 "reserved" 3 "reserved";
